VERSION ""

NS_ :

BS_:

BU_: WCM4 WCM3 WCM2 WCM VPM VLM VKM VICM VECM VDM VCU_RTOS_ETH VCU_ENTRY_ETH VCU_AGVM_ETH VCU UVM UPM TIM TEST_TOOL_1 TCP_ETH TCP TCM TCCM SRR_SRR_ETH SRR_SRR SRR_SLR_ETH SRR_SLR SRR_RR SRR_RF_ETH SRR_RF SRR_LR_CR SRR_LF_ETH SRR_LF SIB SDM SCL SBZA_R SBZA_L SBM SAM_RR SAM_RF SAM_LR SAM_LF SAM_BH SADS RadioLow_ETH RadioLow RSI_RTOS_ETH RSI RDCM PTM PLCM PFCM PDR_ETH PDR PCM PA ODS2 ODS NVM MTCM_R MTCM_L MSM_RR MSM_P MSM_LR MSM_D MSB2 MSB1 MRCM_R MRCM_L MFC LRR_RR_ETH LRR_LR_ETH LRR_CF_ETH LRR LRL_CF_ETH LIB_48V LIB1 IPC_INT IPC_GP IPC ICS_Info ICCM HVAC_FP_R HVAC_FP_F HUD_CAN HDLM FPI_RTOS_ETH FPI FOPM FCM_LC FCM EPSb EPS_1 EPSRAb EPSRAa EPS EOCM_HC_Superset EOCM_HCP2 EOCM ELM ECP_X1 ECP_S2 ECP_S ECP_MC ECP_H3 ECP_H2 ECP_H1 ECP_E ECM EBCM DMS DEFC DCM CSM_ETH CSM_AV CSM CGM_OTA_ETH CGM BSM_MH BSM_HEV BSM BCM ARS ARB APA AOS AMP ALC AHS AHL_AFL ADIMb ADIMa ACP2_MCU

BO_ 1940 PDU_4087: 8 CGM
 SG_ StCushFrtVertRRVirtCtlAval : 0|1@0+ (1,0) [0|1] "" VCU
 SG_ StBkSdBolsRRVirtCtlAval : 1|1@0+ (1,0) [0|1] "" VCU
 SG_ StBkLumbVertRRVirtCtlAval : 2|1@0+ (1,0) [0|1] "" VCU
 SG_ StBkLumbHrztlRRVirtCtlAval : 3|1@0+ (1,0) [0|1] "" VCU
 SG_ StBkHrztlRRVirtCtlAval : 4|1@0+ (1,0) [0|1] "" VCU
 SG_ StMasgIntstyRRVirtCtlMaxLvl : 7|3@0+ (1,0) [0|7] "" VCU
 SG_ StMasgTyp11RRVirtCtlAval : 8|1@0+ (1,0) [0|1] "" VCU
 SG_ StMasgTyp10RRVirtCtlAval : 9|1@0+ (1,0) [0|1] "" VCU
 SG_ StHdrstVertRRVirtCtlAval : 10|1@0+ (1,0) [0|1] "" VCU
 SG_ StHdrstHrztlRRVirtCtlAval : 11|1@0+ (1,0) [0|1] "" VCU
 SG_ StCushSdBolsRRVirtCtlAval : 12|1@0+ (1,0) [0|1] "" VCU
 SG_ StCushRrVertRRVirtCtlAval : 13|1@0+ (1,0) [0|1] "" VCU
 SG_ StCushLgthHrztlRRVirtCtlAval : 14|1@0+ (1,0) [0|1] "" VCU
 SG_ StCushHrztlRRVirtCtlAval : 15|1@0+ (1,0) [0|1] "" VCU
 SG_ StMasgTyp4RRVirtCtlAval : 16|1@0+ (1,0) [0|1] "" VCU
 SG_ StMasgTyp3RRVirtCtlAval : 17|1@0+ (1,0) [0|1] "" VCU
 SG_ StMasgTyp2RRVirtCtlAval : 18|1@0+ (1,0) [0|1] "" VCU
 SG_ StMasgTyp1RRVirtCtlAval : 19|1@0+ (1,0) [0|1] "" VCU
 SG_ StMasgTyp15RRVirtCtlAval : 20|1@0+ (1,0) [0|1] "" VCU
 SG_ StMasgTyp14RRVirtCtlAval : 21|1@0+ (1,0) [0|1] "" VCU
 SG_ StMasgTyp13RRVirtCtlAval : 22|1@0+ (1,0) [0|1] "" VCU
 SG_ StMasgTyp12RRVirtCtlAval : 23|1@0+ (1,0) [0|1] "" VCU
 SG_ StBkLumbHrztlRRVirtCtlAllwd : 24|1@0+ (1,0) [0|1] "" VCU
 SG_ StBkHrztlRRVirtCtlAllwd : 25|1@0+ (1,0) [0|1] "" VCU
 SG_ StUpprShldrHrztlRRVirtCtlAval : 26|1@0+ (1,0) [0|1] "" VCU
 SG_ StMasgTyp9RRVirtCtlAval : 27|1@0+ (1,0) [0|1] "" VCU
 SG_ StMasgTyp8RRVirtCtlAval : 28|1@0+ (1,0) [0|1] "" VCU
 SG_ StMasgTyp7RRVirtCtlAval : 29|1@0+ (1,0) [0|1] "" VCU
 SG_ StMasgTyp6RRVirtCtlAval : 30|1@0+ (1,0) [0|1] "" VCU
 SG_ StMasgTyp5RRVirtCtlAval : 31|1@0+ (1,0) [0|1] "" VCU
 SG_ StHdrstHrztlRRVirtCtlAllwd : 32|1@0+ (1,0) [0|1] "" VCU
 SG_ StCushSdBolsRRVirtCtlAllwd : 33|1@0+ (1,0) [0|1] "" VCU
 SG_ StCushRrVertRRVirtCtlAllwd : 34|1@0+ (1,0) [0|1] "" VCU
 SG_ StCushLgthHrztlRRVirtCtlAllwd : 35|1@0+ (1,0) [0|1] "" VCU
 SG_ StCushHrztlRRVirtCtlAllwd : 36|1@0+ (1,0) [0|1] "" VCU
 SG_ StCushFrtVertRRVirtCtlAllwd : 37|1@0+ (1,0) [0|1] "" VCU
 SG_ StBkSdBolsRRVirtCtlAllwd : 38|1@0+ (1,0) [0|1] "" VCU
 SG_ StBkLumbVertRRVirtCtlAllwd : 39|1@0+ (1,0) [0|1] "" VCU
 SG_ StMasgIntstyRRLstKnwnSet : 40|3@0+ (1,0) [0|7] "" VCU
 SG_ StMasgTypRRLstKnwnSet : 44|4@0+ (1,0) [0|15] "" VCU
 SG_ StUpprShldrHrztlRRVirtCtlAllwd : 45|1@0+ (1,0) [0|1] "" VCU
 SG_ StMasgRRVirtCtlAllwd : 46|1@0+ (1,0) [0|1] "" VCU
 SG_ StHdrstVertRRVirtCtlAllwd : 47|1@0+ (1,0) [0|1] "" VCU
 SG_ StMemRRVirtCtlNumofMemPstnsAval : 49|4@0+ (1,0) [0|8] "" VCU
 SG_ StMemRRVirtCtlNumofExtPstnsAval : 53|4@0+ (1,0) [0|8] "" VCU

BO_ 1964 PDU_4088: 8 CGM
 SG_ StCushFrtVertLRVirtCtlAval : 0|1@0+ (1,0) [0|1] "" VCU
 SG_ StBkSdBolsLRVirtCtlAval : 1|1@0+ (1,0) [0|1] "" VCU
 SG_ StBkLumbVertLRVirtCtlAval : 2|1@0+ (1,0) [0|1] "" VCU
 SG_ StBkLumbHrztlLRVirtCtlAval : 3|1@0+ (1,0) [0|1] "" VCU
 SG_ StBkHrztlLRVirtCtlAval : 4|1@0+ (1,0) [0|1] "" VCU
 SG_ StMasgIntstyLRVirtCtlMaxLvl : 7|3@0+ (1,0) [0|7] "" VCU
 SG_ StMasgTyp11LRVirtCtlAval : 8|1@0+ (1,0) [0|1] "" VCU
 SG_ StMasgTyp10LRVirtCtlAval : 9|1@0+ (1,0) [0|1] "" VCU
 SG_ StHdrstVertLRVirtCtlAval : 10|1@0+ (1,0) [0|1] "" VCU
 SG_ StHdrstHrztlLRVirtCtlAval : 11|1@0+ (1,0) [0|1] "" VCU
 SG_ StCushSdBolsLRVirtCtlAval : 12|1@0+ (1,0) [0|1] "" VCU
 SG_ StCushRrVertLRVirtCtlAval : 13|1@0+ (1,0) [0|1] "" VCU
 SG_ StCushLgthHrztlLRVirtCtlAval : 14|1@0+ (1,0) [0|1] "" VCU
 SG_ StCushHrztlLRVirtCtlAval : 15|1@0+ (1,0) [0|1] "" VCU
 SG_ StMasgTyp4LRVirtCtlAval : 16|1@0+ (1,0) [0|1] "" VCU
 SG_ StMasgTyp3LRVirtCtlAval : 17|1@0+ (1,0) [0|1] "" VCU
 SG_ StMasgTyp2LRVirtCtlAval : 18|1@0+ (1,0) [0|1] "" VCU
 SG_ StMasgTyp1LRVirtCtlAval : 19|1@0+ (1,0) [0|1] "" VCU
 SG_ StMasgTyp15LRVirtCtlAval : 20|1@0+ (1,0) [0|1] "" VCU
 SG_ StMasgTyp14LRVirtCtlAval : 21|1@0+ (1,0) [0|1] "" VCU
 SG_ StMasgTyp13LRVirtCtlAval : 22|1@0+ (1,0) [0|1] "" VCU
 SG_ StMasgTyp12LRVirtCtlAval : 23|1@0+ (1,0) [0|1] "" VCU
 SG_ StMemLRVirtCtlNumofExtPstnsAval : 25|4@0+ (1,0) [0|8] "" VCU
 SG_ StUpprShldrHrztlLRVirtCtlAval : 26|1@0+ (1,0) [0|1] "" VCU
 SG_ StMasgTyp9LRVirtCtlAval : 27|1@0+ (1,0) [0|1] "" VCU
 SG_ StMasgTyp8LRVirtCtlAval : 28|1@0+ (1,0) [0|1] "" VCU
 SG_ StMasgTyp7LRVirtCtlAval : 29|1@0+ (1,0) [0|1] "" VCU
 SG_ StMasgTyp6LRVirtCtlAval : 30|1@0+ (1,0) [0|1] "" VCU
 SG_ StMasgTyp5LRVirtCtlAval : 31|1@0+ (1,0) [0|1] "" VCU
 SG_ RrDrOpnCmfRclCstAvlFlg2 : 32|1@0+ (1,0) [0|1] "" VCU
 SG_ RrDrOpnCmfRclCstAvlFlg1 : 33|1@0+ (1,0) [0|1] "" VCU
 SG_ StMemLRVirtCtlNumofMemPstnsAval : 37|4@0+ (1,0) [0|8] "" VCU
 SG_ RrDrOpnCmfRclCstSetAval : 42|1@0+ (1,0) [0|1] "" VCU
 SG_ RrDrOpnCmfRclCstAvlFlg7 : 43|1@0+ (1,0) [0|1] "" VCU
 SG_ RrDrOpnCmfRclCstAvlFlg6 : 44|1@0+ (1,0) [0|1] "" VCU
 SG_ RrDrOpnCmfRclCstAvlFlg5 : 45|1@0+ (1,0) [0|1] "" VCU
 SG_ RrDrOpnCmfRclCstAvlFlg4 : 46|1@0+ (1,0) [0|1] "" VCU
 SG_ RrDrOpnCmfRclCstAvlFlg3 : 47|1@0+ (1,0) [0|1] "" VCU

BO_ 1295 PDU_4089: 8 CGM
 SG_ SCAOOAByVirtKeyRFCstCurrSetVal : 4|3@0+ (1,0) [0|2] "" VKM,VCU
 SG_ SCAOOAByKeyFobRFCstCurrSetVal : 7|3@0+ (1,0) [0|2] "" VCU

BO_ 1058 PDU_4091: 8 CGM
 SG_ PwrSdClsrRRBlckdIndOn : 0|1@0+ (1,0) [0|1] "" VCU
 SG_ PwrSdClsrRRServIndOn : 15|1@0+ (1,0) [0|1] "" VCU

BO_ 1406 PDU_5000: 8 AMP
 SG_ ASS_DSPMd6Prsnt : 0|1@0+ (1,0) [0|1] "" CSM,CSM_AV,VCU
 SG_ ASS_DSPMd5Prsnt : 1|1@0+ (1,0) [0|1] "" CSM,CSM_AV,VCU
 SG_ ASS_DSPMd4Prsnt : 2|1@0+ (1,0) [0|1] "" CSM,CSM_AV,VCU
 SG_ ASS_DSPMd3Prsnt : 3|1@0+ (1,0) [0|1] "" CSM,CSM_AV,VCU
 SG_ ASS_DSPMd2Prsnt : 4|1@0+ (1,0) [0|1] "" CSM,CSM_AV,VCU
 SG_ ASS_DSPMd1Prsnt : 5|1@0+ (1,0) [0|1] "" CSM,CSM_AV,VCU
 SG_ ASS_DSPMd0Prsnt : 6|1@0+ (1,0) [0|1] "" CSM,CSM_AV,VCU
 SG_ ASS_DSPAvail : 7|1@0+ (1,0) [0|1] "" CSM,CSM_AV,VCU
 SG_ CrtclChmPrdcrStat : 10|12@0+ (1,0) [0|4095] "msec" RadioLow,CSM,CSM_AV,IPC,IPC_INT,VCU
 SG_ ASS_VehNoisCmpnAvail : 11|1@0+ (1,0) [0|1] "" CSM,CSM_AV,VCU
 SG_ ASS_SurndAvail : 12|1@0+ (1,0) [0|1] "" CSM,CSM_AV,VCU
 SG_ ASS_PhLckdLpLckd : 13|1@0+ (1,0) [0|1] "" CSM,CSM_AV,VCU
 SG_ ASS_MtxSnkMutStat : 14|1@0+ (1,0) [0|1] "" CSM,CSM_AV,VCU
 SG_ ASS_DSPMd7Prsnt : 15|1@0+ (1,0) [0|1] "" CSM,CSM_AV,VCU
 SG_ FrtPsngrMtxSnkMutSts : 24|1@0+ (1,0) [0|1] "" CSM,CSM_AV,VCU
 SG_ CCSI_PV : 26|2@0+ (1,0) [0|3] "" IPC,IPC_INT,VCU
 SG_ CCSI_CrtclChmPrdcrSOH : 28|2@0+ (1,0) [0|2] "" IPC,IPC_INT,VCU
 SG_ CCSI_ARC : 30|2@0+ (1,0) [0|3] "" IPC,IPC_INT,VCU
 SG_ AmpSOHALAudblFbkSnkLvlCurrVal : 35|8@0+ (0.5,-127.5) [-127.5|0] "dB" VCU
 SG_ AmpCallAudPlybkSOH : 37|2@0+ (1,0) [0|2] "" VCU
 SG_ RRMtxSnkMutSts : 38|1@0+ (1,0) [0|1] "" CSM,CSM_AV,VCU
 SG_ LRMtxSnkMutSts : 39|1@0+ (1,0) [0|1] "" CSM,CSM_AV,VCU
 SG_ AmpSOHALMixPrmtSnkLvlCurrVal : 43|8@0+ (0.5,-127.5) [-127.5|0] "dB" VCU
 SG_ AmpSOHALMtxSnkLvlCurrVal : 51|8@0+ (0.5,-127.5) [-127.5|0] "dB" VCU
 SG_ AmpSOHALAutoLdnsCmpnAtv : 56|1@0+ (1,0) [0|1] "" VCU
 SG_ AmpSOHALMutCaus : 59|3@0+ (1,0) [0|3] "" VCU

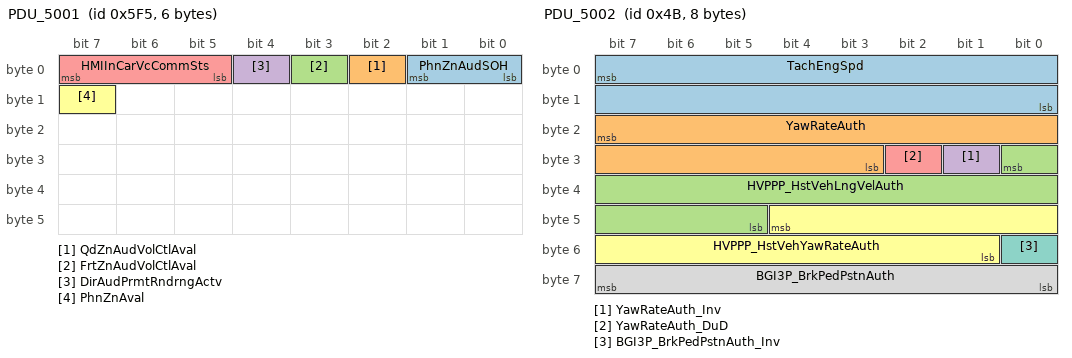
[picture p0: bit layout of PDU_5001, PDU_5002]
BO_ 1525 PDU_5001: 6 AMP
 SG_ PhnZnAudSOH : 1|2@0+ (1,0) [0|2] "" VCU
 SG_ QdZnAudVolCtlAval : 2|1@0+ (1,0) [0|1] "" VCU
 SG_ FrtZnAudVolCtlAval : 3|1@0+ (1,0) [0|1] "" VCU
 SG_ DirAudPrmtRndrngActv : 4|1@0+ (1,0) [0|1] "" CSM,CSM_AV,VCU
 SG_ HMIInCarVcCommSts : 7|3@0+ (1,0) [0|7] "" CSM,CSM_AV,VCU
 SG_ PhnZnAval : 15|1@0+ (1,0) [0|1] "" VCU

BO_ 75 PDU_5002: 8 CGM
 SG_ TachEngSpd : 7|16@0+ (0.25,0) [0|16383.8] "RPM" AMP,IPC,IPC_INT,VCU
 SG_ YawRateAuth : 23|13@0- (0.024,0) [-98.304|98.28] "Deg/Sec" PDR,TCP,CSM,CSM_AV,IPC,VCU
 SG_ HVPPP_HstVehLngVelAuth : 24|12@0+ (0.0625,-128) [-128|127.938] "m/s" CSM,CSM_AV,VCU
 SG_ YawRateAuth_Inv : 25|1@0+ (1,0) [0|1] "" PDR,TCP,CSM,CSM_AV,IPC,VCU
 SG_ YawRateAuth_DuD : 26|1@0+ (1,0) [0|1] "" TCP,CSM,CSM_AV,VCU
 SG_ HVPPP_HstVehYawRateAuth : 44|12@0+ (0.0625,-128) [-128|127.938] "deg/s" CSM,CSM_AV,VCU
 SG_ BGI3P_BrkPedPstnAuth_Inv : 48|1@0+ (1,0) [0|1] "" PDR,CSM,CSM_AV,VCU
 SG_ BGI3P_BrkPedPstnAuth : 63|8@0+ (0.392157,0) [0|100] "%" PDR,CSM,CSM_AV,VCU

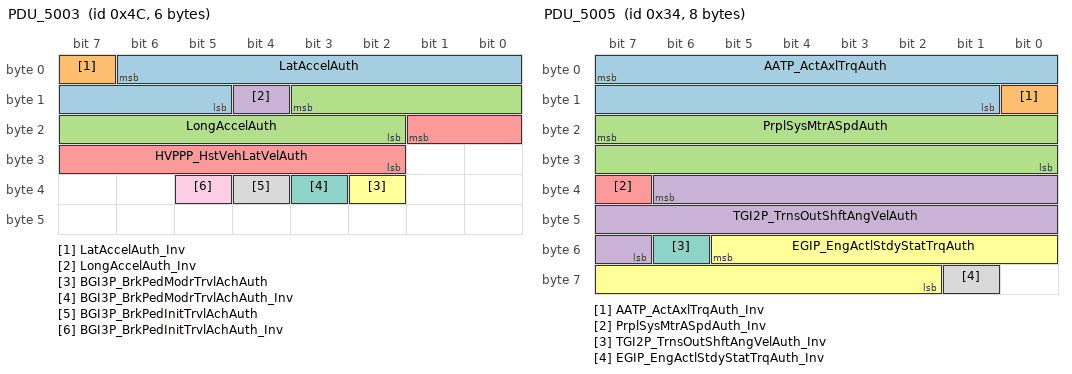
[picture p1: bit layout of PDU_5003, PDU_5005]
BO_ 76 PDU_5003: 6 CGM
 SG_ LatAccelAuth : 6|10@0- (0.0625,0) [-32|31.9375] "m/s^2" PDR,TCP,VKM,CSM,CSM_AV,IPC,VCU
 SG_ LatAccelAuth_Inv : 7|1@0+ (1,0) [0|1] "" PDR,TCP,VKM,CSM,CSM_AV,IPC,VCU
 SG_ LongAccelAuth : 11|10@0- (0.0625,0) [-32|31.9375] "m/s^2" AMP,PDR,TCP,CSM,CSM_AV,IPC,VCU
 SG_ LongAccelAuth_Inv : 12|1@0+ (1,0) [0|1] "" PDR,TCP,CSM,CSM_AV,IPC,VCU
 SG_ HVPPP_HstVehLatVelAuth : 17|8@0+ (0.05,-6.4) [-6.4|6.35] "m/s" CSM,CSM_AV,VCU
 SG_ BGI3P_BrkPedModrTrvlAchAuth : 34|1@0+ (1,0) [0|1] "" VKM,CSM,CSM_AV,VCU
 SG_ BGI3P_BrkPedModrTrvlAchAuth_Inv : 35|1@0+ (1,0) [0|1] "" VKM,CSM,CSM_AV,VCU
 SG_ BGI3P_BrkPedInitTrvlAchAuth : 36|1@0+ (1,0) [0|1] "" TCP,VKM,CSM,CSM_AV,VCU
 SG_ BGI3P_BrkPedInitTrvlAchAuth_Inv : 37|1@0+ (1,0) [0|1] "" VKM,CSM,CSM_AV,VCU

BO_ 41 PDU_5004: 8 CGM
 SG_ VCBA_FrtJnctnActv : 0|1@0+ (1,0) [0|1] "" CSM,CSM_AV,VCU
 SG_ VCBA_DynGdlnsActv : 1|1@0+ (1,0) [0|1] "" CSM,CSM_AV,VCU
 SG_ VCBA_CurbVwGdlnsActv : 2|1@0+ (1,0) [0|1] "" CSM,CSM_AV,VCU
 SG_ VCBA_CurbOvrhdActv : 3|1@0+ (1,0) [0|1] "" CSM,CSM_AV,VCU
 SG_ VCBA_CurbActv : 4|1@0+ (1,0) [0|1] "" CSM,CSM_AV,VCU
 SG_ VCBA_CrgBedActv : 5|1@0+ (1,0) [0|1] "" CSM,CSM_AV,VCU
 SG_ VCBA_BowlActv : 6|1@0+ (1,0) [0|1] "" CSM,CSM_AV,VCU
 SG_ VCBA_BedHtchActv : 7|1@0+ (1,0) [0|1] "" CSM,CSM_AV,VCU
 SG_ VCBA_RrOvrhdActv : 8|1@0+ (1,0) [0|1] "" CSM,CSM_AV,VCU
 SG_ VCBA_RrJnctnActv : 9|1@0+ (1,0) [0|1] "" CSM,CSM_AV,VCU
 SG_ VCBA_RrHtchActv : 10|1@0+ (1,0) [0|1] "" CSM,CSM_AV,VCU
 SG_ VCBA_LRTrlrTowMirActv : 11|1@0+ (1,0) [0|1] "" CSM,CSM_AV,VCU
 SG_ VCBA_JPActv : 12|1@0+ (1,0) [0|1] "" CSM,CSM_AV,VCU
 SG_ VCBA_InvsblTrlrActv : 13|1@0+ (1,0) [0|1] "" CSM,CSM_AV,VCU
 SG_ VCBA_FrtPrspctvActv : 14|1@0+ (1,0) [0|1] "" CSM,CSM_AV,VCU
 SG_ VCBA_FrtOvrhdActv : 15|1@0+ (1,0) [0|1] "" CSM,CSM_AV,VCU
 SG_ VCBA_TrlrTowMirActv : 16|1@0+ (1,0) [0|1] "" CSM,CSM_AV,VCU
 SG_ VCBA_TrlrGdlnsActv : 17|1@0+ (1,0) [0|1] "" CSM,CSM_AV,VCU
 SG_ VCBA_TrlrAux2Actv : 18|1@0+ (1,0) [0|1] "" CSM,CSM_AV,VCU
 SG_ VCBA_TrlrAux1CmbdActv : 19|1@0+ (1,0) [0|1] "" CSM,CSM_AV,VCU
 SG_ VCBA_TrlrAux1Actv : 20|1@0+ (1,0) [0|1] "" CSM,CSM_AV,VCU
 SG_ VCBA_SdRrwdActv : 21|1@0+ (1,0) [0|1] "" CSM,CSM_AV,VCU
 SG_ VCBA_SdFrwdActv : 22|1@0+ (1,0) [0|1] "" CSM,CSM_AV,VCU
 SG_ VCBA_RrPrspctvActv : 23|1@0+ (1,0) [0|1] "" CSM,CSM_AV,VCU
 SG_ VwgBowlVwAngSts : 29|9@0+ (1,0) [0|511] "degrees" CSM,CSM_AV,VCU
 SG_ VCBA_ZmdBowlActv : 30|1@0+ (1,0) [0|1] "" CSM,CSM_AV,VCU
 SG_ VCBA_TrnspHdActv : 31|1@0+ (1,0) [0|1] "" CSM,CSM_AV,VCU
 SG_ SrrndVsnRcrdrNumDispdFiles : 33|3@0+ (1,0) [0|7] "" CSM,CSM_AV,VCU
 SG_ SrrndVsnRcrdrDelFileReqSts : 36|3@0+ (1,0) [0|7] "" CSM,CSM_AV,VCU
 SG_ SrrndVsnRcrdrVwprtSts : 40|3@0+ (1,0) [0|7] "" CSM,CSM_AV,VCU
 SG_ SrrndVsnRcrdrVwprtReq : 43|3@0+ (1,0) [0|7] "" CSM,CSM_AV,VCU
 SG_ SrrndVsnRcrdrPlybkSts : 46|3@0+ (1,0) [0|5] "" CSM,CSM_AV,VCU
 SG_ SrrndVsnRcrdrRcrdSts : 48|2@0+ (1,0) [0|2] "" CSM,CSM_AV,VCU
 SG_ SrrndVsnRcrdrListPgSts : 50|2@0+ (1,0) [0|3] "" CSM,CSM_AV,VCU
 SG_ VGVS_TrlrActv : 51|1@0+ (1,0) [0|1] "" CSM,CSM_AV,VCU
 SG_ VGVS_DynActv : 52|1@0+ (1,0) [0|1] "" CSM,CSM_AV,VCU
 SG_ VGVS_CurbVwActv : 53|1@0+ (1,0) [0|1] "" CSM,CSM_AV,VCU
 SG_ SrrndVsnRcrdrRcrdgActv : 59|1@0+ (1,0) [0|1] "" CSM,CSM_AV,VCU
 SG_ ClsnEvntDatRcrdgTrgrd : 60|1@0+ (1,0) [0|1] "" TCP
 SG_ SVRCBA_PgUpActv : 61|1@0+ (1,0) [0|1] "" CSM,CSM_AV,VCU
 SG_ SVRCBA_PgDnActv : 62|1@0+ (1,0) [0|1] "" CSM,CSM_AV,VCU

BO_ 52 PDU_5005: 8 CGM
 SG_ AATP_ActAxlTrqAuth : 7|15@0+ (2,-22534) [-22534|43000] "Nm" AMP,CSM,CSM_AV,VCU
 SG_ AATP_ActAxlTrqAuth_Inv : 8|1@0+ (1,0) [0|1] "" AMP,CSM,CSM_AV,VCU
 SG_ PrplSysMtrASpdAuth : 23|16@0- (1,0) [-32768|32767] "RPM" AMP,VCU
 SG_ TGI2P_TrnsOutShftAngVelAuth : 38|16@0+ (0.25,0) [0|16383.8] "rpm" AMP,RadioLow,VCU
 SG_ PrplSysMtrASpdAuth_Inv : 39|1@0+ (1,0) [0|1] "" AMP,VCU
 SG_ EGIP_EngActlStdyStatTrqAuth : 53|12@0+ (0.5,-848) [-848|1199.5] "Nm" AMP,PDR,RadioLow,CSM,CSM_AV,IPC,IPC_INT,VCU
 SG_ TGI2P_TrnsOutShftAngVelAuth_Inv : 54|1@0+ (1,0) [0|1] "" AMP,VCU
 SG_ EGIP_EngActlStdyStatTrqAuth_Inv : 57|1@0+ (1,0) [0|1] "" AMP,PDR,CSM,CSM_AV,IPC,IPC_INT,VCU

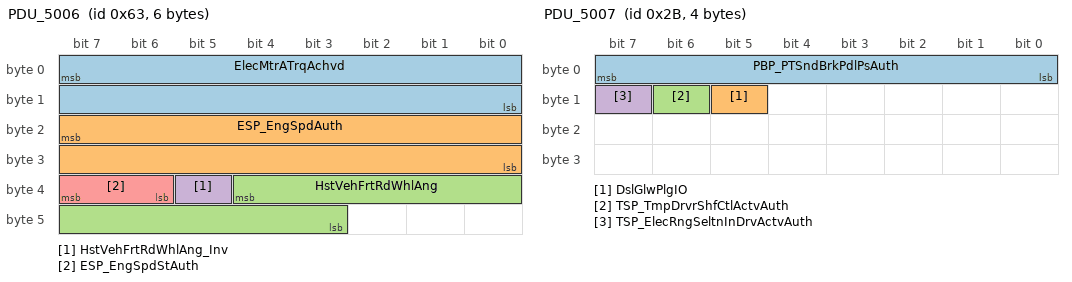
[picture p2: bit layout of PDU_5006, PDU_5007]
BO_ 99 PDU_5006: 6 CGM
 SG_ ElecMtrATrqAchvd : 7|16@0- (0.125,0) [-4096|4095.88] "Nm" AMP,VCU
 SG_ ESP_EngSpdAuth : 23|16@0+ (0.25,0) [0|16383.8] "rpm" AMP,PDR,RadioLow,TCP,CSM,CSM_AV,IPC,IPC_INT,VCU
 SG_ HstVehFrtRdWhlAng : 36|10@0- (0.004363,0) [-2.23386|2.22949] "Rad" RadioLow,CSM,VCU
 SG_ HstVehFrtRdWhlAng_Inv : 37|1@0+ (1,0) [0|1] "" RadioLow,CSM,VCU
 SG_ ESP_EngSpdStAuth : 39|2@0+ (1,0) [0|2] "" AMP,RadioLow,CSM,CSM_AV,IPC,IPC_INT,VCU

BO_ 43 PDU_5007: 4 CGM
 SG_ PBP_PTSndBrkPdlPsAuth : 7|8@0+ (0.392157,0) [0|100] "%" TCP
 SG_ DslGlwPlgIO : 13|1@0+ (1,0) [0|1] "" CSM,CSM_AV,IPC,IPC_INT,VCU
 SG_ TSP_TmpDrvrShfCtlActvAuth : 14|1@0+ (1,0) [0|1] "" IPC,IPC_INT,VCU
 SG_ TSP_ElecRngSeltnInDrvActvAuth : 15|1@0+ (1,0) [0|1] "" IPC,IPC_INT,VCU

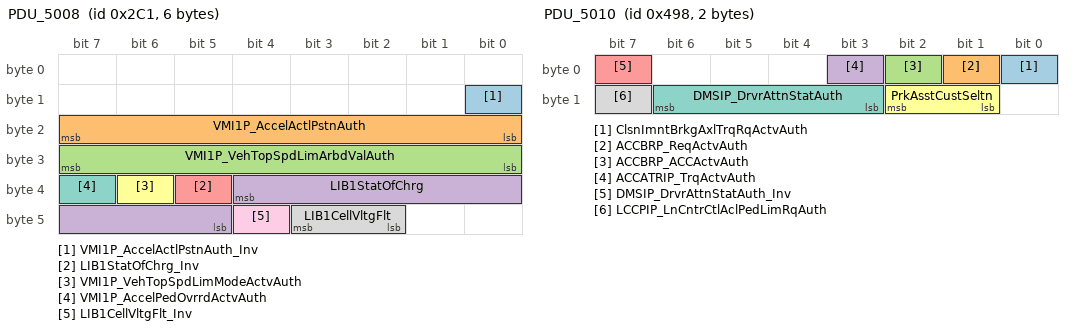
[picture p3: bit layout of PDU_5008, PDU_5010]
BO_ 705 PDU_5008: 6 CGM
 SG_ VMI1P_AccelActlPstnAuth_Inv : 8|1@0+ (1,0) [0|1] "" AMP,PDR,CSM,CSM_AV,VCU
 SG_ VMI1P_AccelActlPstnAuth : 23|8@0+ (0.392157,0) [0|100] "%" AMP,PDR,TCP,CSM,CSM_AV,VCU
 SG_ VMI1P_VehTopSpdLimArbdValAuth : 31|8@0+ (2,0) [0|510] "km / h" CSM,CSM_AV,IPC,IPC_INT,VCU
 SG_ LIB1StatOfChrg : 36|8@0+ (0.39,0) [0|99.45] "%" CSM,VCU
 SG_ LIB1StatOfChrg_Inv : 37|1@0+ (1,0) [0|1] "" CSM,VCU
 SG_ VMI1P_VehTopSpdLimModeActvAuth : 38|1@0+ (1,0) [0|1] "" CSM,CSM_AV,IPC,IPC_INT,VCU
 SG_ VMI1P_AccelPedOvrrdActvAuth : 39|1@0+ (1,0) [0|1] "" CSM,CSM_AV,IPC,IPC_INT,VCU
 SG_ LIB1CellVltgFlt : 43|2@0+ (1,0) [0|3] "" CSM,VCU
 SG_ LIB1CellVltgFlt_Inv : 44|1@0+ (1,0) [0|1] "" CSM,VCU

BO_ 204 PDU_5009: 4 CGM
 SG_ RdLdNomAxlTrq : 7|19@0+ (0.125,-22534) [-22534|43001.9] "Nm" CSM,CSM_AV,VCU

BO_ 1176 PDU_5010: 2 CGM
 SG_ ClsnImntBrkgAxlTrqRqActvAuth : 0|1@0+ (1,0) [0|1] "" TCP
 SG_ ACCBRP_ReqActvAuth : 1|1@0+ (1,0) [0|1] "" TCP
 SG_ ACCBRP_ACCActvAuth : 2|1@0+ (1,0) [0|1] "" IPC,IPC_INT,VCU
 SG_ ACCATRIP_TrqActvAuth : 3|1@0+ (1,0) [0|1] "" TCP
 SG_ DMSIP_DrvrAttnStatAuth_Inv : 7|1@0+ (1,0) [0|1] "" TCP
 SG_ PrkAsstCustSeltn : 10|2@0+ (1,0) [0|2] "" VCU
 SG_ DMSIP_DrvrAttnStatAuth : 14|4@0+ (1,0) [0|11] "" TCP
 SG_ LCCPIP_LnCntrCtlAclPedLimRqAuth : 15|1@0+ (1,0) [0|1] "" TCP

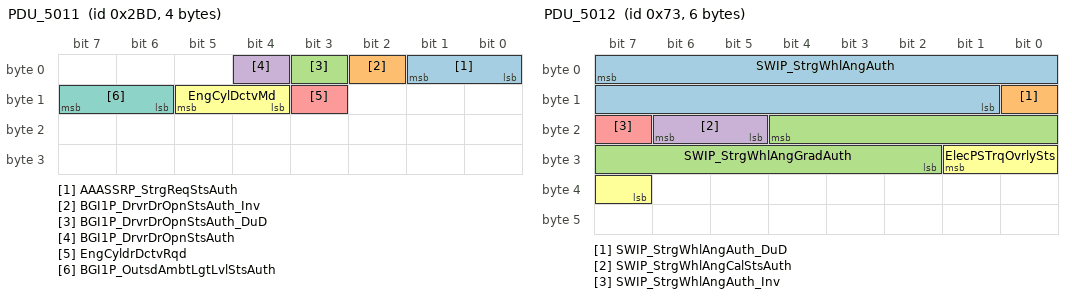
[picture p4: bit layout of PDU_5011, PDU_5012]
BO_ 701 PDU_5011: 4 CGM
 SG_ AAASSRP_StrgReqStsAuth : 1|2@0+ (1,0) [0|2] "" TCP
 SG_ BGI1P_DrvrDrOpnStsAuth_Inv : 2|1@0+ (1,0) [0|1] "" TCP,CSM,CSM_AV,VCU
 SG_ BGI1P_DrvrDrOpnStsAuth_DuD : 3|1@0+ (1,0) [0|1] "" CSM,CSM_AV,VCU
 SG_ BGI1P_DrvrDrOpnStsAuth : 4|1@0+ (1,0) [0|1] "" TCP,CSM,CSM_AV,VCU
 SG_ EngCyldrDctvRqd : 11|1@0+ (1,0) [0|1] "" RadioLow,VCU
 SG_ EngCylDctvMd : 13|2@0+ (1,0) [0|3] "" AMP,RadioLow,CSM,CSM_AV,IPC,IPC_INT,VCU
 SG_ BGI1P_OutsdAmbtLgtLvlStsAuth : 15|2@0+ (1,0) [0|2] "" CSM,CSM_AV,IPC,IPC_INT,VCU

BO_ 115 PDU_5012: 6 CGM
 SG_ SWIP_StrgWhlAngAuth : 7|15@0- (0.0625,0) [-1024|1023.94] "deg" PDR,RadioLow,TCP,VKM,CSM,CSM_AV,VCU
 SG_ SWIP_StrgWhlAngAuth_DuD : 8|1@0+ (1,0) [0|1] "" PDR,RadioLow,TCP,VKM,CSM,VCU
 SG_ SWIP_StrgWhlAngGradAuth : 20|11@0- (2,0) [-2048|2046] "deg/s" TCP,VKM,CSM,CSM_AV,VCU
 SG_ SWIP_StrgWhlAngCalStsAuth : 22|2@0+ (1,0) [0|2] "" RadioLow,TCP,VKM,CSM,CSM_AV,VCU
 SG_ SWIP_StrgWhlAngAuth_Inv : 23|1@0+ (1,0) [0|1] "" PDR,RadioLow,TCP,VKM,CSM,VCU
 SG_ ElecPSTrqOvrlySts : 25|3@0+ (1,0) [0|5] "" TCP

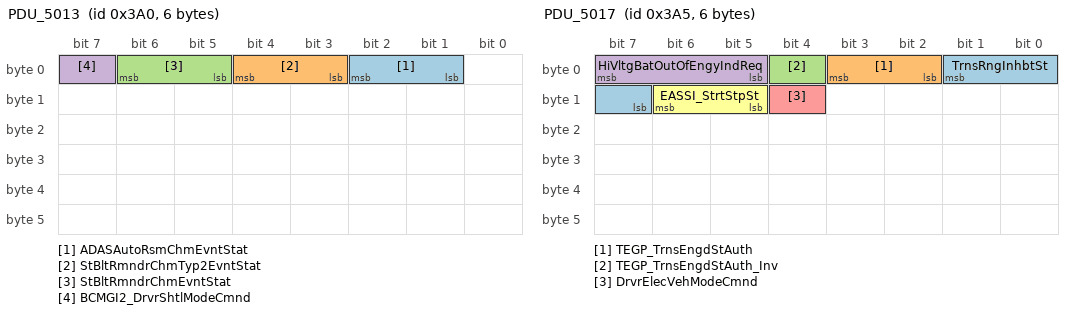
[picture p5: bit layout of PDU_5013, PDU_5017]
BO_ 928 PDU_5013: 6 CGM
 SG_ ADASAutoRsmChmEvntStat : 2|2@0+ (1,0) [0|2] "" IPC,IPC_INT,VCU
 SG_ StBltRmndrChmTyp2EvntStat : 4|2@0+ (1,0) [0|2] "" CSM,CSM_AV,IPC,IPC_INT,VCU
 SG_ StBltRmndrChmEvntStat : 6|2@0+ (1,0) [0|2] "" CSM,CSM_AV,IPC,IPC_INT,VCU
 SG_ BCMGI2_DrvrShtlModeCmnd : 7|1@0+ (1,0) [0|1] "" AMP,CSM,CSM_AV,IPC,IPC_INT,VCU

BO_ 703 PDU_5014: 8 CGM
 SG_ BVSCRP_CPSAxlTrqCmdReqStsAuth : 0|3@0+ (1,0) [0|6] "" CSM,CSM_AV,IPC,IPC_INT,VCU
 SG_ BVSCRP_CPSAxlTrqCmdLimStsAuth : 2|2@0+ (1,0) [0|3] "" CSM,CSM_AV,IPC,IPC_INT,VCU
 SG_ BVSCRP_ACCAxlTrqCmdReqStsAuth : 5|3@0+ (1,0) [0|4] "" TCP,CSM,CSM_AV,IPC,IPC_INT,VCU
 SG_ BVSCRP_ACCAxlTrqCmdLimStsAuth : 7|2@0+ (1,0) [0|3] "" CSM,CSM_AV,IPC,IPC_INT,VCU
 SG_ BVSCRP_CltchPdlActPosAuth : 13|8@0+ (0.392157,0) [0|100] "" AMP,PDR,TCP,CSM,CSM_AV,IPC,IPC_INT,VCU
 SG_ CruzCtlActvAuth : 16|1@0+ (1,0) [0|1] "" CSM,CSM_AV,IPC,IPC_INT,VCU
 SG_ CnvntlCruzCtlIndReqAuth : 19|3@0+ (1,0) [0|5] "" CSM,CSM_AV,IPC,IPC_INT,VCU
 SG_ BVSCRP_CruzCtlEnbldAuth : 20|1@0+ (1,0) [0|1] "" CSM,CSM_AV,IPC,IPC_INT,VCU
 SG_ BVSCRP_CltchPdlActPosAuth_Inv : 21|1@0+ (1,0) [0|1] "" AMP,PDR,TCP,CSM,CSM_AV,IPC,IPC_INT,VCU
 SG_ CruzSpdLmtrDrvrSeltdSpdAuth : 31|12@0+ (0.0625,0) [0|255.938] "km / h" CSM,CSM_AV,IPC,IPC_INT,VCU
 SG_ DrSeltdSpdLmtrSetSpdLimRchdAuth : 33|2@0+ (1,0) [0|3] "" TCP,CSM,CSM_AV,IPC,IPC_INT,VCU
 SG_ DrSeltdSpdLmtrAutoMdSpLmStsAuth : 35|2@0+ (1,0) [0|3] "" TCP,CSM,CSM_AV,IPC,IPC_INT,VCU
 SG_ SpdLmtrSpdLimSgnValAuth : 41|8@0+ (1,0) [0|255] "" CSM,CSM_AV,IPC,IPC_INT,VCU
 SG_ SpdLmtrSpdLimSgnUntAuth : 42|1@0+ (1,0) [0|1] "" CSM,CSM_AV,IPC,IPC_INT,VCU
 SG_ PABRP_VehTopSpdLimArbdStatAuth : 44|2@0+ (1,0) [0|2] "" CSM,CSM_AV,IPC,IPC_INT,VCU
 SG_ EGI2P_PwrtrnCrnkActvAuth : 45|1@0+ (1,0) [0|1] "" TCP,CSM,CSM_AV,IPC,IPC_INT,VCU
 SG_ DrSeltdSpdLmtrSetTypActvAuth : 47|2@0+ (1,0) [0|3] "" TCP,CSM,CSM_AV,IPC,IPC_INT,VCU
 SG_ BrkPdlDrvAppPrsDetcdAuth : 48|1@0+ (1,0) [0|1] "" TCP,CSM,CSM_AV,VCU
 SG_ BrkPdlDrvAppPrsDetcdAuth_Inv : 49|1@0+ (1,0) [0|1] "" TCP,CSM,CSM_AV,VCU
 SG_ Bat12VCfg : 58|3@0+ (1,0) [0|7] "" CSM,VCU
 SG_ ETRPP_ElcTransRngPriAuth : 61|3@0+ (1,0) [0|6] "" RadioLow,CSM,VCU
 SG_ BSIS2P_ABSFldAuth : 62|1@0+ (1,0) [0|1] "" TCP,CSM,CSM_AV,VCU
 SG_ BSIS2P_ABSAtvAuth : 63|1@0+ (1,0) [0|1] "" PDR,RadioLow,TCP,CSM,CSM_AV,VCU

BO_ 704 PDU_5015: 4 CGM
 SG_ BSIS2P_BrkPdlDrvApplPresAuth : 6|10@0+ (20,0) [0|20460] "kPa" PDR,TCP,CSM,CSM_AV,VCU
 SG_ BSIS2P_BrkPdlDrvApplPresAuth_Inv : 7|1@0+ (1,0) [0|1] "" PDR,TCP,CSM,CSM_AV,VCU

BO_ 932 PDU_5016: 8 CGM
 SG_ BVSCP_BdyCtlTopSpdLimReqValAuth : 7|8@0+ (1,0) [0|255] "kph" IPC,IPC_INT,VCU
 SG_ CTGI1P_CnvtTpSpLimRqValAuth : 10|8@0+ (2,0) [0|510] "kph" IPC,IPC_INT,VCU
 SG_ BdyCtlTopSpdLimSrcAuth : 13|3@0+ (1,0) [0|7] "" IPC,IPC_INT,VCU
 SG_ BdyCtlTopSpdLimIndOnAuth : 14|1@0+ (1,0) [0|1] "" IPC,IPC_INT,VCU
 SG_ BdyCtlAccelLimIndOnAuth : 15|1@0+ (1,0) [0|1] "" IPC,IPC_INT,VCU
 SG_ DeadFrntSwtchIllumLvl : 17|7@0+ (1,0) [0|127] "%" HVAC_FP_F,HVAC_FP_R,MFC,RadioLow,CSM,CSM_AV,VCU
 SG_ CnvtTopModSpdLimIndOnAuth : 18|1@0+ (1,0) [0|1] "" IPC,IPC_INT,VCU
 SG_ IntDimDspLvl : 26|7@0+ (1,0) [0|127] "%" HVAC_FP_F,HVAC_FP_R,MFC,RadioLow,CSM,CSM_AV,IPC,IPC_INT,VCU
 SG_ IntDimLvl : 35|7@0+ (1,0) [0|127] "%" HVAC_FP_F,HVAC_FP_R,MFC,RadioLow,CSM,CSM_AV,IPC,IPC_INT,VCU
 SG_ DrvShftCntrlTrgtGr : 43|4@0+ (1,0) [0|10] "" CSM,CSM_AV,IPC,IPC_INT,VCU
 SG_ DrvShftCntrlReqDndIO : 44|1@0+ (1,0) [0|1] "" CSM,CSM_AV,IPC,IPC_INT,VCU
 SG_ TEGP_TrnsShftLvrPstnAuth_Inv : 48|1@0+ (1,0) [0|1] "" RadioLow,TCP,VKM,CSM,CSM_AV,IPC,IPC_INT,VCU
 SG_ TEGP_TrnsEstGrAuth : 52|4@0+ (1,0) [0|15] "" AMP,ICS_Info,PDR,TCP,CSM,CSM_AV,IPC,IPC_INT,VCU
 SG_ TEGP_TrnsEstGrAuth_Inv : 53|1@0+ (1,0) [0|1] "" AMP,PDR,TCP,CSM,CSM_AV,IPC,IPC_INT,VCU
 SG_ TrnsTUTDMdSt : 55|2@0+ (1,0) [0|2] "" CSM,CSM_AV,IPC,IPC_INT,VCU
 SG_ TEGP_TransCmndGrAuth : 59|4@0+ (1,0) [0|15] "" AMP,TCP,CSM,CSM_AV,IPC,IPC_INT,VCU
 SG_ TEGP_TrnsShftLvrPstnAuth : 63|4@0+ (1,0) [0|14] "" RadioLow,TCP,VKM,CSM,CSM_AV,IPC,IPC_INT,VCU

BO_ 933 PDU_5017: 6 CGM
 SG_ TrnsRngInhbtSt : 1|3@0+ (1,0) [0|4] "" CSM,CSM_AV,VCU
 SG_ TEGP_TrnsEngdStAuth : 3|2@0+ (1,0) [0|3] "" AMP,TCP,CSM,CSM_AV,IPC,IPC_INT,VCU
 SG_ TEGP_TrnsEngdStAuth_Inv : 4|1@0+ (1,0) [0|1] "" AMP,TCP,CSM,CSM_AV,IPC,IPC_INT,VCU
 SG_ HiVltgBatOutOfEngyIndReq : 7|3@0+ (1,0) [0|4] "" FPI,RSI,CSM,CSM_AV,IPC,IPC_INT,VCU
 SG_ DrvrElecVehModeCmnd : 12|1@0+ (1,0) [0|1] "" AMP,PDR,CSM,CSM_AV,IPC,IPC_INT,VCU
 SG_ EASSI_StrtStpSt : 14|2@0+ (1,0) [0|3] "" AMP,PDR,RadioLow,IPC,IPC_INT,VCU

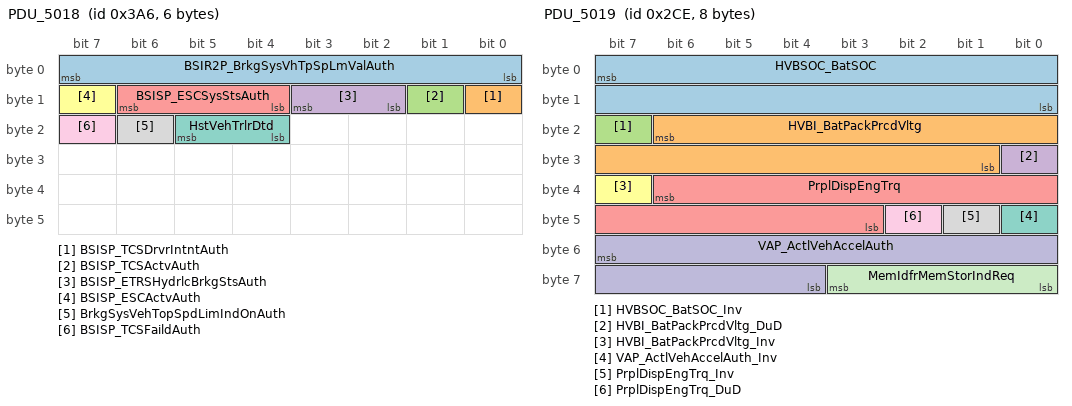
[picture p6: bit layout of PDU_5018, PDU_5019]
BO_ 934 PDU_5018: 6 CGM
 SG_ BSIR2P_BrkgSysVhTpSpLmValAuth : 7|8@0+ (2,0) [0|510] "kph" IPC,IPC_INT,VCU
 SG_ BSISP_TCSDrvrIntntAuth : 8|1@0+ (1,0) [0|1] "" TCP,CSM,CSM_AV,VCU
 SG_ BSISP_TCSActvAuth : 9|1@0+ (1,0) [0|1] "" PDR,RadioLow,TCP,CSM,CSM_AV,VCU
 SG_ BSISP_ETRSHydrlcBrkgStsAuth : 11|2@0+ (1,0) [0|2] "" CSM,CSM_AV,VCU
 SG_ BSISP_ESCSysStsAuth : 14|3@0+ (1,0) [0|4] "" CSM,CSM_AV,VCU
 SG_ BSISP_ESCActvAuth : 15|1@0+ (1,0) [0|1] "" PDR,RadioLow,TCP,CSM,CSM_AV,VCU
 SG_ HstVehTrlrDtd : 21|2@0+ (1,0) [0|3] "" TCP
 SG_ BrkgSysVehTopSpdLimIndOnAuth : 22|1@0+ (1,0) [0|1] "" IPC,IPC_INT,VCU
 SG_ BSISP_TCSFaildAuth : 23|1@0+ (1,0) [0|1] "" TCP,CSM,CSM_AV,VCU

BO_ 718 PDU_5019: 8 CGM
 SG_ HVBSOC_BatSOC : 7|16@0+ (0.0015259,0) [0|100] "%" VKM,CSM,CSM_AV,VCU
 SG_ HVBI_BatPackPrcdVltg : 22|14@0+ (0.0624,0) [0|1022.3] "V" CSM,CSM_AV,VCU
 SG_ HVBSOC_BatSOC_Inv : 23|1@0+ (1,0) [0|1] "" VKM,CSM,CSM_AV,VCU
 SG_ HVBI_BatPackPrcdVltg_DuD : 24|1@0+ (1,0) [0|1] "" CSM,CSM_AV,VCU
 SG_ PrplDispEngTrq : 38|12@0+ (0.5,-848) [-848|1199.5] "Nm" PDR,CSM,CSM_AV,VCU
 SG_ HVBI_BatPackPrcdVltg_Inv : 39|1@0+ (1,0) [0|1] "" CSM,CSM_AV,VCU
 SG_ VAP_ActlVehAccelAuth_Inv : 40|1@0+ (1,0) [0|1] "" TCP,IPC,IPC_INT,VCU
 SG_ PrplDispEngTrq_Inv : 41|1@0+ (1,0) [0|1] "" CSM,CSM_AV,VCU
 SG_ PrplDispEngTrq_DuD : 42|1@0+ (1,0) [0|1] "" CSM,CSM_AV,VCU
 SG_ VAP_ActlVehAccelAuth : 55|12@0- (0.01,0) [-20.48|20.47] "m/s^2" TCP,IPC,IPC_INT,VCU
 SG_ MemIdfrMemStorIndReq : 59|4@0+ (1,0) [0|8] "" IPC,IPC_INT,VCU

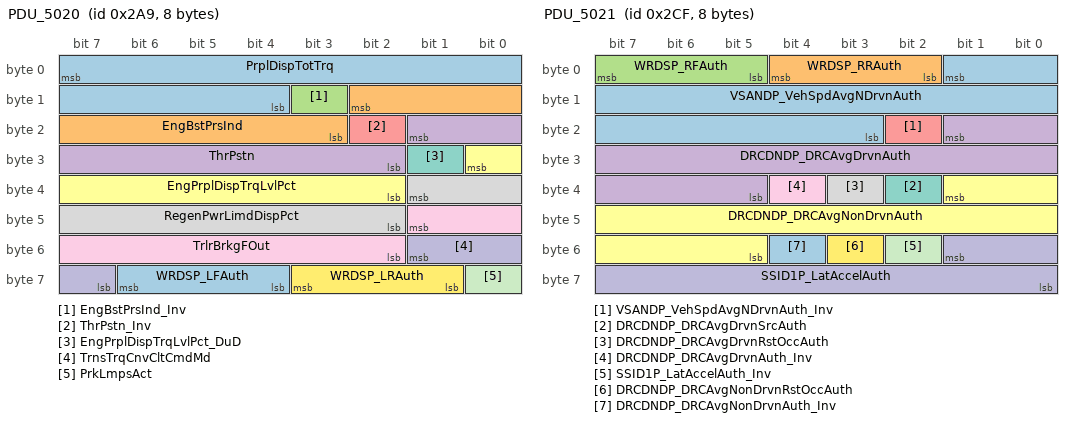
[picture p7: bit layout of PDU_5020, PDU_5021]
BO_ 681 PDU_5020: 8 CGM
 SG_ PrplDispTotTrq : 7|12@0+ (0.5,-848) [-848|1199.5] "Nm" PDR,CSM,CSM_AV,VCU
 SG_ EngBstPrsInd : 10|8@0+ (0.392157,0) [0|100] "%" PDR,CSM,CSM_AV,IPC,IPC_INT,VCU
 SG_ EngBstPrsInd_Inv : 11|1@0+ (1,0) [0|1] "" PDR,CSM,CSM_AV,IPC,IPC_INT,VCU
 SG_ ThrPstn : 17|8@0+ (0.392157,0) [0|100] "%" TCP,CSM,CSM_AV,VCU
 SG_ ThrPstn_Inv : 18|1@0+ (1,0) [0|1] "" CSM,CSM_AV,VCU
 SG_ EngPrplDispTrqLvlPct : 24|7@0+ (1,0) [0|127] "%" CSM,CSM_AV,VCU
 SG_ EngPrplDispTrqLvlPct_DuD : 25|1@0+ (1,0) [0|1] "" CSM,CSM_AV,VCU
 SG_ RegenPwrLimdDispPct : 33|8@0- (1,0) [-128|127] "%" PDR,IPC,IPC_INT,VCU
 SG_ TrlrBrkgFOut : 41|8@0+ (0.392157,0) [0|100] "%" CSM,CSM_AV,IPC,IPC_INT,VCU
 SG_ TrnsTrqCnvCltCmdMd : 49|3@0+ (1,0) [0|4] "" AMP
 SG_ PrkLmpsAct : 56|1@0+ (1,0) [0|1] "" TCP
 SG_ WRDSP_LRAuth : 59|3@0+ (1,0) [0|4] "" PDR,TCP,CSM,CSM_AV,VCU
 SG_ WRDSP_LFAuth : 62|3@0+ (1,0) [0|4] "" PDR,TCP,CSM,CSM_AV,VCU

BO_ 719 PDU_5021: 8 CGM
 SG_ VSANDP_VehSpdAvgNDrvnAuth : 1|15@0+ (0.015625,0) [0|511.984] "Km/h" AMP,FPI,PDR,RSI,RadioLow,TCP,CSM,CSM_AV,IPC,IPC_INT,VCU
 SG_ WRDSP_RRAuth : 4|3@0+ (1,0) [0|4] "" PDR,TCP,CSM,CSM_AV,VCU
 SG_ WRDSP_RFAuth : 7|3@0+ (1,0) [0|4] "" PDR,TCP,CSM,CSM_AV,VCU
 SG_ DRCDNDP_DRCAvgDrvnAuth : 17|13@0+ (0.125,0) [0|1023.88] "m" TCP,CSM,CSM_AV,IPC,IPC_INT,VCU
 SG_ VSANDP_VehSpdAvgNDrvnAuth_Inv : 18|1@0+ (1,0) [0|1] "" AMP,FPI,PDR,RSI,RadioLow,TCP,CSM,CSM_AV,IPC,IPC_INT,VCU
 SG_ DRCDNDP_DRCAvgNonDrvnAuth : 33|13@0+ (0.125,0) [0|1023.88] "m" TCP,CSM,CSM_AV,IPC,IPC_INT,VCU
 SG_ DRCDNDP_DRCAvgDrvnSrcAuth : 34|1@0+ (1,0) [0|1] "" TCP,CSM,CSM_AV,VCU
 SG_ DRCDNDP_DRCAvgDrvnRstOccAuth : 35|1@0+ (1,0) [0|1] "" TCP,CSM,CSM_AV,IPC,IPC_INT,VCU
 SG_ DRCDNDP_DRCAvgDrvnAuth_Inv : 36|1@0+ (1,0) [0|1] "" TCP,CSM,CSM_AV,IPC,IPC_INT,VCU
 SG_ SSID1P_LatAccelAuth : 49|10@0- (0.0625,0) [-32|31.9375] "m/s2" VKM
 SG_ SSID1P_LatAccelAuth_Inv : 50|1@0+ (1,0) [0|1] "" VKM
 SG_ DRCDNDP_DRCAvgNonDrvnRstOccAuth : 51|1@0+ (1,0) [0|1] "" TCP,CSM,CSM_AV,IPC,IPC_INT,VCU
 SG_ DRCDNDP_DRCAvgNonDrvnAuth_Inv : 52|1@0+ (1,0) [0|1] "" TCP,CSM,CSM_AV,IPC,IPC_INT,VCU

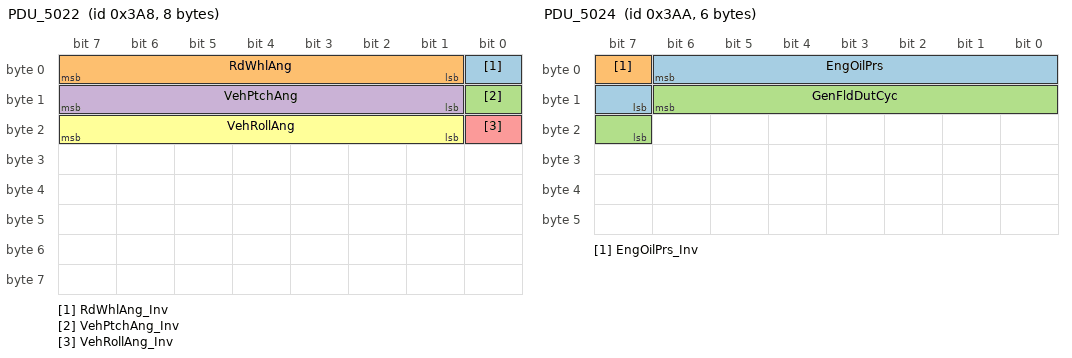
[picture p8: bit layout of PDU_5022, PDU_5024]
BO_ 936 PDU_5022: 8 CGM
 SG_ RdWhlAng_Inv : 0|1@0+ (1,0) [0|1] "" CSM,CSM_AV,IPC,IPC_INT,VCU
 SG_ RdWhlAng : 7|7@0- (0.703125,0) [-45|44.2969] "deg" CSM,CSM_AV,IPC,IPC_INT,VCU
 SG_ VehPtchAng_Inv : 8|1@0+ (1,0) [0|1] "" CSM,CSM_AV,IPC,IPC_INT,VCU
 SG_ VehPtchAng : 15|7@0- (0.703125,0) [-45|44.2969] "deg" CSM,CSM_AV,IPC,IPC_INT,VCU
 SG_ VehRollAng_Inv : 16|1@0+ (1,0) [0|1] "" CSM,CSM_AV,IPC,IPC_INT,VCU
 SG_ VehRollAng : 23|7@0- (0.703125,0) [-45|44.2969] "deg" CSM,CSM_AV,IPC,IPC_INT,VCU

BO_ 937 PDU_5023: 6 CGM
 SG_ AFLHiBmsOtgIndOn : 6|1@0+ (1,0) [0|1] "" TCP
 SG_ AFLCkLoBmsIndOn : 7|1@0+ (1,0) [0|1] "" TCP

BO_ 938 PDU_5024: 6 CGM
 SG_ EngOilPrs : 6|8@0+ (4,0) [0|1020] "kPa" PDR,TCP,CSM,CSM_AV,IPC,IPC_INT,VCU
 SG_ EngOilPrs_Inv : 7|1@0+ (1,0) [0|1] "" PDR,TCP,CSM,CSM_AV,IPC,IPC_INT,VCU
 SG_ GenFldDutCyc : 14|8@0+ (0.392157,0) [0|100] "%" CSM,CSM_AV,VCU

BO_ 1407 PDU_5025: 8 CGM
 SG_ APACR_SptFndChmEvntStat : 1|2@0+ (1,0) [0|2] "" CSM,CSM_AV,IPC,IPC_INT,VCU
 SG_ APACR_FaildChmEvntStat : 3|2@0+ (1,0) [0|2] "" CSM,CSM_AV,IPC,IPC_INT,VCU
 SG_ APACR_CncldChmEvntStat : 5|2@0+ (1,0) [0|2] "" CSM,CSM_AV,IPC,IPC_INT,VCU
 SG_ APACR_CmpltChmEvntStat : 7|2@0+ (1,0) [0|2] "" CSM,CSM_AV,IPC,IPC_INT,VCU
 SG_ TrnsOilRmnLf : 13|8@0+ (0.392157,0) [0|100] "%" TCP,VKM,CSM,CSM_AV,IPC,IPC_INT,VCU
 SG_ APACR_StopChmEvntStat : 15|2@0+ (1,0) [0|2] "" CSM,CSM_AV,IPC,IPC_INT,VCU
 SG_ FCAIAHSR_HptcStReqPuls : 21|6@0+ (1,0) [0|63] "pulses" TCP,CSM,CSM_AV,VCU
 SG_ ELWWIP_WprFrtFtrReqAuth : 26|4@0+ (1,0) [0|12] "" CSM,CSM_AV,VCU
 SG_ LnCntrWrnIndRqst : 31|5@0+ (1,0) [0|16] "" TCP,CSM,CSM_AV,VCU
 SG_ ELWWIP_BrkLmpLtCmdAuth : 34|3@0+ (1,0) [0|4] "" CSM,CSM_AV,VCU
 SG_ TrlrConnCntr : 38|4@0+ (1,0) [0|15] "Count" CSM,CSM_AV,VCU
 SG_ LKALnMrkgIndLt : 41|3@0+ (1,0) [0|4] "" CSM,CSM_AV,IPC,IPC_INT,VCU
 SG_ FrntPsSeatbeltStat : 43|2@0+ (1,0) [0|2] "" FPI,RSI,RadioLow,TCP,CSM,CSM_AV,VCU
 SG_ FrntPsSeatbeltStat_Inv : 44|1@0+ (1,0) [0|1] "" FPI,RSI,RadioLow,TCP,CSM,CSM_AV,VCU
 SG_ ELWWIP_BrkLmpRtCmdAuth : 47|3@0+ (1,0) [0|4] "" CSM,CSM_AV,VCU
 SG_ ORIP_DrvrStBltSts1Auth_Inv : 48|1@0+ (1,0) [0|1] "" RadioLow,TCP,CSM,CSM_AV,VCU
 SG_ LnDtWrnCntrlVsAlrtCmdGnc : 51|3@0+ (1,0) [0|4] "" RadioLow,CSM,CSM_AV,IPC,IPC_INT,VCU
 SG_ LKALnMrkgIndRt : 54|3@0+ (1,0) [0|4] "" CSM,CSM_AV,IPC,IPC_INT,VCU
 SG_ AdpLghtRspTypCstAvlFlg4 : 56|1@0+ (1,0) [0|1] "" RadioLow,CSM,CSM_AV,VCU
 SG_ MltpPsStBtRmndrChmEvntStat : 58|2@0+ (1,0) [0|2] "" IPC,IPC_INT,VCU
 SG_ RrPCMRspTypCstCrStVal : 61|3@0+ (1,0) [0|6] "" RadioLow,CSM,CSM_AV,VCU
 SG_ ORIP_DrvrStBltSts1Auth : 63|2@0+ (1,0) [0|2] "" RadioLow,TCP,CSM,CSM_AV,VCU

BO_ 1408 PDU_5026: 8 CGM
 SG_ ElecPrkBrkCtnChiEveStat : 1|2@0+ (1,0) [0|2] "" CSM,CSM_AV,IPC,IPC_INT,VCU
 SG_ ELWWIP_TrlrRvrsLmpsCmdAuth : 3|2@0+ (1,0) [0|2] "" CSM,CSM_AV,VCU
 SG_ ELWWIP_RvrsLmpCmdAuth : 5|2@0+ (1,0) [0|2] "" CSM,CSM_AV,VCU
 SG_ ELWWIP_CHMSLCmdAuth : 7|2@0+ (1,0) [0|3] "" CSM,CSM_AV,VCU
 SG_ LDWCtrlHndOff1ChmEvntStat : 9|2@0+ (1,0) [0|2] "" TCP,CSM,CSM_AV,IPC,IPC_INT,VCU
 SG_ FrwdCllsnAlrtImAlrtDrIntAlrtChmE : 11|2@0+ (1,0) [0|2] "" TCP,CSM,CSM_AV,IPC,IPC_INT,VCU
 SG_ FrntPCMChmEvntStat : 13|2@0+ (1,0) [0|2] "" CSM,CSM_AV,IPC,IPC_INT,VCU
 SG_ ElecPrkBrkFixDurChiEveStat : 15|2@0+ (1,0) [0|2] "" CSM,CSM_AV,IPC,IPC_INT,VCU
 SG_ LDWCtrlRtHndSdChmEvntStat : 17|2@0+ (1,0) [0|2] "" TCP,CSM,CSM_AV,IPC,IPC_INT,VCU
 SG_ LDWCtrlLtHndSdChmEvntStat : 19|2@0+ (1,0) [0|2] "" TCP,CSM,CSM_AV,IPC,IPC_INT,VCU
 SG_ LDWCtrlHndOff3ChmEvntStat : 21|2@0+ (1,0) [0|2] "" CSM,CSM_AV,IPC,IPC_INT,VCU
 SG_ LDWCtrlHndOff2ChmEvntStat : 23|2@0+ (1,0) [0|2] "" TCP,CSM,CSM_AV,IPC,IPC_INT,VCU
 SG_ MemStrDblBeepChmEvStRR : 25|2@0+ (1,0) [0|2] "" IPC,IPC_INT,VCU
 SG_ MemStrDblBeepChmEvStLR : 27|2@0+ (1,0) [0|2] "" IPC,IPC_INT,VCU
 SG_ MemStrDblBeepChmEvStDrv : 29|2@0+ (1,0) [0|2] "" IPC,IPC_INT,VCU
 SG_ MemStrDblBeepChmEvStCoDrv : 31|2@0+ (1,0) [0|2] "" IPC,IPC_INT,VCU
 SG_ MemStrSnglBeepChmEvStRR : 33|2@0+ (1,0) [0|2] "" IPC,IPC_INT,VCU
 SG_ MemStrSnglBeepChmEvStLR : 35|2@0+ (1,0) [0|2] "" IPC,IPC_INT,VCU
 SG_ MemStrSnglBeepChmEvStDrv : 37|2@0+ (1,0) [0|2] "" IPC,IPC_INT,VCU
 SG_ MemStrSnglBeepChmEvStCoDrv : 39|2@0+ (1,0) [0|2] "" IPC,IPC_INT,VCU
 SG_ MemStrTrplBeepChmEvStRR : 41|2@0+ (1,0) [0|2] "" IPC,IPC_INT,VCU
 SG_ MemStrTrplBeepChmEvStLR : 43|2@0+ (1,0) [0|2] "" IPC,IPC_INT,VCU
 SG_ MemStrTrplBeepChmEvStDrv : 45|2@0+ (1,0) [0|2] "" IPC,IPC_INT,VCU
 SG_ MemStrTrplBeepChmEvStCoDrv : 47|2@0+ (1,0) [0|2] "" IPC,IPC_INT,VCU
 SG_ PrkAsstFllFrZn2ChEvntSt : 49|2@0+ (1,0) [0|2] "" CSM,CSM_AV,IPC,IPC_INT,VCU
 SG_ PrkAsstFllFrZn1ChEvntSt : 51|2@0+ (1,0) [0|2] "" CSM,CSM_AV,IPC,IPC_INT,VCU
 SG_ PrkAsstFlChEvntSt : 53|2@0+ (1,0) [0|2] "" CSM,CSM_AV,IPC,IPC_INT,VCU
 SG_ PAMutSts : 55|2@0+ (1,0) [0|2] "" IPC,IPC_INT,VCU
 SG_ PrkAsstFllFrZn6ChEvntSt : 57|2@0+ (1,0) [0|2] "" CSM,CSM_AV,IPC,IPC_INT,VCU
 SG_ PrkAsstFllFrZn5ChEvntSt : 59|2@0+ (1,0) [0|2] "" CSM,CSM_AV,IPC,IPC_INT,VCU
 SG_ PrkAsstFllFrZn4ChEvntSt : 61|2@0+ (1,0) [0|2] "" CSM,CSM_AV,IPC,IPC_INT,VCU
 SG_ PrkAsstFllFrZn3ChEvntSt : 63|2@0+ (1,0) [0|2] "" CSM,CSM_AV,IPC,IPC_INT,VCU

BO_ 1409 PDU_5027: 8 CGM
 SG_ PrkAsstFllRrZn4ChEvntSt : 1|2@0+ (1,0) [0|2] "" CSM,CSM_AV,IPC,IPC_INT,VCU
 SG_ PrkAsstFllRrZn3ChEvntSt : 3|2@0+ (1,0) [0|2] "" CSM,CSM_AV,IPC,IPC_INT,VCU
 SG_ PrkAsstFllRrZn2ChEvntSt : 5|2@0+ (1,0) [0|2] "" CSM,CSM_AV,IPC,IPC_INT,VCU
 SG_ PrkAsstFllRrZn1ChEvntSt : 7|2@0+ (1,0) [0|2] "" CSM,CSM_AV,IPC,IPC_INT,VCU
 SG_ PrkAsstFrLftSdZn1ChEvntSt : 9|2@0+ (1,0) [0|2] "" CSM,CSM_AV,IPC,IPC_INT,VCU
 SG_ PrkAsstFrFrstRprtChEvntSt : 11|2@0+ (1,0) [0|2] "" CSM,CSM_AV,IPC,IPC_INT,VCU
 SG_ PrkAsstFllRrZn6ChEvntSt : 13|2@0+ (1,0) [0|2] "" CSM,CSM_AV,IPC,IPC_INT,VCU
 SG_ PrkAsstFllRrZn5ChEvntSt : 15|2@0+ (1,0) [0|2] "" CSM,CSM_AV,IPC,IPC_INT,VCU
 SG_ PrkAsstFrLftSdZn5ChEvntSt : 17|2@0+ (1,0) [0|2] "" CSM,CSM_AV,IPC,IPC_INT,VCU
 SG_ PrkAsstFrLftSdZn4ChEvntSt : 19|2@0+ (1,0) [0|2] "" CSM,CSM_AV,IPC,IPC_INT,VCU
 SG_ PrkAsstFrLftSdZn3ChEvntSt : 21|2@0+ (1,0) [0|2] "" CSM,CSM_AV,IPC,IPC_INT,VCU
 SG_ PrkAsstFrLftSdZn2ChEvntSt : 23|2@0+ (1,0) [0|2] "" CSM,CSM_AV,IPC,IPC_INT,VCU
 SG_ PrkAsstFrRghtSdZn3ChEvntSt : 25|2@0+ (1,0) [0|2] "" CSM,CSM_AV,IPC,IPC_INT,VCU
 SG_ PrkAsstFrRghtSdZn2ChEvntSt : 27|2@0+ (1,0) [0|2] "" CSM,CSM_AV,IPC,IPC_INT,VCU
 SG_ PrkAsstFrRghtSdZn1ChEvntSt : 29|2@0+ (1,0) [0|2] "" CSM,CSM_AV,IPC,IPC_INT,VCU
 SG_ PrkAsstFrLftSdZn6ChEvntSt : 31|2@0+ (1,0) [0|2] "" CSM,CSM_AV,IPC,IPC_INT,VCU
 SG_ PrkAsstFrRgrChEvntSt : 33|2@0+ (1,0) [0|2] "" IPC,IPC_INT,VCU
 SG_ PrkAsstFrRghtSdZn6ChEvntSt : 35|2@0+ (1,0) [0|2] "" IPC,IPC_INT,VCU
 SG_ PrkAsstFrRghtSdZn5ChEvntSt : 37|2@0+ (1,0) [0|2] "" CSM,CSM_AV,IPC,IPC_INT,VCU
 SG_ PrkAsstFrRghtSdZn4ChEvntSt : 39|2@0+ (1,0) [0|2] "" CSM,CSM_AV,IPC,IPC_INT,VCU
 SG_ PrkAsstRrLftSdZn3ChEvntSt : 41|2@0+ (1,0) [0|2] "" IPC,IPC_INT,VCU
 SG_ PrkAsstRrLftSdZn2ChEvntSt : 43|2@0+ (1,0) [0|2] "" IPC,IPC_INT,VCU
 SG_ PrkAsstRrLftSdZn1ChEvntSt : 45|2@0+ (1,0) [0|2] "" IPC,IPC_INT,VCU
 SG_ PrkAsstRrFrstRprtChEvntSt : 47|2@0+ (1,0) [0|2] "" IPC,IPC_INT,VCU
 SG_ PrkAsstRrRghtSdZn1ChEvntSt : 49|2@0+ (1,0) [0|2] "" IPC,IPC_INT,VCU
 SG_ PrkAsstRrLftSdZn6ChEvntSt : 51|2@0+ (1,0) [0|2] "" IPC,IPC_INT,VCU
 SG_ PrkAsstRrLftSdZn5ChEvntSt : 53|2@0+ (1,0) [0|2] "" IPC,IPC_INT,VCU
 SG_ PrkAsstRrLftSdZn4ChEvntSt : 55|2@0+ (1,0) [0|2] "" IPC,IPC_INT,VCU
 SG_ PrkAsstRrRghtSdZn5ChEvntSt : 57|2@0+ (1,0) [0|2] "" IPC,IPC_INT,VCU
 SG_ PrkAsstRrRghtSdZn4ChEvntSt : 59|2@0+ (1,0) [0|2] "" IPC,IPC_INT,VCU
 SG_ PrkAsstRrRghtSdZn3ChEvntSt : 61|2@0+ (1,0) [0|2] "" IPC,IPC_INT,VCU
 SG_ PrkAsstRrRghtSdZn2ChEvntSt : 63|2@0+ (1,0) [0|2] "" IPC,IPC_INT,VCU

BO_ 1410 PDU_5028: 8 CGM
 SG_ PwrSdClsrLRObstclChmEvntStat : 1|2@0+ (1,0) [0|2] "" IPC,IPC_INT,VCU
 SG_ PwrSdClsrLFObstclChmEvntStat : 3|2@0+ (1,0) [0|2] "" IPC,IPC_INT,VCU
 SG_ PrkAsstRrRgrChEvntSt : 5|2@0+ (1,0) [0|2] "" IPC,IPC_INT,VCU
 SG_ PrkAsstRrRghtSdZn6ChEvntSt : 7|2@0+ (1,0) [0|2] "" IPC,IPC_INT,VCU
 SG_ PwrSdSldClsrLFRmtActChmEvntStat : 9|2@0+ (1,0) [0|2] "" IPC,IPC_INT,VCU
 SG_ PwrSdSldClsrLFLclActChmEvntStat : 11|2@0+ (1,0) [0|2] "" IPC,IPC_INT,VCU
 SG_ PwrSdClsrRRObstclChmEvntStat : 13|2@0+ (1,0) [0|2] "" IPC,IPC_INT,VCU
 SG_ PwrSdClsrRFObstclChmEvntStat : 15|2@0+ (1,0) [0|2] "" IPC,IPC_INT,VCU
 SG_ PwrSdSldClsrRFRmtActChmEvntStat : 17|2@0+ (1,0) [0|2] "" IPC,IPC_INT,VCU
 SG_ PwrSdSldClsrRFLclActChmEvntStat : 19|2@0+ (1,0) [0|2] "" IPC,IPC_INT,VCU
 SG_ PwrSdSldClsrLRRmtActChmEvntStat : 21|2@0+ (1,0) [0|2] "" IPC,IPC_INT,VCU
 SG_ PwrSdSldClsrLRLclActChmEvntStat : 23|2@0+ (1,0) [0|2] "" IPC,IPC_INT,VCU
 SG_ PwrSdSwgClsrLFRmtActChmEvntStat : 25|2@0+ (1,0) [0|2] "" IPC,IPC_INT,VCU
 SG_ PwrSdSwgClsrLFLclActChmEvntStat : 27|2@0+ (1,0) [0|2] "" IPC,IPC_INT,VCU
 SG_ PwrSdSldClsrRRRmtActChmEvntStat : 29|2@0+ (1,0) [0|2] "" IPC,IPC_INT,VCU
 SG_ PwrSdSldClsrRRLclActChmEvntStat : 31|2@0+ (1,0) [0|2] "" IPC,IPC_INT,VCU
 SG_ PwrSdSwgClsrRFRmtActChmEvntStat : 33|2@0+ (1,0) [0|2] "" IPC,IPC_INT,VCU
 SG_ PwrSdSwgClsrRFLclActChmEvntStat : 35|2@0+ (1,0) [0|2] "" IPC,IPC_INT,VCU
 SG_ PwrSdSwgClsrLRRmtActChmEvntStat : 37|2@0+ (1,0) [0|2] "" IPC,IPC_INT,VCU
 SG_ PwrSdSwgClsrLRLclActChmEvntStat : 39|2@0+ (1,0) [0|2] "" IPC,IPC_INT,VCU
 SG_ RIMIntCllnChmEvStat : 41|2@0+ (1,0) [0|2] "" CSM,CSM_AV,IPC,IPC_INT,VCU
 SG_ RIMBrkPlsChEvStat : 43|2@0+ (1,0) [0|2] "" IPC,IPC_INT,VCU
 SG_ PwrSdSwgClsrRRRmtActChmEvntStat : 45|2@0+ (1,0) [0|2] "" IPC,IPC_INT,VCU
 SG_ PwrSdSwgClsrRRLclActChmEvntStat : 47|2@0+ (1,0) [0|2] "" IPC,IPC_INT,VCU
 SG_ WlkAwyLkInhbtChmEvSt : 49|2@0+ (1,0) [0|2] "" IPC,IPC_INT,VCU
 SG_ RrPCMChmEvntSt : 53|2@0+ (1,0) [0|2] "" CSM,CSM_AV,IPC,IPC_INT,VCU
 SG_ RlOvrDsblStsChgChmEvntStat : 55|2@0+ (1,0) [0|2] "" IPC,IPC_INT,VCU
 SG_ AutMemRclCstAvlFlg5 : 56|1@0+ (1,0) [0|1] "" RadioLow,CSM,CSM_AV,VCU
 SG_ AutMemRclCstAvlFlg4 : 57|1@0+ (1,0) [0|1] "" RadioLow,CSM,CSM_AV,VCU
 SG_ AutMemRclCstAvlFlg3 : 58|1@0+ (1,0) [0|1] "" RadioLow,CSM,CSM_AV,VCU
 SG_ AutMemRclCstAvlFlg2 : 59|1@0+ (1,0) [0|1] "" RadioLow,CSM,CSM_AV,VCU
 SG_ AutMemRclCstAvlFlg1 : 60|1@0+ (1,0) [0|1] "" RadioLow,CSM,CSM_AV,VCU
 SG_ AdpLghtRspTypCstAvlFlg7 : 61|1@0+ (1,0) [0|1] "" RadioLow,CSM,CSM_AV,VCU
 SG_ AdpLghtRspTypCstAvlFlg6 : 62|1@0+ (1,0) [0|1] "" RadioLow,CSM,CSM_AV,VCU
 SG_ AdpLghtRspTypCstAvlFlg5 : 63|1@0+ (1,0) [0|1] "" RadioLow,CSM,CSM_AV,VCU

BO_ 1411 PDU_5029: 6 CGM
 SG_ EsyExtCstAvlFlg5 : 0|1@0+ (1,0) [0|1] "" RadioLow,CSM,CSM_AV,VCU
 SG_ EsyExtCstAvlFlg4 : 1|1@0+ (1,0) [0|1] "" RadioLow,CSM,CSM_AV,VCU
 SG_ EsyExtCstAvlFlg3 : 2|1@0+ (1,0) [0|1] "" RadioLow,CSM,CSM_AV,VCU
 SG_ EsyExtCstAvlFlg2 : 3|1@0+ (1,0) [0|1] "" RadioLow,CSM,CSM_AV,VCU
 SG_ EsyExtCstAvlFlg1 : 4|1@0+ (1,0) [0|1] "" RadioLow,CSM,CSM_AV,VCU
 SG_ EngIdlAtv : 5|1@0+ (1,0) [0|1] "" CSM,CSM_AV,IPC,IPC_INT,VCU
 SG_ AutMemRclCstAvlFlg7 : 6|1@0+ (1,0) [0|1] "" RadioLow,CSM,CSM_AV,VCU
 SG_ AutMemRclCstAvlFlg6 : 7|1@0+ (1,0) [0|1] "" RadioLow,CSM,CSM_AV,VCU
 SG_ RrPCMRspTypCstAvlFlg2 : 8|1@0+ (1,0) [0|1] "" RadioLow,CSM,CSM_AV,VCU
 SG_ RrPCMRspTypCstAvlFlg1 : 9|1@0+ (1,0) [0|1] "" RadioLow,CSM,CSM_AV,VCU
 SG_ LowBmAct : 10|1@0+ (1,0) [0|1] "" TCP,VKM
 SG_ LDWCtrlAudAttnReqd : 11|1@0+ (1,0) [0|1] "" RadioLow,CSM,CSM_AV,VCU
 SG_ HighBmAct : 12|1@0+ (1,0) [0|1] "" TCP,VKM
 SG_ FlToPsSwAtv : 13|1@0+ (1,0) [0|1] "" CSM,CSM_AV,VCU
 SG_ EsyExtCstAvlFlg7 : 14|1@0+ (1,0) [0|1] "" RadioLow,CSM,CSM_AV,VCU
 SG_ EsyExtCstAvlFlg6 : 15|1@0+ (1,0) [0|1] "" RadioLow,CSM,CSM_AV,VCU
 SG_ TrlrConnStat : 16|1@0+ (1,0) [0|1] "" RadioLow,CSM,CSM_AV,VCU
 SG_ StrgLckd : 17|1@0+ (1,0) [0|1] "" ICS_Info
 SG_ RrPCMRspTypCstStAvl : 18|1@0+ (1,0) [0|1] "" RadioLow,CSM,CSM_AV,VCU
 SG_ RrPCMRspTypCstAvlFlg7 : 19|1@0+ (1,0) [0|1] "" RadioLow,CSM,CSM_AV,VCU
 SG_ RrPCMRspTypCstAvlFlg6 : 20|1@0+ (1,0) [0|1] "" RadioLow,CSM,CSM_AV,VCU
 SG_ RrPCMRspTypCstAvlFlg5 : 21|1@0+ (1,0) [0|1] "" RadioLow,CSM,CSM_AV,VCU
 SG_ RrPCMRspTypCstAvlFlg4 : 22|1@0+ (1,0) [0|1] "" RadioLow,CSM,CSM_AV,VCU
 SG_ RrPCMRspTypCstAvlFlg3 : 23|1@0+ (1,0) [0|1] "" RadioLow,CSM,CSM_AV,VCU
 SG_ IndBlwSetLvlFrtRt : 25|4@0+ (1,0) [0|15] "" VCU
 SG_ PwrRrClsrMtnSts : 29|4@0+ (1,0) [0|9] "" VKM,VCU
 SG_ TrnLmpRtIO : 30|1@0+ (1,0) [0|1] "" TCP,VKM,CSM,CSM_AV,IPC,IPC_INT,VCU
 SG_ TrnLmpLftIO : 31|1@0+ (1,0) [0|1] "" TCP,VKM,CSM,CSM_AV,IPC,IPC_INT,VCU
 SG_ IndHtdArmrstLvlFrtLt : 33|3@0+ (1,0) [0|4] "" VCU
 SG_ IndBlwSetLvlRrRt : 37|4@0+ (1,0) [0|15] "" VCU
 SG_ IndHtdArmrstLvlRrLt : 43|3@0+ (1,0) [0|4] "" VCU
 SG_ IndHtdArmrstLvlFrtRt : 46|3@0+ (1,0) [0|4] "" VCU

BO_ 1480 PDU_5030: 6 CGM
 SG_ SLVFSP_SpdLimVsnFsdSpdAuth : 7|8@0+ (1,0) [0|255] "" IPC,IPC_INT,VCU
 SG_ SLVFSP_SpdLimVsnFsdSpdUntAuth : 15|1@0+ (1,0) [0|1] "" IPC,IPC_INT,VCU

BO_ 1481 PDU_5031: 8 CGM
 SG_ LFSCDS_CshLgAdjFdRr : 0|2@0+ (1,0) [0|3] "" RadioLow,CSM,CSM_AV,VCU
 SG_ LFSCDS_CshBlstrInOut : 2|2@0+ (1,0) [0|3] "" RadioLow,CSM,CSM_AV,VCU
 SG_ LFSCDS_BkCshBlstInOt : 5|3@0+ (1,0) [0|5] "" RadioLow,CSM,CSM_AV,VCU
 SG_ LFSCDS_BkBlstrInOut : 7|2@0+ (1,0) [0|3] "" RadioLow,CSM,CSM_AV,VCU
 SG_ LFSCDS_HdrstTltFwdRr : 8|2@0+ (1,0) [0|3] "" RadioLow,CSM,CSM_AV,VCU
 SG_ LFSCDS_HdrstFwdRrwd : 10|2@0+ (1,0) [0|3] "" RadioLow,CSM,CSM_AV,VCU
 SG_ LFSCDS_HdrstFdRrUDn : 13|3@0+ (1,0) [0|5] "" RadioLow,CSM,CSM_AV,VCU
 SG_ LFSCDS_DispReq : 14|1@0+ (1,0) [0|1] "" RadioLow,CSM,CSM_AV,VCU
 SG_ LFSCDS_LmbrUDnFdRr : 16|3@0+ (1,0) [0|5] "" RadioLow,CSM,CSM_AV,VCU
 SG_ LFSCDS_LmbrFwdRr : 18|2@0+ (1,0) [0|3] "" RadioLow,CSM,CSM_AV,VCU
 SG_ LFSCDS_HdrstWngInOt : 20|2@0+ (1,0) [0|3] "" RadioLow,CSM,CSM_AV,VCU
 SG_ LFSCDS_HdrstUpDn : 22|2@0+ (1,0) [0|3] "" RadioLow,CSM,CSM_AV,VCU
 SG_ LFSCDS_MassgIntsty : 25|3@0+ (1,0) [0|7] "" RadioLow,CSM,CSM_AV,VCU
 SG_ LFSCDS_Massg : 27|2@0+ (1,0) [0|2] "" RadioLow,CSM,CSM_AV,VCU
 SG_ LFSCDS_LmbrUpDwn : 29|2@0+ (1,0) [0|3] "" RadioLow,CSM,CSM_AV,VCU
 SG_ APAWI_AutoStrgIconReq : 32|2@0+ (1,0) [0|2] "" RadioLow,CSM,CSM_AV,IPC,IPC_INT,VCU
 SG_ LFSCDS_UprShldrFdRr : 34|2@0+ (1,0) [0|3] "" RadioLow,CSM,CSM_AV,VCU
 SG_ LFSCDS_MassgTyp : 38|4@0+ (1,0) [0|15] "" RadioLow,CSM,CSM_AV,VCU
 SG_ APAWI_MnvrPrgs : 44|14@0+ (0.01,0) [0|163.83] "" RadioLow,VKM,CSM,CSM_AV,IPC,IPC_INT,VCU
 SG_ APAWI_FcsReq : 46|2@0+ (1,0) [0|2] "" RadioLow,CSM,CSM_AV,IPC,IPC_INT,VCU
 SG_ AdpLghtRspTypCstStAvl : 56|1@0+ (1,0) [0|1] "" RadioLow,CSM,CSM_AV,VCU
 SG_ APAWI_WrnIndReq : 62|6@0+ (1,0) [0|59] "" RadioLow,TCP,VKM,CSM,CSM_AV,IPC,IPC_INT,VCU

BO_ 1465 PDU_5032: 8 CGM
 SG_ LRSCDS_CshLgAdjFdRr : 0|2@0+ (1,0) [0|3] "" RadioLow,CSM,CSM_AV,VCU
 SG_ LRSCDS_CshBlstrInOut : 2|2@0+ (1,0) [0|3] "" RadioLow,CSM,CSM_AV,VCU
 SG_ LRSCDS_BkCshBlstInOt : 5|3@0+ (1,0) [0|5] "" RadioLow,CSM,CSM_AV,VCU
 SG_ LRSCDS_BkBlstrInOut : 7|2@0+ (1,0) [0|3] "" RadioLow,CSM,CSM_AV,VCU
 SG_ LRSCDS_HdrstTltFwdRr : 8|2@0+ (1,0) [0|3] "" RadioLow,CSM,CSM_AV,VCU
 SG_ LRSCDS_HdrstFwdRrwd : 10|2@0+ (1,0) [0|3] "" RadioLow,CSM,CSM_AV,VCU
 SG_ LRSCDS_HdrstFdRrUDn : 13|3@0+ (1,0) [0|5] "" RadioLow,CSM,CSM_AV,VCU
 SG_ LRSCDS_DispReq : 14|1@0+ (1,0) [0|1] "" RadioLow,CSM,CSM_AV,VCU
 SG_ LRSCDS_LmbrUDnFdRr : 16|3@0+ (1,0) [0|5] "" RadioLow,CSM,CSM_AV,VCU
 SG_ LRSCDS_LmbrFwdRr : 18|2@0+ (1,0) [0|3] "" RadioLow,CSM,CSM_AV,VCU
 SG_ LRSCDS_HdrstWngInOt : 20|2@0+ (1,0) [0|3] "" RadioLow,CSM,CSM_AV,VCU
 SG_ LRSCDS_HdrstUpDn : 22|2@0+ (1,0) [0|3] "" RadioLow,CSM,CSM_AV,VCU
 SG_ LRSCDS_MassgIntsty : 25|3@0+ (1,0) [0|7] "" RadioLow,CSM,CSM_AV,VCU
 SG_ LRSCDS_Massg : 27|2@0+ (1,0) [0|2] "" RadioLow,CSM,CSM_AV,VCU
 SG_ LRSCDS_LmbrUpDwn : 29|2@0+ (1,0) [0|3] "" RadioLow,CSM,CSM_AV,VCU
 SG_ SDGPARS_CntrLtSd : 32|4@0+ (1,0) [0|14] "" IPC,IPC_INT,VCU
 SG_ LRSCDS_UprShldrFdRr : 34|2@0+ (1,0) [0|3] "" RadioLow,CSM,CSM_AV,VCU
 SG_ LRSCDS_MassgTyp : 38|4@0+ (1,0) [0|15] "" RadioLow,CSM,CSM_AV,VCU
 SG_ SDGPARS_FrtLtSd : 40|4@0+ (1,0) [0|14] "" IPC,IPC_INT,VCU
 SG_ SDGPARS_CntrRtSd : 44|4@0+ (1,0) [0|14] "" IPC,IPC_INT,VCU
 SG_ SDGPARS_RrLtSd : 48|4@0+ (1,0) [0|14] "" IPC,IPC_INT,VCU
 SG_ SDGPARS_FrtRtSd : 52|4@0+ (1,0) [0|14] "" IPC,IPC_INT,VCU
 SG_ AirbgStIndOn : 56|1@0+ (1,0) [0|1] "" TCP,IPC,IPC_INT,VCU
 SG_ SDGPARS_RrRtSd : 60|4@0+ (1,0) [0|14] "" IPC,IPC_INT,VCU

BO_ 1483 PDU_5033: 8 CGM
 SG_ RFSCDS_CshLgAdjFdRr : 0|2@0+ (1,0) [0|3] "" RadioLow,CSM,CSM_AV,VCU
 SG_ RFSCDS_CshBlstrInOut : 2|2@0+ (1,0) [0|3] "" RadioLow,CSM,CSM_AV,VCU
 SG_ RFSCDS_BkCshBlstInOt : 5|3@0+ (1,0) [0|5] "" RadioLow,CSM,CSM_AV,VCU
 SG_ RFSCDS_BkBlstrInOut : 7|2@0+ (1,0) [0|3] "" RadioLow,CSM,CSM_AV,VCU
 SG_ RFSCDS_HdrstTltFwdRr : 8|2@0+ (1,0) [0|3] "" RadioLow,CSM,CSM_AV,VCU
 SG_ RFSCDS_HdrstFwdRrwd : 10|2@0+ (1,0) [0|3] "" RadioLow,CSM,CSM_AV,VCU
 SG_ RFSCDS_HdrstFdRrUDn : 13|3@0+ (1,0) [0|5] "" RadioLow,CSM,CSM_AV,VCU
 SG_ RFSCDS_DispReq : 14|1@0+ (1,0) [0|1] "" RadioLow,CSM,CSM_AV,VCU
 SG_ RFSCDS_LmbrUDnFdRr : 16|3@0+ (1,0) [0|5] "" RadioLow,CSM,CSM_AV,VCU
 SG_ RFSCDS_LmbrFwdRr : 18|2@0+ (1,0) [0|3] "" RadioLow,CSM,CSM_AV,VCU
 SG_ RFSCDS_HdrstWngInOt : 20|2@0+ (1,0) [0|3] "" RadioLow,CSM,CSM_AV,VCU
 SG_ RFSCDS_HdrstUpDn : 22|2@0+ (1,0) [0|3] "" RadioLow,CSM,CSM_AV,VCU
 SG_ RFSCDS_MassgIntsty : 25|3@0+ (1,0) [0|7] "" RadioLow,CSM,CSM_AV,VCU
 SG_ RFSCDS_Massg : 27|2@0+ (1,0) [0|2] "" RadioLow,CSM,CSM_AV,VCU
 SG_ RFSCDS_LmbrUpDwn : 29|2@0+ (1,0) [0|3] "" RadioLow,CSM,CSM_AV,VCU
 SG_ RideHghtSeltn1Pndg : 32|1@0+ (1,0) [0|1] "" IPC,IPC_INT,VCU
 SG_ RFSCDS_UprShldrFdRr : 34|2@0+ (1,0) [0|3] "" RadioLow,CSM,CSM_AV,VCU
 SG_ RFSCDS_MassgTyp : 38|4@0+ (1,0) [0|15] "" RadioLow,CSM,CSM_AV,VCU
 SG_ RideHghtSeltn5Pndg : 40|1@0+ (1,0) [0|1] "" IPC,IPC_INT,VCU
 SG_ RideHghtSeltn4Unv : 41|1@0+ (1,0) [0|1] "" IPC,IPC_INT,VCU
 SG_ RideHghtSeltn4Pndg : 42|1@0+ (1,0) [0|1] "" IPC,IPC_INT,VCU
 SG_ RideHghtSeltn3Unv : 43|1@0+ (1,0) [0|1] "" IPC,IPC_INT,VCU
 SG_ RideHghtSeltn3Pndg : 44|1@0+ (1,0) [0|1] "" IPC,IPC_INT,VCU
 SG_ RideHghtSeltn2Unv : 45|1@0+ (1,0) [0|1] "" IPC,IPC_INT,VCU
 SG_ RideHghtSeltn2Pndg : 46|1@0+ (1,0) [0|1] "" IPC,IPC_INT,VCU
 SG_ RideHghtSeltn1Unv : 47|1@0+ (1,0) [0|1] "" IPC,IPC_INT,VCU
 SG_ OATP_OtsAirTmpCrValAuth_Inv : 48|1@0+ (1,0) [0|1] "" PDR,RadioLow,CSM,CSM_AV,IPC,IPC_INT,VCU
 SG_ RideHghtSeltn8Unv : 49|1@0+ (1,0) [0|1] "" IPC,IPC_INT,VCU
 SG_ RideHghtSeltn8Pndg : 50|1@0+ (1,0) [0|1] "" IPC,IPC_INT,VCU
 SG_ RideHghtSeltn7Unv : 51|1@0+ (1,0) [0|1] "" IPC,IPC_INT,VCU
 SG_ RideHghtSeltn7Pndg : 52|1@0+ (1,0) [0|1] "" IPC,IPC_INT,VCU
 SG_ RideHghtSeltn6Unv : 53|1@0+ (1,0) [0|1] "" IPC,IPC_INT,VCU
 SG_ RideHghtSeltn6Pndg : 54|1@0+ (1,0) [0|1] "" IPC,IPC_INT,VCU
 SG_ RideHghtSeltn5Unv : 55|1@0+ (1,0) [0|1] "" IPC,IPC_INT,VCU
 SG_ OATP_OtsAirTmpCrValAuth : 63|8@0+ (0.5,-40) [-40|87.5] "Deg C" PDR,RadioLow,TCP,CSM,CSM_AV,IPC,IPC_INT,VCU

BO_ 1484 PDU_5034: 8 CGM
 SG_ RRSCDS_CshLgAdjFdRr : 0|2@0+ (1,0) [0|3] "" RadioLow,CSM,CSM_AV,VCU
 SG_ RRSCDS_CshBlstrInOut : 2|2@0+ (1,0) [0|3] "" RadioLow,CSM,CSM_AV,VCU
 SG_ RRSCDS_BkCshBlstInOt : 5|3@0+ (1,0) [0|5] "" RadioLow,CSM,CSM_AV,VCU
 SG_ RRSCDS_BkBlstrInOut : 7|2@0+ (1,0) [0|3] "" RadioLow,CSM,CSM_AV,VCU
 SG_ RRSCDS_HdrstTltFwdRr : 8|2@0+ (1,0) [0|3] "" RadioLow,CSM,CSM_AV,VCU
 SG_ RRSCDS_HdrstFwdRrwd : 10|2@0+ (1,0) [0|3] "" RadioLow,CSM,CSM_AV,VCU
 SG_ RRSCDS_HdrstFdRrUDn : 13|3@0+ (1,0) [0|5] "" RadioLow,CSM,CSM_AV,VCU
 SG_ RRSCDS_DispReq : 14|1@0+ (1,0) [0|1] "" RadioLow,CSM,CSM_AV,VCU
 SG_ RRSCDS_LmbrUDnFdRr : 16|3@0+ (1,0) [0|5] "" RadioLow,CSM,CSM_AV,VCU
 SG_ RRSCDS_LmbrFwdRr : 18|2@0+ (1,0) [0|3] "" RadioLow,CSM,CSM_AV,VCU
 SG_ RRSCDS_HdrstWngInOt : 20|2@0+ (1,0) [0|3] "" RadioLow,CSM,CSM_AV,VCU
 SG_ RRSCDS_HdrstUpDn : 22|2@0+ (1,0) [0|3] "" RadioLow,CSM,CSM_AV,VCU
 SG_ RRSCDS_MassgIntsty : 25|3@0+ (1,0) [0|7] "" RadioLow,CSM,CSM_AV,VCU
 SG_ RRSCDS_Massg : 27|2@0+ (1,0) [0|2] "" RadioLow,CSM,CSM_AV,VCU
 SG_ RRSCDS_LmbrUpDwn : 29|2@0+ (1,0) [0|3] "" RadioLow,CSM,CSM_AV,VCU
 SG_ RPARS_Lt : 32|4@0+ (1,0) [0|14] "" RadioLow,CSM,CSM_AV,IPC,IPC_INT,VCU
 SG_ RRSCDS_UprShldrFdRr : 34|2@0+ (1,0) [0|3] "" RadioLow,CSM,CSM_AV,VCU
 SG_ RRSCDS_MassgTyp : 38|4@0+ (1,0) [0|15] "" RadioLow,CSM,CSM_AV,VCU
 SG_ RPARS_Rt : 40|4@0+ (1,0) [0|14] "" RadioLow,CSM,CSM_AV,IPC,IPC_INT,VCU
 SG_ RPARS_LtCntr : 44|4@0+ (1,0) [0|14] "" RadioLow,CSM,CSM_AV,IPC,IPC_INT,VCU
 SG_ eLSDActrTrqPctg_Inv : 48|1@0+ (1,0) [0|1] "" PDR,IPC,IPC_INT,VCU
 SG_ RPARS_RtCntr : 52|4@0+ (1,0) [0|14] "" RadioLow,CSM,CSM_AV,IPC,IPC_INT,VCU
 SG_ eLSDActrTrqPctg : 63|8@0+ (0.4,0) [0|102] "%" PDR,IPC,IPC_INT,VCU

BA_DEF_ SG_  "SignalType" STRING ;
BA_DEF_ SG_  "SignalLongName" STRING ;
BA_DEF_ BO_  "GenMsgCycleTime" INT 0 10000;
BA_DEF_ BO_  "GenMsgSendType" ENUM "cyclicX","spontanX","cyclicIfActiveX","spontanWithDelay","cyclicAndSpontanX","cyclicAndSpontanWithDelay","spontanWithRepetition","cyclicIfActiveAndSpontanWD";
BA_DEF_DEF_  "SignalType" "";
BA_DEF_DEF_  "SignalLongName" "";
BA_DEF_DEF_  "GenMsgCycleTime" 0;
BA_DEF_DEF_  "GenMsgSendType" "cyclicX";
BA_ "GenMsgCycleTime" BO_ 1940 1000;
BA_ "GenMsgCycleTime" BO_ 1964 1000;
BA_ "GenMsgCycleTime" BO_ 1295 1000;
BA_ "GenMsgCycleTime" BO_ 1058 1000;
BA_ "GenMsgCycleTime" BO_ 1406 1000;
BA_ "GenMsgCycleTime" BO_ 1525 1000;
BA_ "GenMsgCycleTime" BO_ 75 10;
BA_ "GenMsgCycleTime" BO_ 76 10;
BA_ "GenMsgCycleTime" BO_ 52 10;
BA_ "GenMsgCycleTime" BO_ 99 10;
BA_ "GenMsgCycleTime" BO_ 43 10;
BA_ "GenMsgCycleTime" BO_ 705 100;
BA_ "GenMsgCycleTime" BO_ 204 30;
BA_ "GenMsgCycleTime" BO_ 1176 1000;
BA_ "GenMsgCycleTime" BO_ 701 100;
BA_ "GenMsgCycleTime" BO_ 115 10;
BA_ "GenMsgCycleTime" BO_ 928 250;
BA_ "GenMsgCycleTime" BO_ 703 100;
BA_ "GenMsgCycleTime" BO_ 704 100;
BA_ "GenMsgCycleTime" BO_ 932 250;
BA_ "GenMsgCycleTime" BO_ 933 250;
BA_ "GenMsgCycleTime" BO_ 934 250;
BA_ "GenMsgCycleTime" BO_ 718 100;
BA_ "GenMsgCycleTime" BO_ 681 100;
BA_ "GenMsgCycleTime" BO_ 719 100;
BA_ "GenMsgCycleTime" BO_ 936 250;
BA_ "GenMsgCycleTime" BO_ 937 500;
BA_ "GenMsgCycleTime" BO_ 938 500;
BA_ "GenMsgCycleTime" BO_ 1407 1000;
BA_ "GenMsgCycleTime" BO_ 1408 1000;
BA_ "GenMsgCycleTime" BO_ 1409 1000;
BA_ "GenMsgCycleTime" BO_ 1410 1000;
BA_ "GenMsgCycleTime" BO_ 1411 1000;
BA_ "GenMsgCycleTime" BO_ 1480 1000;
BA_ "GenMsgCycleTime" BO_ 1481 1000;
BA_ "GenMsgCycleTime" BO_ 1465 1000;
BA_ "GenMsgCycleTime" BO_ 1483 1000;
BA_ "GenMsgCycleTime" BO_ 1484 1000;
BA_ "SignalType" SG_ 1940 StCushFrtVertRRVirtCtlAval "ENM";
BA_ "SignalLongName" SG_ 1940 StCushFrtVertRRVirtCtlAval "Seat Right Rear Virtual Control Available Information : Seat Cushion Front Vertical Right Rear Virtual Control Available";
BA_ "SignalType" SG_ 1940 StBkSdBolsRRVirtCtlAval "ENM";
BA_ "SignalLongName" SG_ 1940 StBkSdBolsRRVirtCtlAval "Seat Right Rear Virtual Control Available Information : Seat Back Side Bolster Right Rear Virtual Control Available";
BA_ "SignalType" SG_ 1940 StBkLumbVertRRVirtCtlAval "ENM";
BA_ "SignalLongName" SG_ 1940 StBkLumbVertRRVirtCtlAval "Seat Right Rear Virtual Control Available Information : Seat Back Lumbar Vertical Right Rear Virtual Control Available";
BA_ "SignalType" SG_ 1940 StBkLumbHrztlRRVirtCtlAval "ENM";
BA_ "SignalLongName" SG_ 1940 StBkLumbHrztlRRVirtCtlAval "Seat Right Rear Virtual Control Available Information : Seat Back Lumbar Horizontal Right Rear Virtual Control Available";
BA_ "SignalType" SG_ 1940 StBkHrztlRRVirtCtlAval "ENM";
BA_ "SignalLongName" SG_ 1940 StBkHrztlRRVirtCtlAval "Seat Right Rear Virtual Control Available Information : Seat Back Horizontal Right Rear Virtual Control Available";
BA_ "SignalLongName" SG_ 1940 StMasgIntstyRRVirtCtlMaxLvl "Seat Right Rear Virtual Control Available Information : Seat Massage Intensity Right Rear Virtual Control Maximum Level";
BA_ "SignalType" SG_ 1940 StMasgTyp11RRVirtCtlAval "ENM";
BA_ "SignalLongName" SG_ 1940 StMasgTyp11RRVirtCtlAval "Seat Right Rear Virtual Control Available Information : Seat Massage Type 11 Right Rear Virtual Control Available";
BA_ "SignalType" SG_ 1940 StMasgTyp10RRVirtCtlAval "ENM";
BA_ "SignalLongName" SG_ 1940 StMasgTyp10RRVirtCtlAval "Seat Right Rear Virtual Control Available Information : Seat Massage Type 10 Right Rear Virtual Control Available";
BA_ "SignalType" SG_ 1940 StHdrstVertRRVirtCtlAval "ENM";
BA_ "SignalLongName" SG_ 1940 StHdrstVertRRVirtCtlAval "Seat Right Rear Virtual Control Available Information : Seat Headrest Vertical Right Rear Virtual Control Available";
BA_ "SignalType" SG_ 1940 StHdrstHrztlRRVirtCtlAval "ENM";
BA_ "SignalLongName" SG_ 1940 StHdrstHrztlRRVirtCtlAval "Seat Right Rear Virtual Control Available Information : Seat Headrest Horizontal Right Rear Virtual Control Available";
BA_ "SignalType" SG_ 1940 StCushSdBolsRRVirtCtlAval "ENM";
BA_ "SignalLongName" SG_ 1940 StCushSdBolsRRVirtCtlAval "Seat Right Rear Virtual Control Available Information : Seat Cushion Side Bolster Right Rear Virtual Control Available";
BA_ "SignalType" SG_ 1940 StCushRrVertRRVirtCtlAval "ENM";
BA_ "SignalLongName" SG_ 1940 StCushRrVertRRVirtCtlAval "Seat Right Rear Virtual Control Available Information : Seat Cushion Rear Vertical Right Rear Virtual Control Available";
BA_ "SignalType" SG_ 1940 StCushLgthHrztlRRVirtCtlAval "ENM";
BA_ "SignalLongName" SG_ 1940 StCushLgthHrztlRRVirtCtlAval "Seat Right Rear Virtual Control Available Information : Seat Cushion Length Horizontal Right Rear Virtual Control Available";
BA_ "SignalType" SG_ 1940 StCushHrztlRRVirtCtlAval "ENM";
BA_ "SignalLongName" SG_ 1940 StCushHrztlRRVirtCtlAval "Seat Right Rear Virtual Control Available Information : Seat Cushion Horizontal Right Rear Virtual Control Available";
BA_ "SignalType" SG_ 1940 StMasgTyp4RRVirtCtlAval "ENM";
BA_ "SignalLongName" SG_ 1940 StMasgTyp4RRVirtCtlAval "Seat Right Rear Virtual Control Available Information : Seat Massage Type 4 Right Rear Virtual Control Available";
BA_ "SignalType" SG_ 1940 StMasgTyp3RRVirtCtlAval "ENM";
BA_ "SignalLongName" SG_ 1940 StMasgTyp3RRVirtCtlAval "Seat Right Rear Virtual Control Available Information : Seat Massage Type 3 Right Rear Virtual Control Available";
BA_ "SignalType" SG_ 1940 StMasgTyp2RRVirtCtlAval "ENM";
BA_ "SignalLongName" SG_ 1940 StMasgTyp2RRVirtCtlAval "Seat Right Rear Virtual Control Available Information : Seat Massage Type 2 Right Rear Virtual Control Available";
BA_ "SignalType" SG_ 1940 StMasgTyp1RRVirtCtlAval "ENM";
BA_ "SignalLongName" SG_ 1940 StMasgTyp1RRVirtCtlAval "Seat Right Rear Virtual Control Available Information : Seat Massage Type 1 Right Rear Virtual Control Available";
BA_ "SignalType" SG_ 1940 StMasgTyp15RRVirtCtlAval "ENM";
BA_ "SignalLongName" SG_ 1940 StMasgTyp15RRVirtCtlAval "Seat Right Rear Virtual Control Available Information : Seat Massage Type 15 Right Rear Virtual Control Available";
BA_ "SignalType" SG_ 1940 StMasgTyp14RRVirtCtlAval "ENM";
BA_ "SignalLongName" SG_ 1940 StMasgTyp14RRVirtCtlAval "Seat Right Rear Virtual Control Available Information : Seat Massage Type 14 Right Rear Virtual Control Available";
BA_ "SignalType" SG_ 1940 StMasgTyp13RRVirtCtlAval "ENM";
BA_ "SignalLongName" SG_ 1940 StMasgTyp13RRVirtCtlAval "Seat Right Rear Virtual Control Available Information : Seat Massage Type 13 Right Rear Virtual Control Available";
BA_ "SignalType" SG_ 1940 StMasgTyp12RRVirtCtlAval "ENM";
BA_ "SignalLongName" SG_ 1940 StMasgTyp12RRVirtCtlAval "Seat Right Rear Virtual Control Available Information : Seat Massage Type 12 Right Rear Virtual Control Available";
BA_ "SignalType" SG_ 1940 StBkLumbHrztlRRVirtCtlAllwd "ENM";
BA_ "SignalLongName" SG_ 1940 StBkLumbHrztlRRVirtCtlAllwd "Seat Right Rear Virtual Control Allowed Information : Seat Back Lumbar Horizontal Right Rear Virtual Control Allowed";
BA_ "SignalType" SG_ 1940 StBkHrztlRRVirtCtlAllwd "ENM";
BA_ "SignalLongName" SG_ 1940 StBkHrztlRRVirtCtlAllwd "Seat Right Rear Virtual Control Allowed Information : Seat Back Horizontal Right Rear Virtual Control Allowed";
BA_ "SignalType" SG_ 1940 StUpprShldrHrztlRRVirtCtlAval "ENM";
BA_ "SignalLongName" SG_ 1940 StUpprShldrHrztlRRVirtCtlAval "Seat Right Rear Virtual Control Available Information : Seat Upper Shoulder Horizontal Right Rear Virtual Control Available";
BA_ "SignalType" SG_ 1940 StMasgTyp9RRVirtCtlAval "ENM";
BA_ "SignalLongName" SG_ 1940 StMasgTyp9RRVirtCtlAval "Seat Right Rear Virtual Control Available Information : Seat Massage Type 9 Right Rear Virtual Control Available";
BA_ "SignalType" SG_ 1940 StMasgTyp8RRVirtCtlAval "ENM";
BA_ "SignalLongName" SG_ 1940 StMasgTyp8RRVirtCtlAval "Seat Right Rear Virtual Control Available Information : Seat Massage Type 8 Right Rear Virtual Control Available";
BA_ "SignalType" SG_ 1940 StMasgTyp7RRVirtCtlAval "ENM";
BA_ "SignalLongName" SG_ 1940 StMasgTyp7RRVirtCtlAval "Seat Right Rear Virtual Control Available Information : Seat Massage Type 7 Right Rear Virtual Control Available";
BA_ "SignalType" SG_ 1940 StMasgTyp6RRVirtCtlAval "ENM";
BA_ "SignalLongName" SG_ 1940 StMasgTyp6RRVirtCtlAval "Seat Right Rear Virtual Control Available Information : Seat Massage Type 6 Right Rear Virtual Control Available";
BA_ "SignalType" SG_ 1940 StMasgTyp5RRVirtCtlAval "ENM";
BA_ "SignalLongName" SG_ 1940 StMasgTyp5RRVirtCtlAval "Seat Right Rear Virtual Control Available Information : Seat Massage Type 5 Right Rear Virtual Control Available";
BA_ "SignalType" SG_ 1940 StHdrstHrztlRRVirtCtlAllwd "ENM";
BA_ "SignalLongName" SG_ 1940 StHdrstHrztlRRVirtCtlAllwd "Seat Right Rear Virtual Control Allowed Information : Seat Headrest Horizontal Right Rear Virtual Control Allowed";
BA_ "SignalType" SG_ 1940 StCushSdBolsRRVirtCtlAllwd "ENM";
BA_ "SignalLongName" SG_ 1940 StCushSdBolsRRVirtCtlAllwd "Seat Right Rear Virtual Control Allowed Information : Seat Cushion Side Bolster Right Rear Virtual Control Allowed";
BA_ "SignalType" SG_ 1940 StCushRrVertRRVirtCtlAllwd "ENM";
BA_ "SignalLongName" SG_ 1940 StCushRrVertRRVirtCtlAllwd "Seat Right Rear Virtual Control Allowed Information : Seat Cushion Rear Vertical Right Rear Virtual Control Allowed";
BA_ "SignalType" SG_ 1940 StCushLgthHrztlRRVirtCtlAllwd "ENM";
BA_ "SignalLongName" SG_ 1940 StCushLgthHrztlRRVirtCtlAllwd "Seat Right Rear Virtual Control Allowed Information : Seat Cushion Length Horizontal Right Rear Virtual Control Allowed";
BA_ "SignalType" SG_ 1940 StCushHrztlRRVirtCtlAllwd "ENM";
BA_ "SignalLongName" SG_ 1940 StCushHrztlRRVirtCtlAllwd "Seat Right Rear Virtual Control Allowed Information : Seat Cushion Horizontal Right Rear Virtual Control Allowed";
BA_ "SignalType" SG_ 1940 StCushFrtVertRRVirtCtlAllwd "ENM";
BA_ "SignalLongName" SG_ 1940 StCushFrtVertRRVirtCtlAllwd "Seat Right Rear Virtual Control Allowed Information : Seat Cushion Front Vertical Right Rear Virtual Control Allowed";
BA_ "SignalType" SG_ 1940 StBkSdBolsRRVirtCtlAllwd "ENM";
BA_ "SignalLongName" SG_ 1940 StBkSdBolsRRVirtCtlAllwd "Seat Right Rear Virtual Control Allowed Information : Seat Back Side Bolster Right Rear Virtual Control Allowed";
BA_ "SignalType" SG_ 1940 StBkLumbVertRRVirtCtlAllwd "ENM";
BA_ "SignalLongName" SG_ 1940 StBkLumbVertRRVirtCtlAllwd "Seat Right Rear Virtual Control Allowed Information : Seat Back Lumbar Vertical Right Rear Virtual Control Allowed";
BA_ "SignalType" SG_ 1940 StMasgIntstyRRLstKnwnSet "ENM";
BA_ "SignalLongName" SG_ 1940 StMasgIntstyRRLstKnwnSet "Seat Right Rear Massage Setting Information : Seat Massage Intensity Right Rear Last Known Setting";
BA_ "SignalType" SG_ 1940 StMasgTypRRLstKnwnSet "ENM";
BA_ "SignalLongName" SG_ 1940 StMasgTypRRLstKnwnSet "Seat Right Rear Massage Setting Information : Seat Massage Type Right Rear Last Known Setting";
BA_ "SignalType" SG_ 1940 StUpprShldrHrztlRRVirtCtlAllwd "ENM";
BA_ "SignalLongName" SG_ 1940 StUpprShldrHrztlRRVirtCtlAllwd "Seat Right Rear Virtual Control Allowed Information : Seat Upper Shoulder Horizontal Right Rear Virtual Control Allowed";
BA_ "SignalType" SG_ 1940 StMasgRRVirtCtlAllwd "ENM";
BA_ "SignalLongName" SG_ 1940 StMasgRRVirtCtlAllwd "Seat Right Rear Virtual Control Allowed Information : Seat Massage Right Rear Virtual Control Allowed";
BA_ "SignalType" SG_ 1940 StHdrstVertRRVirtCtlAllwd "ENM";
BA_ "SignalLongName" SG_ 1940 StHdrstVertRRVirtCtlAllwd "Seat Right Rear Virtual Control Allowed Information : Seat Headrest Vertical Right Rear Virtual Control Allowed";
BA_ "SignalType" SG_ 1940 StMemRRVirtCtlNumofMemPstnsAval "ENM";
BA_ "SignalLongName" SG_ 1940 StMemRRVirtCtlNumofMemPstnsAval "Seat Memory Right Rear Virtual Control Number of Memory Positions Available";
BA_ "SignalType" SG_ 1940 StMemRRVirtCtlNumofExtPstnsAval "ENM";
BA_ "SignalLongName" SG_ 1940 StMemRRVirtCtlNumofExtPstnsAval "Seat Memory Right Rear Virtual Control Number of Exit Positions Available";
BA_ "SignalType" SG_ 1964 StCushFrtVertLRVirtCtlAval "ENM";
BA_ "SignalLongName" SG_ 1964 StCushFrtVertLRVirtCtlAval "Seat Left Rear Virtual Control Available Information : Seat Cushion Front Vertical Left Rear Virtual Control Available";
BA_ "SignalType" SG_ 1964 StBkSdBolsLRVirtCtlAval "ENM";
BA_ "SignalLongName" SG_ 1964 StBkSdBolsLRVirtCtlAval "Seat Left Rear Virtual Control Available Information : Seat Back Side Bolster Left Rear Virtual Control Available";
BA_ "SignalType" SG_ 1964 StBkLumbVertLRVirtCtlAval "ENM";
BA_ "SignalLongName" SG_ 1964 StBkLumbVertLRVirtCtlAval "Seat Left Rear Virtual Control Available Information : Seat Back Lumbar Vertical Left Rear Virtual Control Available";
BA_ "SignalType" SG_ 1964 StBkLumbHrztlLRVirtCtlAval "ENM";
BA_ "SignalLongName" SG_ 1964 StBkLumbHrztlLRVirtCtlAval "Seat Left Rear Virtual Control Available Information : Seat Back Lumbar Horizontal Left Rear Virtual Control Available";
BA_ "SignalType" SG_ 1964 StBkHrztlLRVirtCtlAval "ENM";
BA_ "SignalLongName" SG_ 1964 StBkHrztlLRVirtCtlAval "Seat Left Rear Virtual Control Available Information : Seat Back Horizontal Left Rear Virtual Control Available";
BA_ "SignalLongName" SG_ 1964 StMasgIntstyLRVirtCtlMaxLvl "Seat Left Rear Virtual Control Available Information : Seat Massage Intensity Left Rear Virtual Control Maximum Level";
BA_ "SignalType" SG_ 1964 StMasgTyp11LRVirtCtlAval "ENM";
BA_ "SignalLongName" SG_ 1964 StMasgTyp11LRVirtCtlAval "Seat Left Rear Virtual Control Available Information : Seat Massage Type 11 Left Rear Virtual Control Available";
BA_ "SignalType" SG_ 1964 StMasgTyp10LRVirtCtlAval "ENM";
BA_ "SignalLongName" SG_ 1964 StMasgTyp10LRVirtCtlAval "Seat Left Rear Virtual Control Available Information : Seat Massage Type 10 Left Rear Virtual Control Available";
BA_ "SignalType" SG_ 1964 StHdrstVertLRVirtCtlAval "ENM";
BA_ "SignalLongName" SG_ 1964 StHdrstVertLRVirtCtlAval "Seat Left Rear Virtual Control Available Information : Seat Headrest Vertical Left Rear Virtual Control Available";
BA_ "SignalType" SG_ 1964 StHdrstHrztlLRVirtCtlAval "ENM";
BA_ "SignalLongName" SG_ 1964 StHdrstHrztlLRVirtCtlAval "Seat Left Rear Virtual Control Available Information : Seat Headrest Horizontal Left Rear Virtual Control Available";
BA_ "SignalType" SG_ 1964 StCushSdBolsLRVirtCtlAval "ENM";
BA_ "SignalLongName" SG_ 1964 StCushSdBolsLRVirtCtlAval "Seat Left Rear Virtual Control Available Information : Seat Cushion Side Bolster Left Rear Virtual Control Available";
BA_ "SignalType" SG_ 1964 StCushRrVertLRVirtCtlAval "ENM";
BA_ "SignalLongName" SG_ 1964 StCushRrVertLRVirtCtlAval "Seat Left Rear Virtual Control Available Information : Seat Cushion Rear Vertical Left Rear Virtual Control Available";
BA_ "SignalType" SG_ 1964 StCushLgthHrztlLRVirtCtlAval "ENM";
BA_ "SignalLongName" SG_ 1964 StCushLgthHrztlLRVirtCtlAval "Seat Left Rear Virtual Control Available Information : Seat Cushion Length Horizontal Left Rear Virtual Control Available";
BA_ "SignalType" SG_ 1964 StCushHrztlLRVirtCtlAval "ENM";
BA_ "SignalLongName" SG_ 1964 StCushHrztlLRVirtCtlAval "Seat Left Rear Virtual Control Available Information : Seat Cushion Horizontal Left Rear Virtual Control Available";
BA_ "SignalType" SG_ 1964 StMasgTyp4LRVirtCtlAval "ENM";
BA_ "SignalLongName" SG_ 1964 StMasgTyp4LRVirtCtlAval "Seat Left Rear Virtual Control Available Information : Seat Massage Type 4 Left Rear Virtual Control Available";
BA_ "SignalType" SG_ 1964 StMasgTyp3LRVirtCtlAval "ENM";
BA_ "SignalLongName" SG_ 1964 StMasgTyp3LRVirtCtlAval "Seat Left Rear Virtual Control Available Information : Seat Massage Type 3 Left Rear Virtual Control Available";
BA_ "SignalType" SG_ 1964 StMasgTyp2LRVirtCtlAval "ENM";
BA_ "SignalLongName" SG_ 1964 StMasgTyp2LRVirtCtlAval "Seat Left Rear Virtual Control Available Information : Seat Massage Type 2 Left Rear Virtual Control Available";
BA_ "SignalType" SG_ 1964 StMasgTyp1LRVirtCtlAval "ENM";
BA_ "SignalLongName" SG_ 1964 StMasgTyp1LRVirtCtlAval "Seat Left Rear Virtual Control Available Information : Seat Massage Type 1 Left Rear Virtual Control Available";
BA_ "SignalType" SG_ 1964 StMasgTyp15LRVirtCtlAval "ENM";
BA_ "SignalLongName" SG_ 1964 StMasgTyp15LRVirtCtlAval "Seat Left Rear Virtual Control Available Information : Seat Massage Type 15 Left Rear Virtual Control Available";
BA_ "SignalType" SG_ 1964 StMasgTyp14LRVirtCtlAval "ENM";
BA_ "SignalLongName" SG_ 1964 StMasgTyp14LRVirtCtlAval "Seat Left Rear Virtual Control Available Information : Seat Massage Type 14 Left Rear Virtual Control Available";
BA_ "SignalType" SG_ 1964 StMasgTyp13LRVirtCtlAval "ENM";
BA_ "SignalLongName" SG_ 1964 StMasgTyp13LRVirtCtlAval "Seat Left Rear Virtual Control Available Information : Seat Massage Type 13 Left Rear Virtual Control Available";
BA_ "SignalType" SG_ 1964 StMasgTyp12LRVirtCtlAval "ENM";
BA_ "SignalLongName" SG_ 1964 StMasgTyp12LRVirtCtlAval "Seat Left Rear Virtual Control Available Information : Seat Massage Type 12 Left Rear Virtual Control Available";
BA_ "SignalType" SG_ 1964 StMemLRVirtCtlNumofExtPstnsAval "ENM";
BA_ "SignalLongName" SG_ 1964 StMemLRVirtCtlNumofExtPstnsAval "Seat Memory Left Rear Virtual Control Number of Exit Positions Available";
BA_ "SignalType" SG_ 1964 StUpprShldrHrztlLRVirtCtlAval "ENM";
BA_ "SignalLongName" SG_ 1964 StUpprShldrHrztlLRVirtCtlAval "Seat Left Rear Virtual Control Available Information : Seat Upper Shoulder Horizontal Left Rear Virtual Control Available";
BA_ "SignalType" SG_ 1964 StMasgTyp9LRVirtCtlAval "ENM";
BA_ "SignalLongName" SG_ 1964 StMasgTyp9LRVirtCtlAval "Seat Left Rear Virtual Control Available Information : Seat Massage Type 9 Left Rear Virtual Control Available";
BA_ "SignalType" SG_ 1964 StMasgTyp8LRVirtCtlAval "ENM";
BA_ "SignalLongName" SG_ 1964 StMasgTyp8LRVirtCtlAval "Seat Left Rear Virtual Control Available Information : Seat Massage Type 8 Left Rear Virtual Control Available";
BA_ "SignalType" SG_ 1964 StMasgTyp7LRVirtCtlAval "ENM";
BA_ "SignalLongName" SG_ 1964 StMasgTyp7LRVirtCtlAval "Seat Left Rear Virtual Control Available Information : Seat Massage Type 7 Left Rear Virtual Control Available";
BA_ "SignalType" SG_ 1964 StMasgTyp6LRVirtCtlAval "ENM";
BA_ "SignalLongName" SG_ 1964 StMasgTyp6LRVirtCtlAval "Seat Left Rear Virtual Control Available Information : Seat Massage Type 6 Left Rear Virtual Control Available";
BA_ "SignalType" SG_ 1964 StMasgTyp5LRVirtCtlAval "ENM";
BA_ "SignalLongName" SG_ 1964 StMasgTyp5LRVirtCtlAval "Seat Left Rear Virtual Control Available Information : Seat Massage Type 5 Left Rear Virtual Control Available";
BA_ "SignalType" SG_ 1964 RrDrOpnCmfRclCstAvlFlg2 "ENM";
BA_ "SignalLongName" SG_ 1964 RrDrOpnCmfRclCstAvlFlg2 "Rear Door Open Comfort Recall Customization Availability Flag 2";
BA_ "SignalType" SG_ 1964 RrDrOpnCmfRclCstAvlFlg1 "ENM";
BA_ "SignalLongName" SG_ 1964 RrDrOpnCmfRclCstAvlFlg1 "Rear Door Open Comfort Recall Customization Availability Flag 1";
BA_ "SignalType" SG_ 1964 StMemLRVirtCtlNumofMemPstnsAval "ENM";
BA_ "SignalLongName" SG_ 1964 StMemLRVirtCtlNumofMemPstnsAval "Seat Memory Left Rear Virtual Control Number of Memory Positions Available";
BA_ "SignalType" SG_ 1964 RrDrOpnCmfRclCstSetAval "ENM";
BA_ "SignalLongName" SG_ 1964 RrDrOpnCmfRclCstSetAval "Rear Door Open Comfort Recall Customization Setting Available";
BA_ "SignalType" SG_ 1964 RrDrOpnCmfRclCstAvlFlg7 "ENM";
BA_ "SignalLongName" SG_ 1964 RrDrOpnCmfRclCstAvlFlg7 "Rear Door Open Comfort Recall Customization Availability Flag 7";
BA_ "SignalType" SG_ 1964 RrDrOpnCmfRclCstAvlFlg6 "ENM";
BA_ "SignalLongName" SG_ 1964 RrDrOpnCmfRclCstAvlFlg6 "Rear Door Open Comfort Recall Customization Availability Flag 6";
BA_ "SignalType" SG_ 1964 RrDrOpnCmfRclCstAvlFlg5 "ENM";
BA_ "SignalLongName" SG_ 1964 RrDrOpnCmfRclCstAvlFlg5 "Rear Door Open Comfort Recall Customization Availability Flag 5";
BA_ "SignalType" SG_ 1964 RrDrOpnCmfRclCstAvlFlg4 "ENM";
BA_ "SignalLongName" SG_ 1964 RrDrOpnCmfRclCstAvlFlg4 "Rear Door Open Comfort Recall Customization Availability Flag 4";
BA_ "SignalType" SG_ 1964 RrDrOpnCmfRclCstAvlFlg3 "ENM";
BA_ "SignalLongName" SG_ 1964 RrDrOpnCmfRclCstAvlFlg3 "Rear Door Open Comfort Recall Customization Availability Flag 3";
BA_ "SignalType" SG_ 1295 SCAOOAByVirtKeyRFCstCurrSetVal "ENM";
BA_ "SignalLongName" SG_ 1295 SCAOOAByVirtKeyRFCstCurrSetVal "Side Closure Access Open On Approach By Virtual Key Right Front Customization Current Setting Value";
BA_ "SignalType" SG_ 1295 SCAOOAByKeyFobRFCstCurrSetVal "ENM";
BA_ "SignalLongName" SG_ 1295 SCAOOAByKeyFobRFCstCurrSetVal "Side Closure Access Open On Approach By Key Fob Right Front Customization Current Setting Value";
BA_ "SignalType" SG_ 1058 PwrSdClsrRRBlckdIndOn "ENM";
BA_ "SignalLongName" SG_ 1058 PwrSdClsrRRBlckdIndOn "Power Side Closure Right Rear Blocked Indication On";
BA_ "SignalType" SG_ 1058 PwrSdClsrRRServIndOn "ENM";
BA_ "SignalLongName" SG_ 1058 PwrSdClsrRRServIndOn "Power Side Closure Right Rear Service Indication On";
BA_ "SignalType" SG_ 1406 ASS_DSPMd6Prsnt "ENM";
BA_ "SignalLongName" SG_ 1406 ASS_DSPMd6Prsnt "Amplifier Sink State : DSP Mode 6 Present";
BA_ "SignalType" SG_ 1406 ASS_DSPMd5Prsnt "ENM";
BA_ "SignalLongName" SG_ 1406 ASS_DSPMd5Prsnt "Amplifier Sink State : DSP Mode 5 Present";
BA_ "SignalType" SG_ 1406 ASS_DSPMd4Prsnt "ENM";
BA_ "SignalLongName" SG_ 1406 ASS_DSPMd4Prsnt "Amplifier Sink State : DSP Mode 4 Present";
BA_ "SignalType" SG_ 1406 ASS_DSPMd3Prsnt "ENM";
BA_ "SignalLongName" SG_ 1406 ASS_DSPMd3Prsnt "Amplifier Sink State : DSP Mode 3 Present";
BA_ "SignalType" SG_ 1406 ASS_DSPMd2Prsnt "ENM";
BA_ "SignalLongName" SG_ 1406 ASS_DSPMd2Prsnt "Amplifier Sink State : DSP Mode 2 Present";
BA_ "SignalType" SG_ 1406 ASS_DSPMd1Prsnt "ENM";
BA_ "SignalLongName" SG_ 1406 ASS_DSPMd1Prsnt "Amplifier Sink State : DSP Mode 1 Present";
BA_ "SignalType" SG_ 1406 ASS_DSPMd0Prsnt "ENM";
BA_ "SignalLongName" SG_ 1406 ASS_DSPMd0Prsnt "Amplifier Sink State : DSP Mode 0 Present";
BA_ "SignalType" SG_ 1406 ASS_DSPAvail "ENM";
BA_ "SignalLongName" SG_ 1406 ASS_DSPAvail "Amplifier Sink State : DSP Available";
BA_ "SignalLongName" SG_ 1406 CrtclChmPrdcrStat "Critical Chime Producer Status";
BA_ "SignalType" SG_ 1406 ASS_VehNoisCmpnAvail "ENM";
BA_ "SignalLongName" SG_ 1406 ASS_VehNoisCmpnAvail "Amplifier Sink State : Vehicle Noise Compensation Available";
BA_ "SignalType" SG_ 1406 ASS_SurndAvail "ENM";
BA_ "SignalLongName" SG_ 1406 ASS_SurndAvail "Amplifier Sink State : Suround Available";
BA_ "SignalType" SG_ 1406 ASS_PhLckdLpLckd "ENM";
BA_ "SignalLongName" SG_ 1406 ASS_PhLckdLpLckd "Amplifier Sink State : Phase Locked Loop Locked";
BA_ "SignalType" SG_ 1406 ASS_MtxSnkMutStat "ENM";
BA_ "SignalLongName" SG_ 1406 ASS_MtxSnkMutStat "Amplifier Sink State : Mutex Sink Mute State";
BA_ "SignalType" SG_ 1406 ASS_DSPMd7Prsnt "ENM";
BA_ "SignalLongName" SG_ 1406 ASS_DSPMd7Prsnt "Amplifier Sink State : DSP Mode 7 Present";
BA_ "SignalType" SG_ 1406 FrtPsngrMtxSnkMutSts "ENM";
BA_ "SignalLongName" SG_ 1406 FrtPsngrMtxSnkMutSts "Front Passenger Mutex Sink Mute Status";
BA_ "SignalLongName" SG_ 1406 CCSI_PV "Critical Chime Status Information : Protection Value";
BA_ "SignalType" SG_ 1406 CCSI_CrtclChmPrdcrSOH "ENM";
BA_ "SignalLongName" SG_ 1406 CCSI_CrtclChmPrdcrSOH "Critical Chime Status Information : Critical Chime Producer State of Health";
BA_ "SignalLongName" SG_ 1406 CCSI_ARC "Critical Chime Status Information : Alive Rolling Count";
BA_ "SignalLongName" SG_ 1406 AmpSOHALAudblFbkSnkLvlCurrVal "Amplifier State Of Health Audio Leveling Information : Amplifier State Of Health Audio Leveling Audible Feedback Sink Level Current Value";
BA_ "SignalType" SG_ 1406 AmpCallAudPlybkSOH "ENM";
BA_ "SignalLongName" SG_ 1406 AmpCallAudPlybkSOH "Amplifier Call Audio Playback State of Health";
BA_ "SignalType" SG_ 1406 RRMtxSnkMutSts "ENM";
BA_ "SignalLongName" SG_ 1406 RRMtxSnkMutSts "Right Rear Mutex Sink Mute Status";
BA_ "SignalType" SG_ 1406 LRMtxSnkMutSts "ENM";
BA_ "SignalLongName" SG_ 1406 LRMtxSnkMutSts "Left Rear Mutex Sink Mute Status";
BA_ "SignalLongName" SG_ 1406 AmpSOHALMixPrmtSnkLvlCurrVal "Amplifier State Of Health Audio Leveling Information : Amplifier State Of Health Audio Leveling Mix Prompt Sink Level Current Value";
BA_ "SignalLongName" SG_ 1406 AmpSOHALMtxSnkLvlCurrVal "Amplifier State Of Health Audio Leveling Information : Amplifier State Of Health Audio Leveling Mutex Sink Level Current Value";
BA_ "SignalType" SG_ 1406 AmpSOHALAutoLdnsCmpnAtv "ENM";
BA_ "SignalLongName" SG_ 1406 AmpSOHALAutoLdnsCmpnAtv "Amplifier State Of Health Audio Leveling Information : Amplifier State Of Health Audio Leveling Automatic Loudness Compensation Active";
BA_ "SignalType" SG_ 1406 AmpSOHALMutCaus "ENM";
BA_ "SignalLongName" SG_ 1406 AmpSOHALMutCaus "Amplifier State Of Health Audio Leveling Information : Amplifier State Of Health Audio Leveling Mute Cause";
BA_ "SignalType" SG_ 1525 PhnZnAudSOH "ENM";
BA_ "SignalLongName" SG_ 1525 PhnZnAudSOH "Phone Zone Audio State Of Health";
BA_ "SignalType" SG_ 1525 QdZnAudVolCtlAval "ENM";
BA_ "SignalLongName" SG_ 1525 QdZnAudVolCtlAval "Quad Zone Audio Volume Control Available";
BA_ "SignalType" SG_ 1525 FrtZnAudVolCtlAval "ENM";
BA_ "SignalLongName" SG_ 1525 FrtZnAudVolCtlAval "Front Zone Audio Volume Control Available";
BA_ "SignalType" SG_ 1525 DirAudPrmtRndrngActv "ENM";
BA_ "SignalLongName" SG_ 1525 DirAudPrmtRndrngActv "Directional Audio Prompt Rendering Active";
BA_ "SignalType" SG_ 1525 HMIInCarVcCommSts "ENM";
BA_ "SignalLongName" SG_ 1525 HMIInCarVcCommSts "HMI In Car Voice Communication Status";
BA_ "SignalType" SG_ 1525 PhnZnAval "ENM";
BA_ "SignalLongName" SG_ 1525 PhnZnAval "Phone Zone Available";
BA_ "SignalLongName" SG_ 75 TachEngSpd "Tachometer Engine Speed";
BA_ "SignalLongName" SG_ 75 YawRateAuth "Serial Data 46 Protected : Yaw Rate Authenticated";
BA_ "SignalLongName" SG_ 75 HVPPP_HstVehLngVelAuth "Host Vehicle Path Parameters Protected : Host Vehicle Longitudinal Velocity Authenticated";
BA_ "SignalType" SG_ 75 YawRateAuth_Inv "ENM";
BA_ "SignalLongName" SG_ 75 YawRateAuth_Inv "Serial Data 46 Protected : Yaw Rate Authenticated Invalid";
BA_ "SignalType" SG_ 75 YawRateAuth_DuD "ENM";
BA_ "SignalLongName" SG_ 75 YawRateAuth_DuD "Serial Data 46 Protected : Yaw Rate Authenticated Don't Use Data";
BA_ "SignalLongName" SG_ 75 HVPPP_HstVehYawRateAuth "Host Vehicle Path Parameters Protected : Host Vehicle Yaw Rate Authenticated";
BA_ "SignalType" SG_ 75 BGI3P_BrkPedPstnAuth_Inv "ENM";
BA_ "SignalLongName" SG_ 75 BGI3P_BrkPedPstnAuth_Inv "Body General Information 3 Protected : Brake Pedal Position Authenticated Invalid";
BA_ "SignalLongName" SG_ 75 BGI3P_BrkPedPstnAuth "Body General Information 3 Protected : Brake Pedal Position Authenticated";
BA_ "SignalLongName" SG_ 76 LatAccelAuth "Serial Data 46 Protected : Lateral Acceleration Authenticated";
BA_ "SignalType" SG_ 76 LatAccelAuth_Inv "ENM";
BA_ "SignalLongName" SG_ 76 LatAccelAuth_Inv "Serial Data 46 Protected : Lateral Acceleration Authenticated Invalid";
BA_ "SignalLongName" SG_ 76 LongAccelAuth "Serial Data 46 Protected : Longitudinal Acceleration Authenticated";
BA_ "SignalType" SG_ 76 LongAccelAuth_Inv "ENM";
BA_ "SignalLongName" SG_ 76 LongAccelAuth_Inv "Serial Data 46 Protected : Longitudinal Acceleration Authenticated Invalid";
BA_ "SignalLongName" SG_ 76 HVPPP_HstVehLatVelAuth "Host Vehicle Path Parameters Protected : Host Vehicle Lateral Velocity Authenticated";
BA_ "SignalType" SG_ 76 BGI3P_BrkPedModrTrvlAchAuth "ENM";
BA_ "SignalLongName" SG_ 76 BGI3P_BrkPedModrTrvlAchAuth "Body General Information 3 Protected : Brake Pedal Moderate Travel Achieved Authenticated";
BA_ "SignalType" SG_ 76 BGI3P_BrkPedModrTrvlAchAuth_Inv "ENM";
BA_ "SignalLongName" SG_ 76 BGI3P_BrkPedModrTrvlAchAuth_Inv "Body General Information 3 Protected : Brake Pedal Moderate Travel Achieved Authenticated Invalid";
BA_ "SignalType" SG_ 76 BGI3P_BrkPedInitTrvlAchAuth "ENM";
BA_ "SignalLongName" SG_ 76 BGI3P_BrkPedInitTrvlAchAuth "Body General Information 3 Protected : Brake Pedal Initial Travel Achieved Authenticated";
BA_ "SignalType" SG_ 76 BGI3P_BrkPedInitTrvlAchAuth_Inv "ENM";
BA_ "SignalLongName" SG_ 76 BGI3P_BrkPedInitTrvlAchAuth_Inv "Body General Information 3 Protected : Brake Pedal Initial Travel Achieved Authenticated Invalid";
BA_ "SignalType" SG_ 41 VCBA_FrtJnctnActv "ENM";
BA_ "SignalLongName" SG_ 41 VCBA_FrtJnctnActv "Viewing Control Button Availability : Front Junction Active";
BA_ "SignalType" SG_ 41 VCBA_DynGdlnsActv "ENM";
BA_ "SignalLongName" SG_ 41 VCBA_DynGdlnsActv "Viewing Control Button Availability : Dynamic Guidelines Active";
BA_ "SignalType" SG_ 41 VCBA_CurbVwGdlnsActv "ENM";
BA_ "SignalLongName" SG_ 41 VCBA_CurbVwGdlnsActv "Viewing Control Button Availability : Curb View Guidelines Active";
BA_ "SignalType" SG_ 41 VCBA_CurbOvrhdActv "ENM";
BA_ "SignalLongName" SG_ 41 VCBA_CurbOvrhdActv "Viewing Control Button Availability : Curb Overhead Active";
BA_ "SignalType" SG_ 41 VCBA_CurbActv "ENM";
BA_ "SignalLongName" SG_ 41 VCBA_CurbActv "Viewing Control Button Availability : Curb Active";
BA_ "SignalType" SG_ 41 VCBA_CrgBedActv "ENM";
BA_ "SignalLongName" SG_ 41 VCBA_CrgBedActv "Viewing Control Button Availability : Cargo Bed Active";
BA_ "SignalType" SG_ 41 VCBA_BowlActv "ENM";
BA_ "SignalLongName" SG_ 41 VCBA_BowlActv "Viewing Control Button Availability : Bowl Active";
BA_ "SignalType" SG_ 41 VCBA_BedHtchActv "ENM";
BA_ "SignalLongName" SG_ 41 VCBA_BedHtchActv "Viewing Control Button Availability : Bed Hitch Active";
BA_ "SignalType" SG_ 41 VCBA_RrOvrhdActv "ENM";
BA_ "SignalLongName" SG_ 41 VCBA_RrOvrhdActv "Viewing Control Button Availability : Rear Overhead Active";
BA_ "SignalType" SG_ 41 VCBA_RrJnctnActv "ENM";
BA_ "SignalLongName" SG_ 41 VCBA_RrJnctnActv "Viewing Control Button Availability : Rear Junction Active";
BA_ "SignalType" SG_ 41 VCBA_RrHtchActv "ENM";
BA_ "SignalLongName" SG_ 41 VCBA_RrHtchActv "Viewing Control Button Availability : Rear Hitch Active";
BA_ "SignalType" SG_ 41 VCBA_LRTrlrTowMirActv "ENM";
BA_ "SignalLongName" SG_ 41 VCBA_LRTrlrTowMirActv "Viewing Control Button Availability : L R Trailer Towing Mirror Active";
BA_ "SignalType" SG_ 41 VCBA_JPActv "ENM";
BA_ "SignalLongName" SG_ 41 VCBA_JPActv "Viewing Control Button Availability : Japan Active";
BA_ "SignalType" SG_ 41 VCBA_InvsblTrlrActv "ENM";
BA_ "SignalLongName" SG_ 41 VCBA_InvsblTrlrActv "Viewing Control Button Availability : Invisible Trailer Active";
BA_ "SignalType" SG_ 41 VCBA_FrtPrspctvActv "ENM";
BA_ "SignalLongName" SG_ 41 VCBA_FrtPrspctvActv "Viewing Control Button Availability : Front Perspective Active";
BA_ "SignalType" SG_ 41 VCBA_FrtOvrhdActv "ENM";
BA_ "SignalLongName" SG_ 41 VCBA_FrtOvrhdActv "Viewing Control Button Availability : Front Overhead Active";
BA_ "SignalType" SG_ 41 VCBA_TrlrTowMirActv "ENM";
BA_ "SignalLongName" SG_ 41 VCBA_TrlrTowMirActv "Viewing Control Button Availability : Trailer Towing Mirror Active";
BA_ "SignalType" SG_ 41 VCBA_TrlrGdlnsActv "ENM";
BA_ "SignalLongName" SG_ 41 VCBA_TrlrGdlnsActv "Viewing Control Button Availability : Trailer Guidelines Active";
BA_ "SignalType" SG_ 41 VCBA_TrlrAux2Actv "ENM";
BA_ "SignalLongName" SG_ 41 VCBA_TrlrAux2Actv "Viewing Control Button Availability : Trailer Aux2 Active";
BA_ "SignalType" SG_ 41 VCBA_TrlrAux1CmbdActv "ENM";
BA_ "SignalLongName" SG_ 41 VCBA_TrlrAux1CmbdActv "Viewing Control Button Availability : Trailer Aux1 Combined Active";
BA_ "SignalType" SG_ 41 VCBA_TrlrAux1Actv "ENM";
BA_ "SignalLongName" SG_ 41 VCBA_TrlrAux1Actv "Viewing Control Button Availability : Trailer Aux1 Active";
BA_ "SignalType" SG_ 41 VCBA_SdRrwdActv "ENM";
BA_ "SignalLongName" SG_ 41 VCBA_SdRrwdActv "Viewing Control Button Availability : Side Rearward Active";
BA_ "SignalType" SG_ 41 VCBA_SdFrwdActv "ENM";
BA_ "SignalLongName" SG_ 41 VCBA_SdFrwdActv "Viewing Control Button Availability : Side Forward Active";
BA_ "SignalType" SG_ 41 VCBA_RrPrspctvActv "ENM";
BA_ "SignalLongName" SG_ 41 VCBA_RrPrspctvActv "Viewing Control Button Availability : Rear Perspective Active";
BA_ "SignalLongName" SG_ 41 VwgBowlVwAngSts "Viewing Bowl View Angle Status";
BA_ "SignalType" SG_ 41 VCBA_ZmdBowlActv "ENM";
BA_ "SignalLongName" SG_ 41 VCBA_ZmdBowlActv "Viewing Control Button Availability : Zoomed Bowl Active";
BA_ "SignalType" SG_ 41 VCBA_TrnspHdActv "ENM";
BA_ "SignalLongName" SG_ 41 VCBA_TrnspHdActv "Viewing Control Button Availability : Transparent Hood Active";
BA_ "SignalLongName" SG_ 41 SrrndVsnRcrdrNumDispdFiles "Surround Vision Recorder Number of Displayed Files";
BA_ "SignalType" SG_ 41 SrrndVsnRcrdrDelFileReqSts "ENM";
BA_ "SignalLongName" SG_ 41 SrrndVsnRcrdrDelFileReqSts "Surround Vision Recorder Delete File Request Status";
BA_ "SignalType" SG_ 41 SrrndVsnRcrdrVwprtSts "ENM";
BA_ "SignalLongName" SG_ 41 SrrndVsnRcrdrVwprtSts "Surround Vision Recorder Viewport Status";
BA_ "SignalType" SG_ 41 SrrndVsnRcrdrVwprtReq "ENM";
BA_ "SignalLongName" SG_ 41 SrrndVsnRcrdrVwprtReq "Surround Vision Recorder Viewport Request";
BA_ "SignalType" SG_ 41 SrrndVsnRcrdrPlybkSts "ENM";
BA_ "SignalLongName" SG_ 41 SrrndVsnRcrdrPlybkSts "Surround Vision Recorder Playback Status";
BA_ "SignalType" SG_ 41 SrrndVsnRcrdrRcrdSts "ENM";
BA_ "SignalLongName" SG_ 41 SrrndVsnRcrdrRcrdSts "Surround Vision Recorder Record Status";
BA_ "SignalType" SG_ 41 SrrndVsnRcrdrListPgSts "ENM";
BA_ "SignalLongName" SG_ 41 SrrndVsnRcrdrListPgSts "Surround Vision Recorder List Page Status";
BA_ "SignalType" SG_ 41 VGVS_TrlrActv "ENM";
BA_ "SignalLongName" SG_ 41 VGVS_TrlrActv "Viewing Guideline View Status : Trailer Active";
BA_ "SignalType" SG_ 41 VGVS_DynActv "ENM";
BA_ "SignalLongName" SG_ 41 VGVS_DynActv "Viewing Guideline View Status : Dynamic Active";
BA_ "SignalType" SG_ 41 VGVS_CurbVwActv "ENM";
BA_ "SignalLongName" SG_ 41 VGVS_CurbVwActv "Viewing Guideline View Status : Curb View Active";
BA_ "SignalType" SG_ 41 SrrndVsnRcrdrRcrdgActv "ENM";
BA_ "SignalLongName" SG_ 41 SrrndVsnRcrdrRcrdgActv "Surround Vision Recorder Recording Active";
BA_ "SignalType" SG_ 41 ClsnEvntDatRcrdgTrgrd "ENM";
BA_ "SignalLongName" SG_ 41 ClsnEvntDatRcrdgTrgrd "Collision Event Data Recording Triggered";
BA_ "SignalType" SG_ 41 SVRCBA_PgUpActv "ENM";
BA_ "SignalLongName" SG_ 41 SVRCBA_PgUpActv "Surround Vision Recorder Control Button Availability : Page Up Active";
BA_ "SignalType" SG_ 41 SVRCBA_PgDnActv "ENM";
BA_ "SignalLongName" SG_ 41 SVRCBA_PgDnActv "Surround Vision Recorder Control Button Availability : Page Down Active";
BA_ "SignalLongName" SG_ 52 AATP_ActAxlTrqAuth "Serial Data 19 Protected : Actual Axle Torque Authenticated";
BA_ "SignalType" SG_ 52 AATP_ActAxlTrqAuth_Inv "ENM";
BA_ "SignalLongName" SG_ 52 AATP_ActAxlTrqAuth_Inv "Serial Data 19 Protected : Actual Axle Torque Authenticated Invalid";
BA_ "SignalLongName" SG_ 52 PrplSysMtrASpdAuth "Serial Data 57 Protected : Propulsion System Motor A Speed Authenticated";
BA_ "SignalLongName" SG_ 52 TGI2P_TrnsOutShftAngVelAuth "Transmission General Information 2 Protected : Transmission Output Shaft Angular Velocity Authenticated";
BA_ "SignalType" SG_ 52 PrplSysMtrASpdAuth_Inv "ENM";
BA_ "SignalLongName" SG_ 52 PrplSysMtrASpdAuth_Inv "Serial Data 57 Protected : Propulsion System Motor A Speed Authenticated Invalid";
BA_ "SignalLongName" SG_ 52 EGIP_EngActlStdyStatTrqAuth "Serial Data 18 Protected : Engine Actual Steady State Torque Authenticated";
BA_ "SignalType" SG_ 52 TGI2P_TrnsOutShftAngVelAuth_Inv "ENM";
BA_ "SignalLongName" SG_ 52 TGI2P_TrnsOutShftAngVelAuth_Inv "Transmission General Information 2 Protected : Transmission Output Shaft Angular Velocity Authenticated Invalid";
BA_ "SignalType" SG_ 52 EGIP_EngActlStdyStatTrqAuth_Inv "ENM";
BA_ "SignalLongName" SG_ 52 EGIP_EngActlStdyStatTrqAuth_Inv "Serial Data 18 Protected : Engine Actual Steady State Torque Authenticated Invalid";
BA_ "SignalLongName" SG_ 99 ElecMtrATrqAchvd "Propulsion System Motor A Torque Achieved";
BA_ "SignalLongName" SG_ 99 ESP_EngSpdAuth "Serial Data 18 Protected : Engine Speed Authenticated";
BA_ "SignalLongName" SG_ 99 HstVehFrtRdWhlAng "Host Vehicle Path Parameters Protected : Host Vehicle Front Road Wheel Angle";
BA_ "SignalType" SG_ 99 HstVehFrtRdWhlAng_Inv "ENM";
BA_ "SignalLongName" SG_ 99 HstVehFrtRdWhlAng_Inv "Host Vehicle Path Parameters Protected : Host Vehicle Front Road Wheel Angle Invalid";
BA_ "SignalType" SG_ 99 ESP_EngSpdStAuth "ENM";
BA_ "SignalLongName" SG_ 99 ESP_EngSpdStAuth "Serial Data 18 Protected : Engine Speed State Authenticated";
BA_ "SignalLongName" SG_ 43 PBP_PTSndBrkPdlPsAuth "Serial Data 19 Protected : Powertrain Sensed Brake Pedal Position Authenticated";
BA_ "SignalType" SG_ 43 DslGlwPlgIO "ENM";
BA_ "SignalLongName" SG_ 43 DslGlwPlgIO "Diesel Glow Plug Indication On";
BA_ "SignalType" SG_ 43 TSP_TmpDrvrShfCtlActvAuth "ENM";
BA_ "SignalLongName" SG_ 43 TSP_TmpDrvrShfCtlActvAuth "Serial Data 30 Protected : Temporary Driver Shift Control Active Authenticated";
BA_ "SignalType" SG_ 43 TSP_ElecRngSeltnInDrvActvAuth "ENM";
BA_ "SignalLongName" SG_ 43 TSP_ElecRngSeltnInDrvActvAuth "Serial Data 30 Protected : Electronic Range Selection in Drive Active Authenticated";
BA_ "SignalType" SG_ 705 VMI1P_AccelActlPstnAuth_Inv "ENM";
BA_ "SignalLongName" SG_ 705 VMI1P_AccelActlPstnAuth_Inv "Serial Data 20 Protected : Accelerator Actual Position Authenticated Invalid";
BA_ "SignalLongName" SG_ 705 VMI1P_AccelActlPstnAuth "Serial Data 20 Protected : Accelerator Actual Position Authenticated";
BA_ "SignalLongName" SG_ 705 VMI1P_VehTopSpdLimArbdValAuth "Serial Data 20 Protected : Vehicle Top Speed Limit Arbitrated Value Authenticated";
BA_ "SignalLongName" SG_ 705 LIB1StatOfChrg "Lithium Ion Battery 1 State Of Charge";
BA_ "SignalType" SG_ 705 LIB1StatOfChrg_Inv "ENM";
BA_ "SignalLongName" SG_ 705 LIB1StatOfChrg_Inv "Lithium Ion Battery 1 State Of Charge Invalid";
BA_ "SignalType" SG_ 705 VMI1P_VehTopSpdLimModeActvAuth "ENM";
BA_ "SignalLongName" SG_ 705 VMI1P_VehTopSpdLimModeActvAuth "Serial Data 20 Protected : Vehicle Top Speed Limit Mode Active Authenticated";
BA_ "SignalType" SG_ 705 VMI1P_AccelPedOvrrdActvAuth "ENM";
BA_ "SignalLongName" SG_ 705 VMI1P_AccelPedOvrrdActvAuth "Serial Data 20 Protected : Accelerator Pedal Override Active Authenticated";
BA_ "SignalType" SG_ 705 LIB1CellVltgFlt "ENM";
BA_ "SignalLongName" SG_ 705 LIB1CellVltgFlt "Lithium Ion Battery 1 Cell Voltage Fault";
BA_ "SignalType" SG_ 705 LIB1CellVltgFlt_Inv "ENM";
BA_ "SignalLongName" SG_ 705 LIB1CellVltgFlt_Inv "Lithium Ion Battery 1 Cell Voltage Fault Invalid";
BA_ "SignalLongName" SG_ 204 RdLdNomAxlTrq "Road Load Nominal Axle Torque";
BA_ "SignalType" SG_ 1176 ClsnImntBrkgAxlTrqRqActvAuth "ENM";
BA_ "SignalLongName" SG_ 1176 ClsnImntBrkgAxlTrqRqActvAuth "Serial Data 35 Protected : Collision Imminent Braking Axle Torque Request Active Authenticated";
BA_ "SignalType" SG_ 1176 ACCBRP_ReqActvAuth "ENM";
BA_ "SignalLongName" SG_ 1176 ACCBRP_ReqActvAuth "Serial Data 35 Protected : Adaptive Cruise Control Braking Request Active Authenticated";
BA_ "SignalType" SG_ 1176 ACCBRP_ACCActvAuth "ENM";
BA_ "SignalLongName" SG_ 1176 ACCBRP_ACCActvAuth "Serial Data 35 Protected : Adaptive Cruise Control Active Authenticated";
BA_ "SignalType" SG_ 1176 ACCATRIP_TrqActvAuth "ENM";
BA_ "SignalLongName" SG_ 1176 ACCATRIP_TrqActvAuth "Serial Data 35 Protected : Torque Active Authenticated";
BA_ "SignalType" SG_ 1176 DMSIP_DrvrAttnStatAuth_Inv "ENM";
BA_ "SignalLongName" SG_ 1176 DMSIP_DrvrAttnStatAuth_Inv "Driver Monitoring System Information Protected : Driver Attention State Authenticated Invalid";
BA_ "SignalType" SG_ 1176 PrkAsstCustSeltn "ENM";
BA_ "SignalLongName" SG_ 1176 PrkAsstCustSeltn "Park Assist Customer Selection";
BA_ "SignalType" SG_ 1176 DMSIP_DrvrAttnStatAuth "ENM";
BA_ "SignalLongName" SG_ 1176 DMSIP_DrvrAttnStatAuth "Driver Monitoring System Information Protected : Driver Attention State Authenticated";
BA_ "SignalType" SG_ 1176 LCCPIP_LnCntrCtlAclPedLimRqAuth "ENM";
BA_ "SignalLongName" SG_ 1176 LCCPIP_LnCntrCtlAclPedLimRqAuth "Serial Data 35 Protected : Lane Centering Control Accel Pedal Limiting Requested Authenticated";
BA_ "SignalType" SG_ 701 AAASSRP_StrgReqStsAuth "ENM";
BA_ "SignalLongName" SG_ 701 AAASSRP_StrgReqStsAuth "Arbitrated ASIL Active Safety Steering Request Protected : Steering Request Status Authenticated";
BA_ "SignalType" SG_ 701 BGI1P_DrvrDrOpnStsAuth_Inv "ENM";
BA_ "SignalLongName" SG_ 701 BGI1P_DrvrDrOpnStsAuth_Inv "Serial Data 2 Protected : Driver Door Open Status Authenticated Invalid";
BA_ "SignalType" SG_ 701 BGI1P_DrvrDrOpnStsAuth_DuD "ENM";
BA_ "SignalLongName" SG_ 701 BGI1P_DrvrDrOpnStsAuth_DuD "Serial Data 2 Protected : Driver Door Open Status Authenticated Don't Use Data";
BA_ "SignalType" SG_ 701 BGI1P_DrvrDrOpnStsAuth "ENM";
BA_ "SignalLongName" SG_ 701 BGI1P_DrvrDrOpnStsAuth "Serial Data 2 Protected : Driver Door Open Status Authenticated";
BA_ "SignalType" SG_ 701 EngCyldrDctvRqd "ENM";
BA_ "SignalLongName" SG_ 701 EngCyldrDctvRqd "Engine Cylinder Deactivation Requested";
BA_ "SignalType" SG_ 701 EngCylDctvMd "ENM";
BA_ "SignalLongName" SG_ 701 EngCylDctvMd "Engine Cylinder Deactivation Mode";
BA_ "SignalType" SG_ 701 BGI1P_OutsdAmbtLgtLvlStsAuth "ENM";
BA_ "SignalLongName" SG_ 701 BGI1P_OutsdAmbtLgtLvlStsAuth "Serial Data 2 Protected : Outside Ambient Light Level Status Authenticated";
BA_ "SignalLongName" SG_ 115 SWIP_StrgWhlAngAuth "Steering Wheel Information Protected : Steering Wheel Angle Authenticated";
BA_ "SignalType" SG_ 115 SWIP_StrgWhlAngAuth_DuD "ENM";
BA_ "SignalLongName" SG_ 115 SWIP_StrgWhlAngAuth_DuD "Steering Wheel Information Protected : Steering Wheel Angle Authenticated Don't Use Data";
BA_ "SignalLongName" SG_ 115 SWIP_StrgWhlAngGradAuth "Steering Wheel Information Protected : Steering Wheel Angle Gradient Authenticated";
BA_ "SignalType" SG_ 115 SWIP_StrgWhlAngCalStsAuth "ENM";
BA_ "SignalLongName" SG_ 115 SWIP_StrgWhlAngCalStsAuth "Steering Wheel Information Protected : Steering Wheel Angle Calibration Status Authenticated";
BA_ "SignalType" SG_ 115 SWIP_StrgWhlAngAuth_Inv "ENM";
BA_ "SignalLongName" SG_ 115 SWIP_StrgWhlAngAuth_Inv "Steering Wheel Information Protected : Steering Wheel Angle Authenticated Invalid";
BA_ "SignalType" SG_ 115 ElecPSTrqOvrlySts "ENM";
BA_ "SignalLongName" SG_ 115 ElecPSTrqOvrlySts "Electronic Power Steering Torque Overlay Status";
BA_ "SignalType" SG_ 928 ADASAutoRsmChmEvntStat "ENM";
BA_ "SignalLongName" SG_ 928 ADASAutoRsmChmEvntStat "Advanced Driver Assist Systems Auto Resume Chime Event State";
BA_ "SignalType" SG_ 928 StBltRmndrChmTyp2EvntStat "ENM";
BA_ "SignalLongName" SG_ 928 StBltRmndrChmTyp2EvntStat "Seat Belt Reminder Chime Type 2 Event State";
BA_ "SignalType" SG_ 928 StBltRmndrChmEvntStat "ENM";
BA_ "SignalLongName" SG_ 928 StBltRmndrChmEvntStat "Seat Belt Reminder Chime Event State";
BA_ "SignalType" SG_ 928 BCMGI2_DrvrShtlModeCmnd "ENM";
BA_ "SignalLongName" SG_ 928 BCMGI2_DrvrShtlModeCmnd "Serial Data 9 : Driver Shuttle Mode Commanded";
BA_ "SignalType" SG_ 703 BVSCRP_CPSAxlTrqCmdReqStsAuth "ENM";
BA_ "SignalLongName" SG_ 703 BVSCRP_CPSAxlTrqCmdReqStsAuth "Serial Data 21 Protected : Collision Preparation System Axle Torque Command Request Status Authenticated";
BA_ "SignalType" SG_ 703 BVSCRP_CPSAxlTrqCmdLimStsAuth "ENM";
BA_ "SignalLongName" SG_ 703 BVSCRP_CPSAxlTrqCmdLimStsAuth "Serial Data 21 Protected : Collision Preparation System Axle Torque Command Limiting Status Authenticated";
BA_ "SignalType" SG_ 703 BVSCRP_ACCAxlTrqCmdReqStsAuth "ENM";
BA_ "SignalLongName" SG_ 703 BVSCRP_ACCAxlTrqCmdReqStsAuth "Serial Data 21 Protected : Adaptive Cruise Control Axle Torque Command Request Status Authenticated";
BA_ "SignalType" SG_ 703 BVSCRP_ACCAxlTrqCmdLimStsAuth "ENM";
BA_ "SignalLongName" SG_ 703 BVSCRP_ACCAxlTrqCmdLimStsAuth "Serial Data 21 Protected : Adaptive Cruise Control Axle Torque Command Limiting Status Authenticated";
BA_ "SignalLongName" SG_ 703 BVSCRP_CltchPdlActPosAuth "Serial Data 21 Protected : Clutch Pedal Actual Position Authenticated";
BA_ "SignalType" SG_ 703 CruzCtlActvAuth "ENM";
BA_ "SignalLongName" SG_ 703 CruzCtlActvAuth "Serial Data 21 Protected : Cruise Control Active Authenticated";
BA_ "SignalType" SG_ 703 CnvntlCruzCtlIndReqAuth "ENM";
BA_ "SignalLongName" SG_ 703 CnvntlCruzCtlIndReqAuth "Serial Data 21 Protected : Conventional Cruise Control Indication Request Authenticated";
BA_ "SignalType" SG_ 703 BVSCRP_CruzCtlEnbldAuth "ENM";
BA_ "SignalLongName" SG_ 703 BVSCRP_CruzCtlEnbldAuth "Serial Data 21 Protected : Cruise Control Enabled Authenticated";
BA_ "SignalType" SG_ 703 BVSCRP_CltchPdlActPosAuth_Inv "ENM";
BA_ "SignalLongName" SG_ 703 BVSCRP_CltchPdlActPosAuth_Inv "Serial Data 21 Protected : Clutch Pedal Actual Position Authenticated Invalid";
BA_ "SignalLongName" SG_ 703 CruzSpdLmtrDrvrSeltdSpdAuth "Serial Data 21 Protected : Cruise and Speed Limiter Driver Selected Speed Authenticated";
BA_ "SignalType" SG_ 703 DrSeltdSpdLmtrSetSpdLimRchdAuth "ENM";
BA_ "SignalLongName" SG_ 703 DrSeltdSpdLmtrSetSpdLimRchdAuth "Serial Data 21 Protected : Driver Selected Speed Limiter Set Speed Limit Reached Authenticated";
BA_ "SignalType" SG_ 703 DrSeltdSpdLmtrAutoMdSpLmStsAuth "ENM";
BA_ "SignalLongName" SG_ 703 DrSeltdSpdLmtrAutoMdSpLmStsAuth "Serial Data 21 Protected : Driver Selected Speed Limiter Auto Mode Speed Limit Status Authenticated";
BA_ "SignalLongName" SG_ 703 SpdLmtrSpdLimSgnValAuth "Serial Data 21 Protected : Speed Limiter Speed Limit Sign Value Authenticated";
BA_ "SignalType" SG_ 703 SpdLmtrSpdLimSgnUntAuth "ENM";
BA_ "SignalLongName" SG_ 703 SpdLmtrSpdLimSgnUntAuth "Serial Data 21 Protected : Speed Limiter Speed Limit Sign Unit Authenticated";
BA_ "SignalType" SG_ 703 PABRP_VehTopSpdLimArbdStatAuth "ENM";
BA_ "SignalLongName" SG_ 703 PABRP_VehTopSpdLimArbdStatAuth "Serial Data 21 Protected : Vehicle Top Speed Limit Arbitrated State Authenticated";
BA_ "SignalType" SG_ 703 EGI2P_PwrtrnCrnkActvAuth "ENM";
BA_ "SignalLongName" SG_ 703 EGI2P_PwrtrnCrnkActvAuth "Serial Data 21 Protected : Powertrain Crank Active Authenticated";
BA_ "SignalType" SG_ 703 DrSeltdSpdLmtrSetTypActvAuth "ENM";
BA_ "SignalLongName" SG_ 703 DrSeltdSpdLmtrSetTypActvAuth "Serial Data 21 Protected : Driver Selected Speed Limiter Setting Type Active Authenticated";
BA_ "SignalType" SG_ 703 BrkPdlDrvAppPrsDetcdAuth "ENM";
BA_ "SignalLongName" SG_ 703 BrkPdlDrvAppPrsDetcdAuth "Brake System Information Status 2 Protected : Brake Pedal Driver Applied Pressure Detected Authenticated";
BA_ "SignalType" SG_ 703 BrkPdlDrvAppPrsDetcdAuth_Inv "ENM";
BA_ "SignalLongName" SG_ 703 BrkPdlDrvAppPrsDetcdAuth_Inv "Brake System Information Status 2 Protected : Brake Pedal Driver Applied Pressure Detected Authenticated Invalid";
BA_ "SignalType" SG_ 703 Bat12VCfg "ENM";
BA_ "SignalLongName" SG_ 703 Bat12VCfg "IBS 12V Battery Voltage Information : Battery 12V Configuration";
BA_ "SignalType" SG_ 703 ETRPP_ElcTransRngPriAuth "ENM";
BA_ "SignalLongName" SG_ 703 ETRPP_ElcTransRngPriAuth "Serial Data 26 Protected : Electronic Transmission Range Primary Authenticated";
BA_ "SignalType" SG_ 703 BSIS2P_ABSFldAuth "ENM";
BA_ "SignalLongName" SG_ 703 BSIS2P_ABSFldAuth "Brake System Information Status 2 Protected : Antilock Brake System Failed Authenticated";
BA_ "SignalType" SG_ 703 BSIS2P_ABSAtvAuth "ENM";
BA_ "SignalLongName" SG_ 703 BSIS2P_ABSAtvAuth "Brake System Information Status 2 Protected : Antilock Brake System Active Authenticated";
BA_ "SignalLongName" SG_ 704 BSIS2P_BrkPdlDrvApplPresAuth "Brake System Information Status 2 Protected : Brake Pedal Driver Applied Pressure Authenticated";
BA_ "SignalType" SG_ 704 BSIS2P_BrkPdlDrvApplPresAuth_Inv "ENM";
BA_ "SignalLongName" SG_ 704 BSIS2P_BrkPdlDrvApplPresAuth_Inv "Brake System Information Status 2 Protected : Brake Pedal Driver Applied Pressure Authenticated Invalid";
BA_ "SignalLongName" SG_ 932 BVSCP_BdyCtlTopSpdLimReqValAuth "Serial Data 3 Protected : Body Control Top Speed Limit Request Value Authenticated";
BA_ "SignalLongName" SG_ 932 CTGI1P_CnvtTpSpLimRqValAuth "Serial Data 43 Protected : Convertible Top Speed Limit Request Value Authenticated";
BA_ "SignalType" SG_ 932 BdyCtlTopSpdLimSrcAuth "ENM";
BA_ "SignalLongName" SG_ 932 BdyCtlTopSpdLimSrcAuth "Serial Data 3 Protected : Body Control Top Speed Limit Source Authenticated";
BA_ "SignalType" SG_ 932 BdyCtlTopSpdLimIndOnAuth "ENM";
BA_ "SignalLongName" SG_ 932 BdyCtlTopSpdLimIndOnAuth "Serial Data 3 Protected : Body Control Top Speed Limit Indication On Authenticated";
BA_ "SignalType" SG_ 932 BdyCtlAccelLimIndOnAuth "ENM";
BA_ "SignalLongName" SG_ 932 BdyCtlAccelLimIndOnAuth "Serial Data 3 Protected : Body Control Acceleration Limit Indication On Authenticated";
BA_ "SignalLongName" SG_ 932 DeadFrntSwtchIllumLvl "Dead Front Switch Illumination Level";
BA_ "SignalType" SG_ 932 CnvtTopModSpdLimIndOnAuth "ENM";
BA_ "SignalLongName" SG_ 932 CnvtTopModSpdLimIndOnAuth "Serial Data 43 Protected : Convertible Top Module Speed Limit Indication On Authenticated";
BA_ "SignalLongName" SG_ 932 IntDimDspLvl "Interior Dimming Display Level";
BA_ "SignalLongName" SG_ 932 IntDimLvl "Interior Dimming Backlighting Level";
BA_ "SignalType" SG_ 932 DrvShftCntrlTrgtGr "ENM";
BA_ "SignalLongName" SG_ 932 DrvShftCntrlTrgtGr "Transmission Information 1 : Driver Shift Control Target Gear";
BA_ "SignalType" SG_ 932 DrvShftCntrlReqDndIO "ENM";
BA_ "SignalLongName" SG_ 932 DrvShftCntrlReqDndIO "Transmission Information 1 : Driver Shift Control Request Denied Indication On";
BA_ "SignalType" SG_ 932 TEGP_TrnsShftLvrPstnAuth_Inv "ENM";
BA_ "SignalLongName" SG_ 932 TEGP_TrnsShftLvrPstnAuth_Inv "Transmission Estimated Gear Protected : Transmission Shift Lever Position Authenticated Invalid";
BA_ "SignalType" SG_ 932 TEGP_TrnsEstGrAuth "ENM";
BA_ "SignalLongName" SG_ 932 TEGP_TrnsEstGrAuth "Transmission Estimated Gear Protected : Transmission Estimated Gear Authenticated";
BA_ "SignalType" SG_ 932 TEGP_TrnsEstGrAuth_Inv "ENM";
BA_ "SignalLongName" SG_ 932 TEGP_TrnsEstGrAuth_Inv "Transmission Estimated Gear Protected : Transmission Estimated Gear Authenticated Invalid";
BA_ "SignalType" SG_ 932 TrnsTUTDMdSt "ENM";
BA_ "SignalLongName" SG_ 932 TrnsTUTDMdSt "Transmission Information 1 : Transmission Tap Up/Tap Down Mode State";
BA_ "SignalType" SG_ 932 TEGP_TransCmndGrAuth "ENM";
BA_ "SignalLongName" SG_ 932 TEGP_TransCmndGrAuth "Transmission Estimated Gear Protected : Transmission Commanded Gear Authenticated";
BA_ "SignalType" SG_ 932 TEGP_TrnsShftLvrPstnAuth "ENM";
BA_ "SignalLongName" SG_ 932 TEGP_TrnsShftLvrPstnAuth "Transmission Estimated Gear Protected : Transmission Shift Lever Position Authenticated";
BA_ "SignalType" SG_ 933 TrnsRngInhbtSt "ENM";
BA_ "SignalLongName" SG_ 933 TrnsRngInhbtSt "Transmission Range Inhibit State";
BA_ "SignalType" SG_ 933 TEGP_TrnsEngdStAuth "ENM";
BA_ "SignalLongName" SG_ 933 TEGP_TrnsEngdStAuth "Transmission Estimated Gear Protected : Transmission Engaged State Authenticated";
BA_ "SignalType" SG_ 933 TEGP_TrnsEngdStAuth_Inv "ENM";
BA_ "SignalLongName" SG_ 933 TEGP_TrnsEngdStAuth_Inv "Transmission Estimated Gear Protected : Transmission Engaged State Authenticated Invalid";
BA_ "SignalType" SG_ 933 HiVltgBatOutOfEngyIndReq "ENM";
BA_ "SignalLongName" SG_ 933 HiVltgBatOutOfEngyIndReq "High Voltage Battery Out Of Energy Indication Request";
BA_ "SignalType" SG_ 933 DrvrElecVehModeCmnd "ENM";
BA_ "SignalLongName" SG_ 933 DrvrElecVehModeCmnd "Driver Electric Vehicle Mode Commanded";
BA_ "SignalType" SG_ 933 EASSI_StrtStpSt "ENM";
BA_ "SignalLongName" SG_ 933 EASSI_StrtStpSt "Engine Auto Start Stop Information : Start Stop State";
BA_ "SignalLongName" SG_ 934 BSIR2P_BrkgSysVhTpSpLmValAuth "Serial Data 14 Protected : Braking System Vehicle Top Speed Limit Value Authenticated";
BA_ "SignalType" SG_ 934 BSISP_TCSDrvrIntntAuth "ENM";
BA_ "SignalLongName" SG_ 934 BSISP_TCSDrvrIntntAuth "Serial Data 14 Protected : Traction Control System Driver Intent Authenticated";
BA_ "SignalType" SG_ 934 BSISP_TCSActvAuth "ENM";
BA_ "SignalLongName" SG_ 934 BSISP_TCSActvAuth "Serial Data 14 Protected : Traction Control System Active Authenticated";
BA_ "SignalType" SG_ 934 BSISP_ETRSHydrlcBrkgStsAuth "ENM";
BA_ "SignalLongName" SG_ 934 BSISP_ETRSHydrlcBrkgStsAuth "Serial Data 14 Protected : ETRS Hydraulic Braking Status Authenticated";
BA_ "SignalType" SG_ 934 BSISP_ESCSysStsAuth "ENM";
BA_ "SignalLongName" SG_ 934 BSISP_ESCSysStsAuth "Serial Data 14 Protected : Electronic Stability Control System Status Authenticated";
BA_ "SignalType" SG_ 934 BSISP_ESCActvAuth "ENM";
BA_ "SignalLongName" SG_ 934 BSISP_ESCActvAuth "Serial Data 14 Protected : Electronic Stability Control Active Authenticated";
BA_ "SignalType" SG_ 934 HstVehTrlrDtd "ENM";
BA_ "SignalLongName" SG_ 934 HstVehTrlrDtd "Host Vehicle Trailer Detected";
BA_ "SignalType" SG_ 934 BrkgSysVehTopSpdLimIndOnAuth "ENM";
BA_ "SignalLongName" SG_ 934 BrkgSysVehTopSpdLimIndOnAuth "Serial Data 14 Protected : Braking System Vehicle Top Speed Limit Indication On Authenticated";
BA_ "SignalType" SG_ 934 BSISP_TCSFaildAuth "ENM";
BA_ "SignalLongName" SG_ 934 BSISP_TCSFaildAuth "Serial Data 14 Protected : Traction Control System Failed Authenticated";
BA_ "SignalLongName" SG_ 718 HVBSOC_BatSOC "High Voltage Battery State of Charge : Battery State of Charge";
BA_ "SignalLongName" SG_ 718 HVBI_BatPackPrcdVltg "High Voltage Battery Information : Battery Pack Processed Voltage";
BA_ "SignalType" SG_ 718 HVBSOC_BatSOC_Inv "ENM";
BA_ "SignalLongName" SG_ 718 HVBSOC_BatSOC_Inv "High Voltage Battery State of Charge : Battery State of Charge Invalid";
BA_ "SignalType" SG_ 718 HVBI_BatPackPrcdVltg_DuD "ENM";
BA_ "SignalLongName" SG_ 718 HVBI_BatPackPrcdVltg_DuD "High Voltage Battery Information : Battery Pack Processed Voltage Don't Use Data";
BA_ "SignalLongName" SG_ 718 PrplDispEngTrq "Propulsion Display Engine Torque";
BA_ "SignalType" SG_ 718 HVBI_BatPackPrcdVltg_Inv "ENM";
BA_ "SignalLongName" SG_ 718 HVBI_BatPackPrcdVltg_Inv "High Voltage Battery Information : Battery Pack Processed Voltage Invalid";
BA_ "SignalType" SG_ 718 VAP_ActlVehAccelAuth_Inv "ENM";
BA_ "SignalLongName" SG_ 718 VAP_ActlVehAccelAuth_Inv "EBCM General Information 2 Protected : Actual Vehicle Acceleration Authenticated Invalid";
BA_ "SignalType" SG_ 718 PrplDispEngTrq_Inv "ENM";
BA_ "SignalLongName" SG_ 718 PrplDispEngTrq_Inv "Propulsion Display Engine Torque Invalid";
BA_ "SignalType" SG_ 718 PrplDispEngTrq_DuD "ENM";
BA_ "SignalLongName" SG_ 718 PrplDispEngTrq_DuD "Propulsion Display Engine Torque Don't Use Data";
BA_ "SignalLongName" SG_ 718 VAP_ActlVehAccelAuth "EBCM General Information 2 Protected : Actual Vehicle Acceleration Authenticated";
BA_ "SignalType" SG_ 718 MemIdfrMemStorIndReq "ENM";
BA_ "SignalLongName" SG_ 718 MemIdfrMemStorIndReq "Memory Identifier Memory Store Indication Request";
BA_ "SignalLongName" SG_ 681 PrplDispTotTrq "Propulsion Display Total Torque";
BA_ "SignalLongName" SG_ 681 EngBstPrsInd "Engine Boost Pressure Indication";
BA_ "SignalType" SG_ 681 EngBstPrsInd_Inv "ENM";
BA_ "SignalLongName" SG_ 681 EngBstPrsInd_Inv "Engine Boost Pressure Indication Invalid";
BA_ "SignalLongName" SG_ 681 ThrPstn "Throttle Position";
BA_ "SignalType" SG_ 681 ThrPstn_Inv "ENM";
BA_ "SignalLongName" SG_ 681 ThrPstn_Inv "Throttle Position Invalid";
BA_ "SignalLongName" SG_ 681 EngPrplDispTrqLvlPct "Engine Propulsion Display Torque Level Percent";
BA_ "SignalType" SG_ 681 EngPrplDispTrqLvlPct_DuD "ENM";
BA_ "SignalLongName" SG_ 681 EngPrplDispTrqLvlPct_DuD "Engine Propulsion Display Torque Level Percent Don't Use Data";
BA_ "SignalLongName" SG_ 681 RegenPwrLimdDispPct "Regenerative Power Limited Display Percent";
BA_ "SignalLongName" SG_ 681 TrlrBrkgFOut "Trailer Braking Force Output";
BA_ "SignalType" SG_ 681 TrnsTrqCnvCltCmdMd "ENM";
BA_ "SignalLongName" SG_ 681 TrnsTrqCnvCltCmdMd "Transmission Torque Converter Clutch Commanded Mode";
BA_ "SignalType" SG_ 681 PrkLmpsAct "ENM";
BA_ "SignalLongName" SG_ 681 PrkLmpsAct "Park Lamps Active";
BA_ "SignalType" SG_ 681 WRDSP_LRAuth "ENM";
BA_ "SignalLongName" SG_ 681 WRDSP_LRAuth "EBCM General Information 2 Protected : Wheel Rotational Directional Status Left Rear Authenticated";
BA_ "SignalType" SG_ 681 WRDSP_LFAuth "ENM";
BA_ "SignalLongName" SG_ 681 WRDSP_LFAuth "EBCM General Information 2 Protected : Wheel Rotational Directional Status Left Front Authenticated";
BA_ "SignalLongName" SG_ 719 VSANDP_VehSpdAvgNDrvnAuth "Vehicle Speed Average Non Driven Protected : Vehicle Speed Average NonDriven Authenticated";
BA_ "SignalType" SG_ 719 WRDSP_RRAuth "ENM";
BA_ "SignalLongName" SG_ 719 WRDSP_RRAuth "EBCM General Information 2 Protected : Wheel Rotational Directional Status Right Rear Authenticated";
BA_ "SignalType" SG_ 719 WRDSP_RFAuth "ENM";
BA_ "SignalLongName" SG_ 719 WRDSP_RFAuth "EBCM General Information 2 Protected : Wheel Rotational Directional Status Right Front Authenticated";
BA_ "SignalLongName" SG_ 719 DRCDNDP_DRCAvgDrvnAuth "Serial Data 19 Protected : Distance Rolling Count Average Driven Authenticated";
BA_ "SignalType" SG_ 719 VSANDP_VehSpdAvgNDrvnAuth_Inv "ENM";
BA_ "SignalLongName" SG_ 719 VSANDP_VehSpdAvgNDrvnAuth_Inv "Vehicle Speed Average Non Driven Protected : Vehicle Speed Average Non Driven Authenticated Invalid";
BA_ "SignalLongName" SG_ 719 DRCDNDP_DRCAvgNonDrvnAuth "Serial Data 19 Protected : Distance Rolling Count Average Non Driven Authenticated";
BA_ "SignalType" SG_ 719 DRCDNDP_DRCAvgDrvnSrcAuth "ENM";
BA_ "SignalLongName" SG_ 719 DRCDNDP_DRCAvgDrvnSrcAuth "Serial Data 19 Protected : Distance Rolling Count Average Driven Source Authenticated";
BA_ "SignalType" SG_ 719 DRCDNDP_DRCAvgDrvnRstOccAuth "ENM";
BA_ "SignalLongName" SG_ 719 DRCDNDP_DRCAvgDrvnRstOccAuth "Serial Data 19 Protected : Distance Rolling Count Average Driven Reset Occurred Authenticated";
BA_ "SignalType" SG_ 719 DRCDNDP_DRCAvgDrvnAuth_Inv "ENM";
BA_ "SignalLongName" SG_ 719 DRCDNDP_DRCAvgDrvnAuth_Inv "Serial Data 19 Protected : Distance Rolling Count Average Driven Authenticated Invalid";
BA_ "SignalLongName" SG_ 719 SSID1P_LatAccelAuth "Serial Data 44 Protected : Lateral Acceleration Authenticated";
BA_ "SignalType" SG_ 719 SSID1P_LatAccelAuth_Inv "ENM";
BA_ "SignalLongName" SG_ 719 SSID1P_LatAccelAuth_Inv "Serial Data 44 Protected : Lateral Acceleration Authenticated Invalid";
BA_ "SignalType" SG_ 719 DRCDNDP_DRCAvgNonDrvnRstOccAuth "ENM";
BA_ "SignalLongName" SG_ 719 DRCDNDP_DRCAvgNonDrvnRstOccAuth "Serial Data 19 Protected : Distance Rolling Count Average Non Driven Reset Occurred Authenticated";
BA_ "SignalType" SG_ 719 DRCDNDP_DRCAvgNonDrvnAuth_Inv "ENM";
BA_ "SignalLongName" SG_ 719 DRCDNDP_DRCAvgNonDrvnAuth_Inv "Serial Data 19 Protected : Distance Rolling Count Average Non Driven Authenticated Invalid";
BA_ "SignalType" SG_ 936 RdWhlAng_Inv "ENM";
BA_ "SignalLongName" SG_ 936 RdWhlAng_Inv "Off Road Display Information : Road Wheel Angle Invalid";
BA_ "SignalLongName" SG_ 936 RdWhlAng "Off Road Display Information : Road Wheel Angle";
BA_ "SignalType" SG_ 936 VehPtchAng_Inv "ENM";
BA_ "SignalLongName" SG_ 936 VehPtchAng_Inv "Off Road Display Information : Vehicle Pitch Angle Invalid";
BA_ "SignalLongName" SG_ 936 VehPtchAng "Off Road Display Information : Vehicle Pitch Angle";
BA_ "SignalType" SG_ 936 VehRollAng_Inv "ENM";
BA_ "SignalLongName" SG_ 936 VehRollAng_Inv "Off Road Display Information : Vehicle Roll Angle Invalid";
BA_ "SignalLongName" SG_ 936 VehRollAng "Off Road Display Information : Vehicle Roll Angle";
BA_ "SignalType" SG_ 937 AFLHiBmsOtgIndOn "ENM";
BA_ "SignalLongName" SG_ 937 AFLHiBmsOtgIndOn "Adaptive Forward Lighting High Beams Outage Indication On";
BA_ "SignalType" SG_ 937 AFLCkLoBmsIndOn "ENM";
BA_ "SignalLongName" SG_ 937 AFLCkLoBmsIndOn "Adaptive Forward Lighting Check Low Beams Indication On";
BA_ "SignalLongName" SG_ 938 EngOilPrs "Engine Oil Pressure";
BA_ "SignalType" SG_ 938 EngOilPrs_Inv "ENM";
BA_ "SignalLongName" SG_ 938 EngOilPrs_Inv "Engine Oil Pressure Invalid";
BA_ "SignalLongName" SG_ 938 GenFldDutCyc "Generator Field Duty Cycle";
BA_ "SignalType" SG_ 1407 APACR_SptFndChmEvntStat "ENM";
BA_ "SignalLongName" SG_ 1407 APACR_SptFndChmEvntStat "Advanced Park Assist Chime Requests : Advanced Park Assist Spot Found Chime Event State";
BA_ "SignalType" SG_ 1407 APACR_FaildChmEvntStat "ENM";
BA_ "SignalLongName" SG_ 1407 APACR_FaildChmEvntStat "Advanced Park Assist Chime Requests : Advanced Park Assist Failed Chime Event State";
BA_ "SignalType" SG_ 1407 APACR_CncldChmEvntStat "ENM";
BA_ "SignalLongName" SG_ 1407 APACR_CncldChmEvntStat "Advanced Park Assist Chime Requests : Advanced Park Assist Canceled Chime Event State";
BA_ "SignalType" SG_ 1407 APACR_CmpltChmEvntStat "ENM";
BA_ "SignalLongName" SG_ 1407 APACR_CmpltChmEvntStat "Advanced Park Assist Chime Requests : Advanced Park Assist Complete Chime Event State";
BA_ "SignalLongName" SG_ 1407 TrnsOilRmnLf "Transmission Oil Remaining Life";
BA_ "SignalType" SG_ 1407 APACR_StopChmEvntStat "ENM";
BA_ "SignalLongName" SG_ 1407 APACR_StopChmEvntStat "Advanced Park Assist Chime Requests : Advanced Park Assist Stop Chime Event State";
BA_ "SignalLongName" SG_ 1407 FCAIAHSR_HptcStReqPuls "Forward Collision Alert Imminent Haptic Seat Request : Haptic Seat Request Pulses";
BA_ "SignalType" SG_ 1407 ELWWIP_WprFrtFtrReqAuth "ENM";
BA_ "SignalLongName" SG_ 1407 ELWWIP_WprFrtFtrReqAuth "Exterior Lighting and Wash Wiper Information Protected : Wiper Front Feature Request Authenticated";
BA_ "SignalType" SG_ 1407 LnCntrWrnIndRqst "ENM";
BA_ "SignalLongName" SG_ 1407 LnCntrWrnIndRqst "Lane Centering Warning Indication Request";
BA_ "SignalType" SG_ 1407 ELWWIP_BrkLmpLtCmdAuth "ENM";
BA_ "SignalLongName" SG_ 1407 ELWWIP_BrkLmpLtCmdAuth "Exterior Lighting and Wash Wiper Information Protected : Brake Lamp Left Command Authenticated";
BA_ "SignalLongName" SG_ 1407 TrlrConnCntr "Trailer Connection Counter";
BA_ "SignalType" SG_ 1407 LKALnMrkgIndLt "ENM";
BA_ "SignalLongName" SG_ 1407 LKALnMrkgIndLt "Lane Keep Assist Lane Marking Indication Left";
BA_ "SignalType" SG_ 1407 FrntPsSeatbeltStat "ENM";
BA_ "SignalLongName" SG_ 1407 FrntPsSeatbeltStat "Front Passenger Seat belt Status";
BA_ "SignalType" SG_ 1407 FrntPsSeatbeltStat_Inv "ENM";
BA_ "SignalLongName" SG_ 1407 FrntPsSeatbeltStat_Inv "Front Passenger Seat Belt Status Invalid";
BA_ "SignalType" SG_ 1407 ELWWIP_BrkLmpRtCmdAuth "ENM";
BA_ "SignalLongName" SG_ 1407 ELWWIP_BrkLmpRtCmdAuth "Exterior Lighting and Wash Wiper Information Protected : Brake Lamp Right Command Authenticated";
BA_ "SignalType" SG_ 1407 ORIP_DrvrStBltSts1Auth_Inv "ENM";
BA_ "SignalLongName" SG_ 1407 ORIP_DrvrStBltSts1Auth_Inv "Occupant Restraint Information Protected : Driver Seat Belt Status Authenticated Invalid";
BA_ "SignalType" SG_ 1407 LnDtWrnCntrlVsAlrtCmdGnc "ENM";
BA_ "SignalLongName" SG_ 1407 LnDtWrnCntrlVsAlrtCmdGnc "Lane Detection Warning and Control Visual Alert Command Generic";
BA_ "SignalType" SG_ 1407 LKALnMrkgIndRt "ENM";
BA_ "SignalLongName" SG_ 1407 LKALnMrkgIndRt "Lane Keep Assist Lane Marking Indication Right";
BA_ "SignalType" SG_ 1407 AdpLghtRspTypCstAvlFlg4 "ENM";
BA_ "SignalLongName" SG_ 1407 AdpLghtRspTypCstAvlFlg4 "Adaptive Lighting Response Type Customization Availability Flag4";
BA_ "SignalType" SG_ 1407 MltpPsStBtRmndrChmEvntStat "ENM";
BA_ "SignalLongName" SG_ 1407 MltpPsStBtRmndrChmEvntStat "Multiple Passenger Seat Belt Reminder Chime Event State";
BA_ "SignalType" SG_ 1407 RrPCMRspTypCstCrStVal "ENM";
BA_ "SignalLongName" SG_ 1407 RrPCMRspTypCstCrStVal "Rear Pedestrian Collision Mitigation Response Type Customization Current Setting Value";
BA_ "SignalType" SG_ 1407 ORIP_DrvrStBltSts1Auth "ENM";
BA_ "SignalLongName" SG_ 1407 ORIP_DrvrStBltSts1Auth "Occupant Restraint Information Protected : Driver Seat Belt Status Authenticated";
BA_ "SignalType" SG_ 1408 ElecPrkBrkCtnChiEveStat "ENM";
BA_ "SignalLongName" SG_ 1408 ElecPrkBrkCtnChiEveStat "Electric Park Brake Continuous Chime Event State";
BA_ "SignalType" SG_ 1408 ELWWIP_TrlrRvrsLmpsCmdAuth "ENM";
BA_ "SignalLongName" SG_ 1408 ELWWIP_TrlrRvrsLmpsCmdAuth "Exterior Lighting and Wash Wiper Information Protected : Trailer Reverse Lamps Command Authenticated";
BA_ "SignalType" SG_ 1408 ELWWIP_RvrsLmpCmdAuth "ENM";
BA_ "SignalLongName" SG_ 1408 ELWWIP_RvrsLmpCmdAuth "Exterior Lighting and Wash Wiper Information Protected : Reverse Lamp Command Authenticated";
BA_ "SignalType" SG_ 1408 ELWWIP_CHMSLCmdAuth "ENM";
BA_ "SignalLongName" SG_ 1408 ELWWIP_CHMSLCmdAuth "Exterior Lighting and Wash Wiper Information Protected : CHMSL Command Authenticated";
BA_ "SignalType" SG_ 1408 LDWCtrlHndOff1ChmEvntStat "ENM";
BA_ "SignalLongName" SG_ 1408 LDWCtrlHndOff1ChmEvntStat "Lane Detection Warning and Control Hands Off 1 Chime Event State";
BA_ "SignalType" SG_ 1408 FrwdCllsnAlrtImAlrtDrIntAlrtChmE "ENM";
BA_ "SignalLongName" SG_ 1408 FrwdCllsnAlrtImAlrtDrIntAlrtChmE "Forward Collision Alert Imminent Alert Driver Intervention Alert Chime Event State";
BA_ "SignalType" SG_ 1408 FrntPCMChmEvntStat "ENM";
BA_ "SignalLongName" SG_ 1408 FrntPCMChmEvntStat "Front Pedestrian Collision Mitigation Chime Event State";
BA_ "SignalType" SG_ 1408 ElecPrkBrkFixDurChiEveStat "ENM";
BA_ "SignalLongName" SG_ 1408 ElecPrkBrkFixDurChiEveStat "Electric Park Brake Fixed Duration Chime Event State";
BA_ "SignalType" SG_ 1408 LDWCtrlRtHndSdChmEvntStat "ENM";
BA_ "SignalLongName" SG_ 1408 LDWCtrlRtHndSdChmEvntStat "Lane Detection Warning and Control Right Hand Side Chime Event State";
BA_ "SignalType" SG_ 1408 LDWCtrlLtHndSdChmEvntStat "ENM";
BA_ "SignalLongName" SG_ 1408 LDWCtrlLtHndSdChmEvntStat "Lane Detection Warning and Control Left Hand Side Chime Event State";
BA_ "SignalType" SG_ 1408 LDWCtrlHndOff3ChmEvntStat "ENM";
BA_ "SignalLongName" SG_ 1408 LDWCtrlHndOff3ChmEvntStat "Lane Detection Warning and Control Hands Off 3 Chime Event State";
BA_ "SignalType" SG_ 1408 LDWCtrlHndOff2ChmEvntStat "ENM";
BA_ "SignalLongName" SG_ 1408 LDWCtrlHndOff2ChmEvntStat "Lane Detection Warning and Control Hands Off 2 Chime Event State";
BA_ "SignalType" SG_ 1408 MemStrDblBeepChmEvStRR "ENM";
BA_ "SignalLongName" SG_ 1408 MemStrDblBeepChmEvStRR "Memory Store Double Beep Chime Event State Right Rear";
BA_ "SignalType" SG_ 1408 MemStrDblBeepChmEvStLR "ENM";
BA_ "SignalLongName" SG_ 1408 MemStrDblBeepChmEvStLR "Memory Store Double Beep Chime Event State Left Rear";
BA_ "SignalType" SG_ 1408 MemStrDblBeepChmEvStDrv "ENM";
BA_ "SignalLongName" SG_ 1408 MemStrDblBeepChmEvStDrv "Memory Store Double Beep Chime Event State Driver";
BA_ "SignalType" SG_ 1408 MemStrDblBeepChmEvStCoDrv "ENM";
BA_ "SignalLongName" SG_ 1408 MemStrDblBeepChmEvStCoDrv "Memory Store Double Beep Chime Event State Co-Driver";
BA_ "SignalType" SG_ 1408 MemStrSnglBeepChmEvStRR "ENM";
BA_ "SignalLongName" SG_ 1408 MemStrSnglBeepChmEvStRR "Memory Store Single Beep Chime Event State Right Rear";
BA_ "SignalType" SG_ 1408 MemStrSnglBeepChmEvStLR "ENM";
BA_ "SignalLongName" SG_ 1408 MemStrSnglBeepChmEvStLR "Memory Store Single Beep Chime Event State Left Rear";
BA_ "SignalType" SG_ 1408 MemStrSnglBeepChmEvStDrv "ENM";
BA_ "SignalLongName" SG_ 1408 MemStrSnglBeepChmEvStDrv "Memory Store Single Beep Chime Event State Driver";
BA_ "SignalType" SG_ 1408 MemStrSnglBeepChmEvStCoDrv "ENM";
BA_ "SignalLongName" SG_ 1408 MemStrSnglBeepChmEvStCoDrv "Memory Store Single Beep Chime Event State Co-Driver";
BA_ "SignalType" SG_ 1408 MemStrTrplBeepChmEvStRR "ENM";
BA_ "SignalLongName" SG_ 1408 MemStrTrplBeepChmEvStRR "Memory Store Triple Beep Chime Event State Right Rear";
BA_ "SignalType" SG_ 1408 MemStrTrplBeepChmEvStLR "ENM";
BA_ "SignalLongName" SG_ 1408 MemStrTrplBeepChmEvStLR "Memory Store Triple Beep Chime Event State Left Rear";
BA_ "SignalType" SG_ 1408 MemStrTrplBeepChmEvStDrv "ENM";
BA_ "SignalLongName" SG_ 1408 MemStrTrplBeepChmEvStDrv "Memory Store Triple Beep Chime Event State Driver";
BA_ "SignalType" SG_ 1408 MemStrTrplBeepChmEvStCoDrv "ENM";
BA_ "SignalLongName" SG_ 1408 MemStrTrplBeepChmEvStCoDrv "Memory Store Triple Beep Chime Event State Co-Driver";
BA_ "SignalType" SG_ 1408 PrkAsstFllFrZn2ChEvntSt "ENM";
BA_ "SignalLongName" SG_ 1408 PrkAsstFllFrZn2ChEvntSt "Park Assist Full Front Zone 2 Chime Event State";
BA_ "SignalType" SG_ 1408 PrkAsstFllFrZn1ChEvntSt "ENM";
BA_ "SignalLongName" SG_ 1408 PrkAsstFllFrZn1ChEvntSt "Park Assist Full Front Zone 1 Chime Event State";
BA_ "SignalType" SG_ 1408 PrkAsstFlChEvntSt "ENM";
BA_ "SignalLongName" SG_ 1408 PrkAsstFlChEvntSt "Park Assist Fail Chime Event State";
BA_ "SignalType" SG_ 1408 PAMutSts "ENM";
BA_ "SignalLongName" SG_ 1408 PAMutSts "Park Assist Mute Status";
BA_ "SignalType" SG_ 1408 PrkAsstFllFrZn6ChEvntSt "ENM";
BA_ "SignalLongName" SG_ 1408 PrkAsstFllFrZn6ChEvntSt "Park Assist Full Front Zone 6 Chime Event State";
BA_ "SignalType" SG_ 1408 PrkAsstFllFrZn5ChEvntSt "ENM";
BA_ "SignalLongName" SG_ 1408 PrkAsstFllFrZn5ChEvntSt "Park Assist Full Front Zone 5 Chime Event State";
BA_ "SignalType" SG_ 1408 PrkAsstFllFrZn4ChEvntSt "ENM";
BA_ "SignalLongName" SG_ 1408 PrkAsstFllFrZn4ChEvntSt "Park Assist Full Front Zone 4 Chime Event State";
BA_ "SignalType" SG_ 1408 PrkAsstFllFrZn3ChEvntSt "ENM";
BA_ "SignalLongName" SG_ 1408 PrkAsstFllFrZn3ChEvntSt "Park Assist Full Front Zone 3 Chime Event State";
BA_ "SignalType" SG_ 1409 PrkAsstFllRrZn4ChEvntSt "ENM";
BA_ "SignalLongName" SG_ 1409 PrkAsstFllRrZn4ChEvntSt "Park Assist Full Rear Zone 4 Chime Event State";
BA_ "SignalType" SG_ 1409 PrkAsstFllRrZn3ChEvntSt "ENM";
BA_ "SignalLongName" SG_ 1409 PrkAsstFllRrZn3ChEvntSt "Park Assist Full Rear Zone 3 Chime Event State";
BA_ "SignalType" SG_ 1409 PrkAsstFllRrZn2ChEvntSt "ENM";
BA_ "SignalLongName" SG_ 1409 PrkAsstFllRrZn2ChEvntSt "Park Assist Full Rear Zone 2 Chime Event State";
BA_ "SignalType" SG_ 1409 PrkAsstFllRrZn1ChEvntSt "ENM";
BA_ "SignalLongName" SG_ 1409 PrkAsstFllRrZn1ChEvntSt "Park Assist Full Rear Zone 1 Chime Event State";
BA_ "SignalType" SG_ 1409 PrkAsstFrLftSdZn1ChEvntSt "ENM";
BA_ "SignalLongName" SG_ 1409 PrkAsstFrLftSdZn1ChEvntSt "Park Assist Front Left Side Zone 1 Chime Event State";
BA_ "SignalType" SG_ 1409 PrkAsstFrFrstRprtChEvntSt "ENM";
BA_ "SignalLongName" SG_ 1409 PrkAsstFrFrstRprtChEvntSt "Park Assist Front First Report Chime Event State";
BA_ "SignalType" SG_ 1409 PrkAsstFllRrZn6ChEvntSt "ENM";
BA_ "SignalLongName" SG_ 1409 PrkAsstFllRrZn6ChEvntSt "Park Assist Full Rear Zone 6 Chime Event State";
BA_ "SignalType" SG_ 1409 PrkAsstFllRrZn5ChEvntSt "ENM";
BA_ "SignalLongName" SG_ 1409 PrkAsstFllRrZn5ChEvntSt "Park Assist Full Rear Zone 5 Chime Event State";
BA_ "SignalType" SG_ 1409 PrkAsstFrLftSdZn5ChEvntSt "ENM";
BA_ "SignalLongName" SG_ 1409 PrkAsstFrLftSdZn5ChEvntSt "Park Assist Front Left Side Zone 5 Chime Event State";
BA_ "SignalType" SG_ 1409 PrkAsstFrLftSdZn4ChEvntSt "ENM";
BA_ "SignalLongName" SG_ 1409 PrkAsstFrLftSdZn4ChEvntSt "Park Assist Front Left Side Zone 4 Chime Event State";
BA_ "SignalType" SG_ 1409 PrkAsstFrLftSdZn3ChEvntSt "ENM";
BA_ "SignalLongName" SG_ 1409 PrkAsstFrLftSdZn3ChEvntSt "Park Assist Front Left Side Zone 3 Chime Event State";
BA_ "SignalType" SG_ 1409 PrkAsstFrLftSdZn2ChEvntSt "ENM";
BA_ "SignalLongName" SG_ 1409 PrkAsstFrLftSdZn2ChEvntSt "Park Assist Front Left Side Zone 2 Chime Event State";
BA_ "SignalType" SG_ 1409 PrkAsstFrRghtSdZn3ChEvntSt "ENM";
BA_ "SignalLongName" SG_ 1409 PrkAsstFrRghtSdZn3ChEvntSt "Park Assist Front Right Side Zone 3 Chime Event State";
BA_ "SignalType" SG_ 1409 PrkAsstFrRghtSdZn2ChEvntSt "ENM";
BA_ "SignalLongName" SG_ 1409 PrkAsstFrRghtSdZn2ChEvntSt "Park Assist Front Right Side Zone 2 Chime Event State";
BA_ "SignalType" SG_ 1409 PrkAsstFrRghtSdZn1ChEvntSt "ENM";
BA_ "SignalLongName" SG_ 1409 PrkAsstFrRghtSdZn1ChEvntSt "Park Assist Front Right Side Zone 1 Chime Event State";
BA_ "SignalType" SG_ 1409 PrkAsstFrLftSdZn6ChEvntSt "ENM";
BA_ "SignalLongName" SG_ 1409 PrkAsstFrLftSdZn6ChEvntSt "Park Assist Front Left Side Zone 6 Chime Event State";
BA_ "SignalType" SG_ 1409 PrkAsstFrRgrChEvntSt "ENM";
BA_ "SignalLongName" SG_ 1409 PrkAsstFrRgrChEvntSt "Park Assist Front Roger Chime Event State";
BA_ "SignalType" SG_ 1409 PrkAsstFrRghtSdZn6ChEvntSt "ENM";
BA_ "SignalLongName" SG_ 1409 PrkAsstFrRghtSdZn6ChEvntSt "Park Assist Front Right Side Zone 6 Chime Event State";
BA_ "SignalType" SG_ 1409 PrkAsstFrRghtSdZn5ChEvntSt "ENM";
BA_ "SignalLongName" SG_ 1409 PrkAsstFrRghtSdZn5ChEvntSt "Park Assist Front Right SideZone 5 Chime Event State";
BA_ "SignalType" SG_ 1409 PrkAsstFrRghtSdZn4ChEvntSt "ENM";
BA_ "SignalLongName" SG_ 1409 PrkAsstFrRghtSdZn4ChEvntSt "Park Assist Front Right Side Zone 4 Chime Event State";
BA_ "SignalType" SG_ 1409 PrkAsstRrLftSdZn3ChEvntSt "ENM";
BA_ "SignalLongName" SG_ 1409 PrkAsstRrLftSdZn3ChEvntSt "Park Assist Rear Left Side Zone 3 Chime Event State";
BA_ "SignalType" SG_ 1409 PrkAsstRrLftSdZn2ChEvntSt "ENM";
BA_ "SignalLongName" SG_ 1409 PrkAsstRrLftSdZn2ChEvntSt "Park Assist Rear Left Side Zone 2 Chime Event State";
BA_ "SignalType" SG_ 1409 PrkAsstRrLftSdZn1ChEvntSt "ENM";
BA_ "SignalLongName" SG_ 1409 PrkAsstRrLftSdZn1ChEvntSt "Park Assist Rear Left Side Zone 1 Chime Event State";
BA_ "SignalType" SG_ 1409 PrkAsstRrFrstRprtChEvntSt "ENM";
BA_ "SignalLongName" SG_ 1409 PrkAsstRrFrstRprtChEvntSt "Park Assist Rear First Report Chime Event State";
BA_ "SignalType" SG_ 1409 PrkAsstRrRghtSdZn1ChEvntSt "ENM";
BA_ "SignalLongName" SG_ 1409 PrkAsstRrRghtSdZn1ChEvntSt "Park Assist Rear Right Side Zone 1 Chime Event State";
BA_ "SignalType" SG_ 1409 PrkAsstRrLftSdZn6ChEvntSt "ENM";
BA_ "SignalLongName" SG_ 1409 PrkAsstRrLftSdZn6ChEvntSt "Park Assist Rear Left Side Zone 6 Chime Event State";
BA_ "SignalType" SG_ 1409 PrkAsstRrLftSdZn5ChEvntSt "ENM";
BA_ "SignalLongName" SG_ 1409 PrkAsstRrLftSdZn5ChEvntSt "Park Assist Rear Left Side Zone 5 Chime Event State";
BA_ "SignalType" SG_ 1409 PrkAsstRrLftSdZn4ChEvntSt "ENM";
BA_ "SignalLongName" SG_ 1409 PrkAsstRrLftSdZn4ChEvntSt "Park Assist Rear Left Side Zone 4 Chime Event State";
BA_ "SignalType" SG_ 1409 PrkAsstRrRghtSdZn5ChEvntSt "ENM";
BA_ "SignalLongName" SG_ 1409 PrkAsstRrRghtSdZn5ChEvntSt "Park Assist Rear Right Side Zone 5 Chime Event State";
BA_ "SignalType" SG_ 1409 PrkAsstRrRghtSdZn4ChEvntSt "ENM";
BA_ "SignalLongName" SG_ 1409 PrkAsstRrRghtSdZn4ChEvntSt "Park Assist Rear Right Side Zone 4 Chime Event State";
BA_ "SignalType" SG_ 1409 PrkAsstRrRghtSdZn3ChEvntSt "ENM";
BA_ "SignalLongName" SG_ 1409 PrkAsstRrRghtSdZn3ChEvntSt "Park Assist Rear Right Side Zone 3 Chime Event State";
BA_ "SignalType" SG_ 1409 PrkAsstRrRghtSdZn2ChEvntSt "ENM";
BA_ "SignalLongName" SG_ 1409 PrkAsstRrRghtSdZn2ChEvntSt "Park Assist Rear Right Side Zone 2 Chime Event State";
BA_ "SignalType" SG_ 1410 PwrSdClsrLRObstclChmEvntStat "ENM";
BA_ "SignalLongName" SG_ 1410 PwrSdClsrLRObstclChmEvntStat "Power Side Closure Left Rear Obstacle Chime Event State";
BA_ "SignalType" SG_ 1410 PwrSdClsrLFObstclChmEvntStat "ENM";
BA_ "SignalLongName" SG_ 1410 PwrSdClsrLFObstclChmEvntStat "Power Side Closure Left Front Obstacle Chime Event State";
BA_ "SignalType" SG_ 1410 PrkAsstRrRgrChEvntSt "ENM";
BA_ "SignalLongName" SG_ 1410 PrkAsstRrRgrChEvntSt "Park Assist Rear Roger Chime Event State";
BA_ "SignalType" SG_ 1410 PrkAsstRrRghtSdZn6ChEvntSt "ENM";
BA_ "SignalLongName" SG_ 1410 PrkAsstRrRghtSdZn6ChEvntSt "Park Assist Rear Right Side Zone 6 Chime Event State";
BA_ "SignalType" SG_ 1410 PwrSdSldClsrLFRmtActChmEvntStat "ENM";
BA_ "SignalLongName" SG_ 1410 PwrSdSldClsrLFRmtActChmEvntStat "Power Side Sliding Closure Left Front Remote Activation Chime Event State";
BA_ "SignalType" SG_ 1410 PwrSdSldClsrLFLclActChmEvntStat "ENM";
BA_ "SignalLongName" SG_ 1410 PwrSdSldClsrLFLclActChmEvntStat "Power Side Sliding Closure Left Front Local Activation Chime Event State";
BA_ "SignalType" SG_ 1410 PwrSdClsrRRObstclChmEvntStat "ENM";
BA_ "SignalLongName" SG_ 1410 PwrSdClsrRRObstclChmEvntStat "Power Side Closure Right Rear Obstacle Chime Event State";
BA_ "SignalType" SG_ 1410 PwrSdClsrRFObstclChmEvntStat "ENM";
BA_ "SignalLongName" SG_ 1410 PwrSdClsrRFObstclChmEvntStat "Power Side Closure Right Front Obstacle Chime Event State";
BA_ "SignalType" SG_ 1410 PwrSdSldClsrRFRmtActChmEvntStat "ENM";
BA_ "SignalLongName" SG_ 1410 PwrSdSldClsrRFRmtActChmEvntStat "Power Side Sliding Closure Right Front Remote Activation Chime Event State";
BA_ "SignalType" SG_ 1410 PwrSdSldClsrRFLclActChmEvntStat "ENM";
BA_ "SignalLongName" SG_ 1410 PwrSdSldClsrRFLclActChmEvntStat "Power Side Sliding Closure Right Front Local Activation Chime Event State";
BA_ "SignalType" SG_ 1410 PwrSdSldClsrLRRmtActChmEvntStat "ENM";
BA_ "SignalLongName" SG_ 1410 PwrSdSldClsrLRRmtActChmEvntStat "Power Side Sliding Closure Left Rear Remote Activation Chime Event State";
BA_ "SignalType" SG_ 1410 PwrSdSldClsrLRLclActChmEvntStat "ENM";
BA_ "SignalLongName" SG_ 1410 PwrSdSldClsrLRLclActChmEvntStat "Power Side Sliding Closure Left Rear Local Activation Chime Event State";
BA_ "SignalType" SG_ 1410 PwrSdSwgClsrLFRmtActChmEvntStat "ENM";
BA_ "SignalLongName" SG_ 1410 PwrSdSwgClsrLFRmtActChmEvntStat "Power Side Swing Closure Left Front Remote Activation Chime Event State";
BA_ "SignalType" SG_ 1410 PwrSdSwgClsrLFLclActChmEvntStat "ENM";
BA_ "SignalLongName" SG_ 1410 PwrSdSwgClsrLFLclActChmEvntStat "Power Side Swing Closure Left Front Local Activation Chime Event State";
BA_ "SignalType" SG_ 1410 PwrSdSldClsrRRRmtActChmEvntStat "ENM";
BA_ "SignalLongName" SG_ 1410 PwrSdSldClsrRRRmtActChmEvntStat "Power Side Sliding Closure Right Rear Remote Activation Chime Event State";
BA_ "SignalType" SG_ 1410 PwrSdSldClsrRRLclActChmEvntStat "ENM";
BA_ "SignalLongName" SG_ 1410 PwrSdSldClsrRRLclActChmEvntStat "Power Side Sliding Closure Right Rear Local Activation Chime Event State";
BA_ "SignalType" SG_ 1410 PwrSdSwgClsrRFRmtActChmEvntStat "ENM";
BA_ "SignalLongName" SG_ 1410 PwrSdSwgClsrRFRmtActChmEvntStat "Power Side Swing Closure Right Front Remote Activation Chime Event State";
BA_ "SignalType" SG_ 1410 PwrSdSwgClsrRFLclActChmEvntStat "ENM";
BA_ "SignalLongName" SG_ 1410 PwrSdSwgClsrRFLclActChmEvntStat "Power Side Swing Closure Right Front Local Activation Chime Event State";
BA_ "SignalType" SG_ 1410 PwrSdSwgClsrLRRmtActChmEvntStat "ENM";
BA_ "SignalLongName" SG_ 1410 PwrSdSwgClsrLRRmtActChmEvntStat "Power Side Swing Closure Left Rear Remote Activation Chime Event State";
BA_ "SignalType" SG_ 1410 PwrSdSwgClsrLRLclActChmEvntStat "ENM";
BA_ "SignalLongName" SG_ 1410 PwrSdSwgClsrLRLclActChmEvntStat "Power Side Swing Closure Left Rear Local Activation Chime Event State";
BA_ "SignalType" SG_ 1410 RIMIntCllnChmEvStat "ENM";
BA_ "SignalLongName" SG_ 1410 RIMIntCllnChmEvStat "Rearward Impact Mitigation Initial Collision Chime Event State";
BA_ "SignalType" SG_ 1410 RIMBrkPlsChEvStat "ENM";
BA_ "SignalLongName" SG_ 1410 RIMBrkPlsChEvStat "Rearward Impact Mitigation Brake Pulse Chime Event State";
BA_ "SignalType" SG_ 1410 PwrSdSwgClsrRRRmtActChmEvntStat "ENM";
BA_ "SignalLongName" SG_ 1410 PwrSdSwgClsrRRRmtActChmEvntStat "Power Side Swing Closure Right Rear Remote Activation Chime Event State";
BA_ "SignalType" SG_ 1410 PwrSdSwgClsrRRLclActChmEvntStat "ENM";
BA_ "SignalLongName" SG_ 1410 PwrSdSwgClsrRRLclActChmEvntStat "Power Side Swing Closure Right Rear Local Activation Chime Event State";
BA_ "SignalType" SG_ 1410 WlkAwyLkInhbtChmEvSt "ENM";
BA_ "SignalLongName" SG_ 1410 WlkAwyLkInhbtChmEvSt "Walk Away Lock Inhibit Chime Request";
BA_ "SignalType" SG_ 1410 RrPCMChmEvntSt "ENM";
BA_ "SignalLongName" SG_ 1410 RrPCMChmEvntSt "Rear Pedestrian Collision Mitigation Chime Event State";
BA_ "SignalType" SG_ 1410 RlOvrDsblStsChgChmEvntStat "ENM";
BA_ "SignalLongName" SG_ 1410 RlOvrDsblStsChgChmEvntStat "Rollover Disable Status Change Chime Event State";
BA_ "SignalType" SG_ 1410 AutMemRclCstAvlFlg5 "ENM";
BA_ "SignalLongName" SG_ 1410 AutMemRclCstAvlFlg5 "AutoMemoryRecallCustomizationAvailabilityFlag5";
BA_ "SignalType" SG_ 1410 AutMemRclCstAvlFlg4 "ENM";
BA_ "SignalLongName" SG_ 1410 AutMemRclCstAvlFlg4 "AutoMemoryRecallCustomizationAvailabilityFlag4";
BA_ "SignalType" SG_ 1410 AutMemRclCstAvlFlg3 "ENM";
BA_ "SignalLongName" SG_ 1410 AutMemRclCstAvlFlg3 "AutoMemoryRecallCustomizationAvailabilityFlag3";
BA_ "SignalType" SG_ 1410 AutMemRclCstAvlFlg2 "ENM";
BA_ "SignalLongName" SG_ 1410 AutMemRclCstAvlFlg2 "AutoMemoryRecallCustomizationAvailabilityFlag2";
BA_ "SignalType" SG_ 1410 AutMemRclCstAvlFlg1 "ENM";
BA_ "SignalLongName" SG_ 1410 AutMemRclCstAvlFlg1 "AutoMemoryRecallCustomizationAvailabilityFlag1";
BA_ "SignalType" SG_ 1410 AdpLghtRspTypCstAvlFlg7 "ENM";
BA_ "SignalLongName" SG_ 1410 AdpLghtRspTypCstAvlFlg7 "Adaptive Lighting Response Type Customization Availability Flag7";
BA_ "SignalType" SG_ 1410 AdpLghtRspTypCstAvlFlg6 "ENM";
BA_ "SignalLongName" SG_ 1410 AdpLghtRspTypCstAvlFlg6 "Adaptive Lighting Response Type Customization Availability Flag6";
BA_ "SignalType" SG_ 1410 AdpLghtRspTypCstAvlFlg5 "ENM";
BA_ "SignalLongName" SG_ 1410 AdpLghtRspTypCstAvlFlg5 "Adaptive Lighting Response Type Customization Availability Flag5";
BA_ "SignalType" SG_ 1411 EsyExtCstAvlFlg5 "ENM";
BA_ "SignalLongName" SG_ 1411 EsyExtCstAvlFlg5 "EasyExitCustomizationAvailabilityFlag5";
BA_ "SignalType" SG_ 1411 EsyExtCstAvlFlg4 "ENM";
BA_ "SignalLongName" SG_ 1411 EsyExtCstAvlFlg4 "EasyExitCustomizationAvailabilityFlag4";
BA_ "SignalType" SG_ 1411 EsyExtCstAvlFlg3 "ENM";
BA_ "SignalLongName" SG_ 1411 EsyExtCstAvlFlg3 "EasyExitCustomizationAvailabilityFlag3";
BA_ "SignalType" SG_ 1411 EsyExtCstAvlFlg2 "ENM";
BA_ "SignalLongName" SG_ 1411 EsyExtCstAvlFlg2 "EasyExitCustomizationAvailabilityFlag2";
BA_ "SignalType" SG_ 1411 EsyExtCstAvlFlg1 "ENM";
BA_ "SignalLongName" SG_ 1411 EsyExtCstAvlFlg1 "EasyExitCustomizationAvailabilityFlag1";
BA_ "SignalType" SG_ 1411 EngIdlAtv "ENM";
BA_ "SignalLongName" SG_ 1411 EngIdlAtv "Engine Idle Active";
BA_ "SignalType" SG_ 1411 AutMemRclCstAvlFlg7 "ENM";
BA_ "SignalLongName" SG_ 1411 AutMemRclCstAvlFlg7 "AutoMemoryRecallCustomizationAvailabilityFlag7";
BA_ "SignalType" SG_ 1411 AutMemRclCstAvlFlg6 "ENM";
BA_ "SignalLongName" SG_ 1411 AutMemRclCstAvlFlg6 "AutoMemoryRecallCustomizationAvailabilityFlag6";
BA_ "SignalType" SG_ 1411 RrPCMRspTypCstAvlFlg2 "ENM";
BA_ "SignalLongName" SG_ 1411 RrPCMRspTypCstAvlFlg2 "Rear Pedestrian Collision Mitigation Response Type Customization Availability Flag 2";
BA_ "SignalType" SG_ 1411 RrPCMRspTypCstAvlFlg1 "ENM";
BA_ "SignalLongName" SG_ 1411 RrPCMRspTypCstAvlFlg1 "Rear Pedestrian Collision Mitigation Response Type Customization Availability Flag 1";
BA_ "SignalType" SG_ 1411 LowBmAct "ENM";
BA_ "SignalLongName" SG_ 1411 LowBmAct "Low Beams Active";
BA_ "SignalType" SG_ 1411 LDWCtrlAudAttnReqd "ENM";
BA_ "SignalLongName" SG_ 1411 LDWCtrlAudAttnReqd "Lane Detection Warning and Control Audio Attenuation Requested";
BA_ "SignalType" SG_ 1411 HighBmAct "ENM";
BA_ "SignalLongName" SG_ 1411 HighBmAct "High Beams Active";
BA_ "SignalType" SG_ 1411 FlToPsSwAtv "ENM";
BA_ "SignalLongName" SG_ 1411 FlToPsSwAtv "Flash To Pass Active";
BA_ "SignalType" SG_ 1411 EsyExtCstAvlFlg7 "ENM";
BA_ "SignalLongName" SG_ 1411 EsyExtCstAvlFlg7 "EasyExitCustomizationAvailabilityFlag7";
BA_ "SignalType" SG_ 1411 EsyExtCstAvlFlg6 "ENM";
BA_ "SignalLongName" SG_ 1411 EsyExtCstAvlFlg6 "EasyExitCustomizationAvailabilityFlag6";
BA_ "SignalType" SG_ 1411 TrlrConnStat "ENM";
BA_ "SignalLongName" SG_ 1411 TrlrConnStat "Trailer Connection Status";
BA_ "SignalType" SG_ 1411 StrgLckd "ENM";
BA_ "SignalLongName" SG_ 1411 StrgLckd "Storage Locked";
BA_ "SignalType" SG_ 1411 RrPCMRspTypCstStAvl "ENM";
BA_ "SignalLongName" SG_ 1411 RrPCMRspTypCstStAvl "Rear Pedestrian Collision Mitigation Response Type Customization Setting Available";
BA_ "SignalType" SG_ 1411 RrPCMRspTypCstAvlFlg7 "ENM";
BA_ "SignalLongName" SG_ 1411 RrPCMRspTypCstAvlFlg7 "Rear Pedestrian Collision Mitigation Response Type Customization Availability Flag 7";
BA_ "SignalType" SG_ 1411 RrPCMRspTypCstAvlFlg6 "ENM";
BA_ "SignalLongName" SG_ 1411 RrPCMRspTypCstAvlFlg6 "Rear Pedestrian Collision Mitigation Response Type Customization Availability Flag 6";
BA_ "SignalType" SG_ 1411 RrPCMRspTypCstAvlFlg5 "ENM";
BA_ "SignalLongName" SG_ 1411 RrPCMRspTypCstAvlFlg5 "Rear Pedestrian Collision Mitigation Response Type Customization Availability Flag 5";
BA_ "SignalType" SG_ 1411 RrPCMRspTypCstAvlFlg4 "ENM";
BA_ "SignalLongName" SG_ 1411 RrPCMRspTypCstAvlFlg4 "Rear Pedestrian Collision Mitigation Response Type Customization Availability Flag 4";
BA_ "SignalType" SG_ 1411 RrPCMRspTypCstAvlFlg3 "ENM";
BA_ "SignalLongName" SG_ 1411 RrPCMRspTypCstAvlFlg3 "Rear Pedestrian Collision Mitigation Response Type Customization Availability Flag 3";
BA_ "SignalLongName" SG_ 1411 IndBlwSetLvlFrtRt "Indication Blower Setting Level Front Right";
BA_ "SignalType" SG_ 1411 PwrRrClsrMtnSts "ENM";
BA_ "SignalLongName" SG_ 1411 PwrRrClsrMtnSts "Power Rear Closure Motion Status";
BA_ "SignalType" SG_ 1411 TrnLmpRtIO "ENM";
BA_ "SignalLongName" SG_ 1411 TrnLmpRtIO "Turn Lamp Right Indication On";
BA_ "SignalType" SG_ 1411 TrnLmpLftIO "ENM";
BA_ "SignalLongName" SG_ 1411 TrnLmpLftIO "Turn Lamp Left Indication On";
BA_ "SignalType" SG_ 1411 IndHtdArmrstLvlFrtLt "ENM";
BA_ "SignalLongName" SG_ 1411 IndHtdArmrstLvlFrtLt "Indication Heated Armrest Level Front Left";
BA_ "SignalLongName" SG_ 1411 IndBlwSetLvlRrRt "Indication Blower Setting Level Rear Right";
BA_ "SignalType" SG_ 1411 IndHtdArmrstLvlRrLt "ENM";
BA_ "SignalLongName" SG_ 1411 IndHtdArmrstLvlRrLt "Indication Heated Armrest Level Rear Left";
BA_ "SignalType" SG_ 1411 IndHtdArmrstLvlFrtRt "ENM";
BA_ "SignalLongName" SG_ 1411 IndHtdArmrstLvlFrtRt "Indication Heated Armrest Level Front Right";
BA_ "SignalLongName" SG_ 1480 SLVFSP_SpdLimVsnFsdSpdAuth "Speed Limit Vision Fused Speed Protected : Speed Limit Vision Fused Speed Authenticated";
BA_ "SignalType" SG_ 1480 SLVFSP_SpdLimVsnFsdSpdUntAuth "ENM";
BA_ "SignalLongName" SG_ 1480 SLVFSP_SpdLimVsnFsdSpdUntAuth "Speed Limit Vision Fused Speed Protected : Speed Limit Vision Fused Speed Unit Authenticated";
BA_ "SignalType" SG_ 1481 LFSCDS_CshLgAdjFdRr "ENM";
BA_ "SignalLongName" SG_ 1481 LFSCDS_CshLgAdjFdRr "Left Front Seat Control Display Status : Cushion Length Adjustment Forward/Rearward";
BA_ "SignalType" SG_ 1481 LFSCDS_CshBlstrInOut "ENM";
BA_ "SignalLongName" SG_ 1481 LFSCDS_CshBlstrInOut "Left Front Seat Control Display Status : Cushion Bolster In/Out";
BA_ "SignalType" SG_ 1481 LFSCDS_BkCshBlstInOt "ENM";
BA_ "SignalLongName" SG_ 1481 LFSCDS_BkCshBlstInOt "Left Front Seat Control Display Status : Back and Cushion Bolster In/Out";
BA_ "SignalType" SG_ 1481 LFSCDS_BkBlstrInOut "ENM";
BA_ "SignalLongName" SG_ 1481 LFSCDS_BkBlstrInOut "Left Front Seat Control Display Status : Back Bolster In/Out";
BA_ "SignalType" SG_ 1481 LFSCDS_HdrstTltFwdRr "ENM";
BA_ "SignalLongName" SG_ 1481 LFSCDS_HdrstTltFwdRr "Left Front Seat Control Display Status : Headrest Tilt Forward/Rearward";
BA_ "SignalType" SG_ 1481 LFSCDS_HdrstFwdRrwd "ENM";
BA_ "SignalLongName" SG_ 1481 LFSCDS_HdrstFwdRrwd "Left Front Seat Control Display Status : Headrest Forward/Rearward";
BA_ "SignalType" SG_ 1481 LFSCDS_HdrstFdRrUDn "ENM";
BA_ "SignalLongName" SG_ 1481 LFSCDS_HdrstFdRrUDn "Left Front Seat Control Display Status : Headrest Forward/Rearward and Up/Down";
BA_ "SignalType" SG_ 1481 LFSCDS_DispReq "ENM";
BA_ "SignalLongName" SG_ 1481 LFSCDS_DispReq "Left Front Seat Control Display Status : Display Request";
BA_ "SignalType" SG_ 1481 LFSCDS_LmbrUDnFdRr "ENM";
BA_ "SignalLongName" SG_ 1481 LFSCDS_LmbrUDnFdRr "Left Front Seat Control Display Status : Lumbar Up/Down and Forward/Rearward";
BA_ "SignalType" SG_ 1481 LFSCDS_LmbrFwdRr "ENM";
BA_ "SignalLongName" SG_ 1481 LFSCDS_LmbrFwdRr "Left Front Seat Control Display Status : Lumbar Forward/Rearward";
BA_ "SignalType" SG_ 1481 LFSCDS_HdrstWngInOt "ENM";
BA_ "SignalLongName" SG_ 1481 LFSCDS_HdrstWngInOt "Left Front Seat Control Display Status : Headrest Wings In/Out";
BA_ "SignalType" SG_ 1481 LFSCDS_HdrstUpDn "ENM";
BA_ "SignalLongName" SG_ 1481 LFSCDS_HdrstUpDn "Left Front Seat Control Display Status : Headrest Up/Down";
BA_ "SignalType" SG_ 1481 LFSCDS_MassgIntsty "ENM";
BA_ "SignalLongName" SG_ 1481 LFSCDS_MassgIntsty "Left Front Seat Control Display Status : Massage Intensity";
BA_ "SignalType" SG_ 1481 LFSCDS_Massg "ENM";
BA_ "SignalLongName" SG_ 1481 LFSCDS_Massg "Left Front Seat Control Display Status : Massage";
BA_ "SignalType" SG_ 1481 LFSCDS_LmbrUpDwn "ENM";
BA_ "SignalLongName" SG_ 1481 LFSCDS_LmbrUpDwn "Left Front Seat Control Display Status : Lumbar Up/Down";
BA_ "SignalType" SG_ 1481 APAWI_AutoStrgIconReq "ENM";
BA_ "SignalLongName" SG_ 1481 APAWI_AutoStrgIconReq "Advanced Park Assist Warning Indications : Advanced Park Assist Auto Steering Icon Request";
BA_ "SignalType" SG_ 1481 LFSCDS_UprShldrFdRr "ENM";
BA_ "SignalLongName" SG_ 1481 LFSCDS_UprShldrFdRr "Left Front Seat Control Display Status : Upper Shoulder Forward/Rearward";
BA_ "SignalType" SG_ 1481 LFSCDS_MassgTyp "ENM";
BA_ "SignalLongName" SG_ 1481 LFSCDS_MassgTyp "Left Front Seat Control Display Status : Massage Type";
BA_ "SignalLongName" SG_ 1481 APAWI_MnvrPrgs "Advanced Park Assist Warning Indications : Advanced Park Assist Maneuver Progress";
BA_ "SignalType" SG_ 1481 APAWI_FcsReq "ENM";
BA_ "SignalLongName" SG_ 1481 APAWI_FcsReq "Advanced Park Assist Warning Indications : Advanced Park Assist Focus Request";
BA_ "SignalType" SG_ 1481 AdpLghtRspTypCstStAvl "ENM";
BA_ "SignalLongName" SG_ 1481 AdpLghtRspTypCstStAvl "Adaptive Lighting Response Type Customization Setting Available";
BA_ "SignalType" SG_ 1481 APAWI_WrnIndReq "ENM";
BA_ "SignalLongName" SG_ 1481 APAWI_WrnIndReq "Advanced Park Assist Warning Indications : Advanced Park Assist Warning Indication Request";
BA_ "SignalType" SG_ 1465 LRSCDS_CshLgAdjFdRr "ENM";
BA_ "SignalLongName" SG_ 1465 LRSCDS_CshLgAdjFdRr "Left Rear Seat Control Display Status : Cushion Length Adjustment Forward/Rearward";
BA_ "SignalType" SG_ 1465 LRSCDS_CshBlstrInOut "ENM";
BA_ "SignalLongName" SG_ 1465 LRSCDS_CshBlstrInOut "Left Rear Seat Control Display Status : Cushion Bolster In/Out";
BA_ "SignalType" SG_ 1465 LRSCDS_BkCshBlstInOt "ENM";
BA_ "SignalLongName" SG_ 1465 LRSCDS_BkCshBlstInOt "Left Rear Seat Control Display Status : Back and Cushion Bolster In/Out";
BA_ "SignalType" SG_ 1465 LRSCDS_BkBlstrInOut "ENM";
BA_ "SignalLongName" SG_ 1465 LRSCDS_BkBlstrInOut "Left Rear Seat Control Display Status : Back Bolster In/Out";
BA_ "SignalType" SG_ 1465 LRSCDS_HdrstTltFwdRr "ENM";
BA_ "SignalLongName" SG_ 1465 LRSCDS_HdrstTltFwdRr "Left Rear Seat Control Display Status : Headrest Tilt Forward/Rearward";
BA_ "SignalType" SG_ 1465 LRSCDS_HdrstFwdRrwd "ENM";
BA_ "SignalLongName" SG_ 1465 LRSCDS_HdrstFwdRrwd "Left Rear Seat Control Display Status : Headrest Forward/Rearward";
BA_ "SignalType" SG_ 1465 LRSCDS_HdrstFdRrUDn "ENM";
BA_ "SignalLongName" SG_ 1465 LRSCDS_HdrstFdRrUDn "Left Rear Seat Control Display Status : Headrest Forward/Rearward and Up/Down";
BA_ "SignalType" SG_ 1465 LRSCDS_DispReq "ENM";
BA_ "SignalLongName" SG_ 1465 LRSCDS_DispReq "Left Rear Seat Control Display Status : Display Request";
BA_ "SignalType" SG_ 1465 LRSCDS_LmbrUDnFdRr "ENM";
BA_ "SignalLongName" SG_ 1465 LRSCDS_LmbrUDnFdRr "Left Rear Seat Control Display Status : Lumbar Up/Down and Forward/Rearward";
BA_ "SignalType" SG_ 1465 LRSCDS_LmbrFwdRr "ENM";
BA_ "SignalLongName" SG_ 1465 LRSCDS_LmbrFwdRr "Left Rear Seat Control Display Status : Lumbar Forward/Rearward";
BA_ "SignalType" SG_ 1465 LRSCDS_HdrstWngInOt "ENM";
BA_ "SignalLongName" SG_ 1465 LRSCDS_HdrstWngInOt "Left Rear Seat Control Display Status : Headrest Wings In/Out";
BA_ "SignalType" SG_ 1465 LRSCDS_HdrstUpDn "ENM";
BA_ "SignalLongName" SG_ 1465 LRSCDS_HdrstUpDn "Left Rear Seat Control Display Status : Headrest Up/Down";
BA_ "SignalType" SG_ 1465 LRSCDS_MassgIntsty "ENM";
BA_ "SignalLongName" SG_ 1465 LRSCDS_MassgIntsty "Left Rear Seat Control Display Status : Massage Intensity";
BA_ "SignalType" SG_ 1465 LRSCDS_Massg "ENM";
BA_ "SignalLongName" SG_ 1465 LRSCDS_Massg "Left Rear Seat Control Display Status : Massage";
BA_ "SignalType" SG_ 1465 LRSCDS_LmbrUpDwn "ENM";
BA_ "SignalLongName" SG_ 1465 LRSCDS_LmbrUpDwn "Left Rear Seat Control Display Status : Lumbar Up/Down";
BA_ "SignalType" SG_ 1465 SDGPARS_CntrLtSd "ENM";
BA_ "SignalLongName" SG_ 1465 SDGPARS_CntrLtSd "Side Distance Guard Park Assist Region Status : Center Left Side Region";
BA_ "SignalType" SG_ 1465 LRSCDS_UprShldrFdRr "ENM";
BA_ "SignalLongName" SG_ 1465 LRSCDS_UprShldrFdRr "Left Rear Seat Control Display Status : Upper Shoulder Forward/Rearward";
BA_ "SignalType" SG_ 1465 LRSCDS_MassgTyp "ENM";
BA_ "SignalLongName" SG_ 1465 LRSCDS_MassgTyp "Left Rear Seat Control Display Status : Massage Type";
BA_ "SignalType" SG_ 1465 SDGPARS_FrtLtSd "ENM";
BA_ "SignalLongName" SG_ 1465 SDGPARS_FrtLtSd "Side Distance Guard Park Assist Region Status : Front Left Side Region";
BA_ "SignalType" SG_ 1465 SDGPARS_CntrRtSd "ENM";
BA_ "SignalLongName" SG_ 1465 SDGPARS_CntrRtSd "Side Distance Guard Park Assist Region Status : Center Right Side Region";
BA_ "SignalType" SG_ 1465 SDGPARS_RrLtSd "ENM";
BA_ "SignalLongName" SG_ 1465 SDGPARS_RrLtSd "Side Distance Guard Park Assist Region Status : Rear Left Side Region";
BA_ "SignalType" SG_ 1465 SDGPARS_FrtRtSd "ENM";
BA_ "SignalLongName" SG_ 1465 SDGPARS_FrtRtSd "Side Distance Guard Park Assist Region Status : Front Right Side Region";
BA_ "SignalType" SG_ 1465 AirbgStIndOn "ENM";
BA_ "SignalLongName" SG_ 1465 AirbgStIndOn "Airbag Status Indication On";
BA_ "SignalType" SG_ 1465 SDGPARS_RrRtSd "ENM";
BA_ "SignalLongName" SG_ 1465 SDGPARS_RrRtSd "Side Distance Guard Park Assist Region Status : Rear Right Side Region";
BA_ "SignalType" SG_ 1483 RFSCDS_CshLgAdjFdRr "ENM";
BA_ "SignalLongName" SG_ 1483 RFSCDS_CshLgAdjFdRr "Right Front Seat Control Display Status : Cushion Length Adjustment Forward/Rearward";
BA_ "SignalType" SG_ 1483 RFSCDS_CshBlstrInOut "ENM";
BA_ "SignalLongName" SG_ 1483 RFSCDS_CshBlstrInOut "Right Front Seat Control Display Status : Cushion Bolster In/Out";
BA_ "SignalType" SG_ 1483 RFSCDS_BkCshBlstInOt "ENM";
BA_ "SignalLongName" SG_ 1483 RFSCDS_BkCshBlstInOt "Right Front Seat Control Display Status : Back and Cushion Bolster In/Out";
BA_ "SignalType" SG_ 1483 RFSCDS_BkBlstrInOut "ENM";
BA_ "SignalLongName" SG_ 1483 RFSCDS_BkBlstrInOut "Right Front Seat Control Display Status : Back Bolster In/Out";
BA_ "SignalType" SG_ 1483 RFSCDS_HdrstTltFwdRr "ENM";
BA_ "SignalLongName" SG_ 1483 RFSCDS_HdrstTltFwdRr "Right Front Seat Control Display Status : Headrest Tilt Forward/Rearward";
BA_ "SignalType" SG_ 1483 RFSCDS_HdrstFwdRrwd "ENM";
BA_ "SignalLongName" SG_ 1483 RFSCDS_HdrstFwdRrwd "Right Front Seat Control Display Status : Headrest Forward/Rearward";
BA_ "SignalType" SG_ 1483 RFSCDS_HdrstFdRrUDn "ENM";
BA_ "SignalLongName" SG_ 1483 RFSCDS_HdrstFdRrUDn "Right Front Seat Control Display Status : Headrest Forward/Rearward and Up/Down";
BA_ "SignalType" SG_ 1483 RFSCDS_DispReq "ENM";
BA_ "SignalLongName" SG_ 1483 RFSCDS_DispReq "Right Front Seat Control Display Status : Display Request";
BA_ "SignalType" SG_ 1483 RFSCDS_LmbrUDnFdRr "ENM";
BA_ "SignalLongName" SG_ 1483 RFSCDS_LmbrUDnFdRr "Right Front Seat Control Display Status : Lumbar Up/Down and Forward/Rearward";
BA_ "SignalType" SG_ 1483 RFSCDS_LmbrFwdRr "ENM";
BA_ "SignalLongName" SG_ 1483 RFSCDS_LmbrFwdRr "Right Front Seat Control Display Status : Lumbar Forward/Rearward";
BA_ "SignalType" SG_ 1483 RFSCDS_HdrstWngInOt "ENM";
BA_ "SignalLongName" SG_ 1483 RFSCDS_HdrstWngInOt "Right Front Seat Control Display Status : Headrest Wings In/Out";
BA_ "SignalType" SG_ 1483 RFSCDS_HdrstUpDn "ENM";
BA_ "SignalLongName" SG_ 1483 RFSCDS_HdrstUpDn "Right Front Seat Control Display Status : Headrest Up/Down";
BA_ "SignalType" SG_ 1483 RFSCDS_MassgIntsty "ENM";
BA_ "SignalLongName" SG_ 1483 RFSCDS_MassgIntsty "Right Front Seat Control Display Status : Massage Intensity";
BA_ "SignalType" SG_ 1483 RFSCDS_Massg "ENM";
BA_ "SignalLongName" SG_ 1483 RFSCDS_Massg "Right Front Seat Control Display Status : Massage";
BA_ "SignalType" SG_ 1483 RFSCDS_LmbrUpDwn "ENM";
BA_ "SignalLongName" SG_ 1483 RFSCDS_LmbrUpDwn "Right Front Seat Control Display Status : Lumbar Up/Down";
BA_ "SignalType" SG_ 1483 RideHghtSeltn1Pndg "ENM";
BA_ "SignalLongName" SG_ 1483 RideHghtSeltn1Pndg "Ride Height Selection Information : Ride Height Selection 1 Pending";
BA_ "SignalType" SG_ 1483 RFSCDS_UprShldrFdRr "ENM";
BA_ "SignalLongName" SG_ 1483 RFSCDS_UprShldrFdRr "Right Front Seat Control Display Status : Upper Shoulder Forward/Rearward";
BA_ "SignalType" SG_ 1483 RFSCDS_MassgTyp "ENM";
BA_ "SignalLongName" SG_ 1483 RFSCDS_MassgTyp "Right Front Seat Control Display Status : Massage Type";
BA_ "SignalType" SG_ 1483 RideHghtSeltn5Pndg "ENM";
BA_ "SignalLongName" SG_ 1483 RideHghtSeltn5Pndg "Ride Height Selection Information : Ride Height Selection 5 Pending";
BA_ "SignalType" SG_ 1483 RideHghtSeltn4Unv "ENM";
BA_ "SignalLongName" SG_ 1483 RideHghtSeltn4Unv "Ride Height Selection Information : Ride Height Selection 4 Unavailable";
BA_ "SignalType" SG_ 1483 RideHghtSeltn4Pndg "ENM";
BA_ "SignalLongName" SG_ 1483 RideHghtSeltn4Pndg "Ride Height Selection Information : Ride Height Selection 4 Pending";
BA_ "SignalType" SG_ 1483 RideHghtSeltn3Unv "ENM";
BA_ "SignalLongName" SG_ 1483 RideHghtSeltn3Unv "Ride Height Selection Information : Ride Height Selection 3 Unavailable";
BA_ "SignalType" SG_ 1483 RideHghtSeltn3Pndg "ENM";
BA_ "SignalLongName" SG_ 1483 RideHghtSeltn3Pndg "Ride Height Selection Information : Ride Height Selection 3 Pending";
BA_ "SignalType" SG_ 1483 RideHghtSeltn2Unv "ENM";
BA_ "SignalLongName" SG_ 1483 RideHghtSeltn2Unv "Ride Height Selection Information : Ride Height Selection 2 Unavailable";
BA_ "SignalType" SG_ 1483 RideHghtSeltn2Pndg "ENM";
BA_ "SignalLongName" SG_ 1483 RideHghtSeltn2Pndg "Ride Height Selection Information : Ride Height Selection 2 Pending";
BA_ "SignalType" SG_ 1483 RideHghtSeltn1Unv "ENM";
BA_ "SignalLongName" SG_ 1483 RideHghtSeltn1Unv "Ride Height Selection Information : Ride Height Selection 1 Unavailable";
BA_ "SignalType" SG_ 1483 OATP_OtsAirTmpCrValAuth_Inv "ENM";
BA_ "SignalLongName" SG_ 1483 OATP_OtsAirTmpCrValAuth_Inv "Serial Data 25 Protected : Outside Air Temperature Corrected Value Authenticated Invalid";
BA_ "SignalType" SG_ 1483 RideHghtSeltn8Unv "ENM";
BA_ "SignalLongName" SG_ 1483 RideHghtSeltn8Unv "Ride Height Selection Information : Ride Height Selection 8 Unavailable";
BA_ "SignalType" SG_ 1483 RideHghtSeltn8Pndg "ENM";
BA_ "SignalLongName" SG_ 1483 RideHghtSeltn8Pndg "Ride Height Selection Information : Ride Height Selection 8 Pending";
BA_ "SignalType" SG_ 1483 RideHghtSeltn7Unv "ENM";
BA_ "SignalLongName" SG_ 1483 RideHghtSeltn7Unv "Ride Height Selection Information : Ride Height Selection 7 Unavailable";
BA_ "SignalType" SG_ 1483 RideHghtSeltn7Pndg "ENM";
BA_ "SignalLongName" SG_ 1483 RideHghtSeltn7Pndg "Ride Height Selection Information : Ride Height Selection 7 Pending";
BA_ "SignalType" SG_ 1483 RideHghtSeltn6Unv "ENM";
BA_ "SignalLongName" SG_ 1483 RideHghtSeltn6Unv "Ride Height Selection Information : Ride Height Selection 6 Unavailable";
BA_ "SignalType" SG_ 1483 RideHghtSeltn6Pndg "ENM";
BA_ "SignalLongName" SG_ 1483 RideHghtSeltn6Pndg "Ride Height Selection Information : Ride Height Selection 6 Pending";
BA_ "SignalType" SG_ 1483 RideHghtSeltn5Unv "ENM";
BA_ "SignalLongName" SG_ 1483 RideHghtSeltn5Unv "Ride Height Selection Information : Ride Height Selection 5 Unavailable";
BA_ "SignalLongName" SG_ 1483 OATP_OtsAirTmpCrValAuth "Serial Data 25 Protected : Outside Air Temperature Corrected Value Authenticated";
BA_ "SignalType" SG_ 1484 RRSCDS_CshLgAdjFdRr "ENM";
BA_ "SignalLongName" SG_ 1484 RRSCDS_CshLgAdjFdRr "Right Rear Seat Control Display Status : Cushion Length Adjustment Forward/Rearward";
BA_ "SignalType" SG_ 1484 RRSCDS_CshBlstrInOut "ENM";
BA_ "SignalLongName" SG_ 1484 RRSCDS_CshBlstrInOut "Right Rear Seat Control Display Status : Cushion Bolster In/Out";
BA_ "SignalType" SG_ 1484 RRSCDS_BkCshBlstInOt "ENM";
BA_ "SignalLongName" SG_ 1484 RRSCDS_BkCshBlstInOt "Right Rear Seat Control Display Status : Back and Cushion Bolster In/Out";
BA_ "SignalType" SG_ 1484 RRSCDS_BkBlstrInOut "ENM";
BA_ "SignalLongName" SG_ 1484 RRSCDS_BkBlstrInOut "Right Rear Seat Control Display Status : Back Bolster In/Out";
BA_ "SignalType" SG_ 1484 RRSCDS_HdrstTltFwdRr "ENM";
BA_ "SignalLongName" SG_ 1484 RRSCDS_HdrstTltFwdRr "Right Rear Seat Control Display Status : Headrest Tilt Forward/Rearward";
BA_ "SignalType" SG_ 1484 RRSCDS_HdrstFwdRrwd "ENM";
BA_ "SignalLongName" SG_ 1484 RRSCDS_HdrstFwdRrwd "Right Rear Seat Control Display Status : Headrest Forward/Rearward";
BA_ "SignalType" SG_ 1484 RRSCDS_HdrstFdRrUDn "ENM";
BA_ "SignalLongName" SG_ 1484 RRSCDS_HdrstFdRrUDn "Right Rear Seat Control Display Status : Headrest Forward/Rearward and Up/Down";
BA_ "SignalType" SG_ 1484 RRSCDS_DispReq "ENM";
BA_ "SignalLongName" SG_ 1484 RRSCDS_DispReq "Right Rear Seat Control Display Status : Display Request";
BA_ "SignalType" SG_ 1484 RRSCDS_LmbrUDnFdRr "ENM";
BA_ "SignalLongName" SG_ 1484 RRSCDS_LmbrUDnFdRr "Right Rear Seat Control Display Status : Lumbar Up/Down and Forward/Rearward";
BA_ "SignalType" SG_ 1484 RRSCDS_LmbrFwdRr "ENM";
BA_ "SignalLongName" SG_ 1484 RRSCDS_LmbrFwdRr "Right Rear Seat Control Display Status : Lumbar Forward/Rearward";
BA_ "SignalType" SG_ 1484 RRSCDS_HdrstWngInOt "ENM";
BA_ "SignalLongName" SG_ 1484 RRSCDS_HdrstWngInOt "Right Rear Seat Control Display Status : Headrest Wings In/Out";
BA_ "SignalType" SG_ 1484 RRSCDS_HdrstUpDn "ENM";
BA_ "SignalLongName" SG_ 1484 RRSCDS_HdrstUpDn "Right Rear Seat Control Display Status : Headrest Up/Down";
BA_ "SignalType" SG_ 1484 RRSCDS_MassgIntsty "ENM";
BA_ "SignalLongName" SG_ 1484 RRSCDS_MassgIntsty "Right Rear Seat Control Display Status : Massage Intensity";
BA_ "SignalType" SG_ 1484 RRSCDS_Massg "ENM";
BA_ "SignalLongName" SG_ 1484 RRSCDS_Massg "Right Rear Seat Control Display Status : Massage";
BA_ "SignalType" SG_ 1484 RRSCDS_LmbrUpDwn "ENM";
BA_ "SignalLongName" SG_ 1484 RRSCDS_LmbrUpDwn "Right Rear Seat Control Display Status : Lumbar Up/Down";
BA_ "SignalType" SG_ 1484 RPARS_Lt "ENM";
BA_ "SignalLongName" SG_ 1484 RPARS_Lt "Rear Park Assist Region Status : Left Region";
BA_ "SignalType" SG_ 1484 RRSCDS_UprShldrFdRr "ENM";
BA_ "SignalLongName" SG_ 1484 RRSCDS_UprShldrFdRr "Right Rear Seat Control Display Status : Upper Shoulder Forward/Rearward";
BA_ "SignalType" SG_ 1484 RRSCDS_MassgTyp "ENM";
BA_ "SignalLongName" SG_ 1484 RRSCDS_MassgTyp "Right Rear Seat Control Display Status : Massage Type";
BA_ "SignalType" SG_ 1484 RPARS_Rt "ENM";
BA_ "SignalLongName" SG_ 1484 RPARS_Rt "Rear Park Assist Region Status : Right Region";
BA_ "SignalType" SG_ 1484 RPARS_LtCntr "ENM";
BA_ "SignalLongName" SG_ 1484 RPARS_LtCntr "Rear Park Assist Region Status : Left Center Region";
BA_ "SignalType" SG_ 1484 eLSDActrTrqPctg_Inv "ENM";
BA_ "SignalLongName" SG_ 1484 eLSDActrTrqPctg_Inv "Electronic Limited Slip Differential Actuator Torque Percentage Invalid";
BA_ "SignalType" SG_ 1484 RPARS_RtCntr "ENM";
BA_ "SignalLongName" SG_ 1484 RPARS_RtCntr "Rear Park Assist Region Status : Right Center Region";
BA_ "SignalLongName" SG_ 1484 eLSDActrTrqPctg "Electronic Limited Slip Differential Actuator Torque Percentage";
VAL_ 1940 StCushFrtVertRRVirtCtlAval 0 "Not Available" 1 "Available" ;
VAL_ 1940 StBkSdBolsRRVirtCtlAval 0 "Not Available" 1 "Available" ;
VAL_ 1940 StBkLumbVertRRVirtCtlAval 0 "Not Available" 1 "Available" ;
VAL_ 1940 StBkLumbHrztlRRVirtCtlAval 0 "Not Available" 1 "Available" ;
VAL_ 1940 StBkHrztlRRVirtCtlAval 0 "Not Available" 1 "Available" ;
VAL_ 1940 StMasgTyp11RRVirtCtlAval 0 "Not Available" 1 "Available" ;
VAL_ 1940 StMasgTyp10RRVirtCtlAval 0 "Not Available" 1 "Available" ;
VAL_ 1940 StHdrstVertRRVirtCtlAval 0 "Not Available" 1 "Available" ;
VAL_ 1940 StHdrstHrztlRRVirtCtlAval 0 "Not Available" 1 "Available" ;
VAL_ 1940 StCushSdBolsRRVirtCtlAval 0 "Not Available" 1 "Available" ;
VAL_ 1940 StCushRrVertRRVirtCtlAval 0 "Not Available" 1 "Available" ;
VAL_ 1940 StCushLgthHrztlRRVirtCtlAval 0 "Not Available" 1 "Available" ;
VAL_ 1940 StCushHrztlRRVirtCtlAval 0 "Not Available" 1 "Available" ;
VAL_ 1940 StMasgTyp4RRVirtCtlAval 0 "Not Available" 1 "Available" ;
VAL_ 1940 StMasgTyp3RRVirtCtlAval 0 "Not Available" 1 "Available" ;
VAL_ 1940 StMasgTyp2RRVirtCtlAval 0 "Not Available" 1 "Available" ;
VAL_ 1940 StMasgTyp1RRVirtCtlAval 0 "Not Available" 1 "Available" ;
VAL_ 1940 StMasgTyp15RRVirtCtlAval 0 "Not Available" 1 "Available" ;
VAL_ 1940 StMasgTyp14RRVirtCtlAval 0 "Not Available" 1 "Available" ;
VAL_ 1940 StMasgTyp13RRVirtCtlAval 0 "Not Available" 1 "Available" ;
VAL_ 1940 StMasgTyp12RRVirtCtlAval 0 "Not Available" 1 "Available" ;
VAL_ 1940 StBkLumbHrztlRRVirtCtlAllwd 0 "Not Allowed" 1 "Allowed" ;
VAL_ 1940 StBkHrztlRRVirtCtlAllwd 0 "Not Allowed" 1 "Allowed" ;
VAL_ 1940 StUpprShldrHrztlRRVirtCtlAval 0 "Not Available" 1 "Available" ;
VAL_ 1940 StMasgTyp9RRVirtCtlAval 0 "Not Available" 1 "Available" ;
VAL_ 1940 StMasgTyp8RRVirtCtlAval 0 "Not Available" 1 "Available" ;
VAL_ 1940 StMasgTyp7RRVirtCtlAval 0 "Not Available" 1 "Available" ;
VAL_ 1940 StMasgTyp6RRVirtCtlAval 0 "Not Available" 1 "Available" ;
VAL_ 1940 StMasgTyp5RRVirtCtlAval 0 "Not Available" 1 "Available" ;
VAL_ 1940 StHdrstHrztlRRVirtCtlAllwd 0 "Not Allowed" 1 "Allowed" ;
VAL_ 1940 StCushSdBolsRRVirtCtlAllwd 0 "Not Allowed" 1 "Allowed" ;
VAL_ 1940 StCushRrVertRRVirtCtlAllwd 0 "Not Allowed" 1 "Allowed" ;
VAL_ 1940 StCushLgthHrztlRRVirtCtlAllwd 0 "Not Allowed" 1 "Allowed" ;
VAL_ 1940 StCushHrztlRRVirtCtlAllwd 0 "Not Allowed" 1 "Allowed" ;
VAL_ 1940 StCushFrtVertRRVirtCtlAllwd 0 "Not Allowed" 1 "Allowed" ;
VAL_ 1940 StBkSdBolsRRVirtCtlAllwd 0 "Not Allowed" 1 "Allowed" ;
VAL_ 1940 StBkLumbVertRRVirtCtlAllwd 0 "Not Allowed" 1 "Allowed" ;
VAL_ 1940 StMasgIntstyRRLstKnwnSet 0 "Massage Off" 1 "Intensity 1" 2 "Intensity 2" 3 "Intensity 3" 4 "Intensity 4" 5 "Intensity 5" 6 "Intensity 6" 7 "Intensity 7" ;
VAL_ 1940 StMasgTypRRLstKnwnSet 0 "Massage Off" 1 "Type 1" 2 "Type 2" 3 "Type 3" 4 "Type 4" 5 "Type 5" 6 "Type 6" 7 "Type 7" 8 "Type 8" 9 "Type 9" 10 "Type 10" 11 "Type 11" 12 "Type 12" 13 "Type 13" 14 "Type 14" 15 "Type 15" ;
VAL_ 1940 StUpprShldrHrztlRRVirtCtlAllwd 0 "Not Allowed" 1 "Allowed" ;
VAL_ 1940 StMasgRRVirtCtlAllwd 0 "Not Allowed" 1 "Allowed" ;
VAL_ 1940 StHdrstVertRRVirtCtlAllwd 0 "Not Allowed" 1 "Allowed" ;
VAL_ 1940 StMemRRVirtCtlNumofMemPstnsAval 0 "Not Available" 1 "One Positions" 2 "Two Positions" 3 "Three Positions" 4 "Four Positions" 5 "Five Positions" 6 "Six Positions" 7 "Seven Positions" 8 "Eight Positions" ;
VAL_ 1940 StMemRRVirtCtlNumofExtPstnsAval 0 "Not Available" 1 "One Positions" 2 "Two Positions" 3 "Three Positions" 4 "Four Positions" 5 "Five Positions" 6 "Six Positions" 7 "Seven Positions" 8 "Eight Positions" ;
VAL_ 1964 StCushFrtVertLRVirtCtlAval 0 "Not Available" 1 "Available" ;
VAL_ 1964 StBkSdBolsLRVirtCtlAval 0 "Not Available" 1 "Available" ;
VAL_ 1964 StBkLumbVertLRVirtCtlAval 0 "Not Available" 1 "Available" ;
VAL_ 1964 StBkLumbHrztlLRVirtCtlAval 0 "Not Available" 1 "Available" ;
VAL_ 1964 StBkHrztlLRVirtCtlAval 0 "Not Available" 1 "Available" ;
VAL_ 1964 StMasgTyp11LRVirtCtlAval 0 "Not Available" 1 "Available" ;
VAL_ 1964 StMasgTyp10LRVirtCtlAval 0 "Not Available" 1 "Available" ;
VAL_ 1964 StHdrstVertLRVirtCtlAval 0 "Not Available" 1 "Available" ;
VAL_ 1964 StHdrstHrztlLRVirtCtlAval 0 "Not Available" 1 "Available" ;
VAL_ 1964 StCushSdBolsLRVirtCtlAval 0 "Not Available" 1 "Available" ;
VAL_ 1964 StCushRrVertLRVirtCtlAval 0 "Not Available" 1 "Available" ;
VAL_ 1964 StCushLgthHrztlLRVirtCtlAval 0 "Not Available" 1 "Available" ;
VAL_ 1964 StCushHrztlLRVirtCtlAval 0 "Not Available" 1 "Available" ;
VAL_ 1964 StMasgTyp4LRVirtCtlAval 0 "Not Available" 1 "Available" ;
VAL_ 1964 StMasgTyp3LRVirtCtlAval 0 "Not Available" 1 "Available" ;
VAL_ 1964 StMasgTyp2LRVirtCtlAval 0 "Not Available" 1 "Available" ;
VAL_ 1964 StMasgTyp1LRVirtCtlAval 0 "Not Available" 1 "Available" ;
VAL_ 1964 StMasgTyp15LRVirtCtlAval 0 "Not Available" 1 "Available" ;
VAL_ 1964 StMasgTyp14LRVirtCtlAval 0 "Not Available" 1 "Available" ;
VAL_ 1964 StMasgTyp13LRVirtCtlAval 0 "Not Available" 1 "Available" ;
VAL_ 1964 StMasgTyp12LRVirtCtlAval 0 "Not Available" 1 "Available" ;
VAL_ 1964 StMemLRVirtCtlNumofExtPstnsAval 0 "Not Available" 1 "One Positions" 2 "Two Positions" 3 "Three Positions" 4 "Four Positions" 5 "Five Positions" 6 "Six Positions" 7 "Seven Positions" 8 "Eight Positions" ;
VAL_ 1964 StUpprShldrHrztlLRVirtCtlAval 0 "Not Available" 1 "Available" ;
VAL_ 1964 StMasgTyp9LRVirtCtlAval 0 "Not Available" 1 "Available" ;
VAL_ 1964 StMasgTyp8LRVirtCtlAval 0 "Not Available" 1 "Available" ;
VAL_ 1964 StMasgTyp7LRVirtCtlAval 0 "Not Available" 1 "Available" ;
VAL_ 1964 StMasgTyp6LRVirtCtlAval 0 "Not Available" 1 "Available" ;
VAL_ 1964 StMasgTyp5LRVirtCtlAval 0 "Not Available" 1 "Available" ;
VAL_ 1964 RrDrOpnCmfRclCstAvlFlg2 0 "FALSE" 1 "TRUE" ;
VAL_ 1964 RrDrOpnCmfRclCstAvlFlg1 0 "FALSE" 1 "TRUE" ;
VAL_ 1964 StMemLRVirtCtlNumofMemPstnsAval 0 "Not Available" 1 "One Positions" 2 "Two Positions" 3 "Three Positions" 4 "Four Positions" 5 "Five Positions" 6 "Six Positions" 7 "Seven Positions" 8 "Eight Positions" ;
VAL_ 1964 RrDrOpnCmfRclCstSetAval 0 "FALSE" 1 "TRUE" ;
VAL_ 1964 RrDrOpnCmfRclCstAvlFlg7 0 "FALSE" 1 "TRUE" ;
VAL_ 1964 RrDrOpnCmfRclCstAvlFlg6 0 "FALSE" 1 "TRUE" ;
VAL_ 1964 RrDrOpnCmfRclCstAvlFlg5 0 "FALSE" 1 "TRUE" ;
VAL_ 1964 RrDrOpnCmfRclCstAvlFlg4 0 "FALSE" 1 "TRUE" ;
VAL_ 1964 RrDrOpnCmfRclCstAvlFlg3 0 "FALSE" 1 "TRUE" ;
VAL_ 1295 SCAOOAByVirtKeyRFCstCurrSetVal 0 "Setting Unknown" 1 "Off" 2 "On" ;
VAL_ 1295 SCAOOAByKeyFobRFCstCurrSetVal 0 "Setting Unknown" 1 "Off" 2 "On" ;
VAL_ 1058 PwrSdClsrRRBlckdIndOn 0 "FALSE" 1 "TRUE" ;
VAL_ 1058 PwrSdClsrRRServIndOn 0 "FALSE" 1 "TRUE" ;
VAL_ 1406 ASS_DSPMd6Prsnt 0 "FALSE" 1 "TRUE" ;
VAL_ 1406 ASS_DSPMd5Prsnt 0 "FALSE" 1 "TRUE" ;
VAL_ 1406 ASS_DSPMd4Prsnt 0 "FALSE" 1 "TRUE" ;
VAL_ 1406 ASS_DSPMd3Prsnt 0 "FALSE" 1 "TRUE" ;
VAL_ 1406 ASS_DSPMd2Prsnt 0 "FALSE" 1 "TRUE" ;
VAL_ 1406 ASS_DSPMd1Prsnt 0 "FALSE" 1 "TRUE" ;
VAL_ 1406 ASS_DSPMd0Prsnt 0 "FALSE" 1 "TRUE" ;
VAL_ 1406 ASS_DSPAvail 0 "FALSE" 1 "TRUE" ;
VAL_ 1406 ASS_VehNoisCmpnAvail 0 "FALSE" 1 "TRUE" ;
VAL_ 1406 ASS_SurndAvail 0 "FALSE" 1 "TRUE" ;
VAL_ 1406 ASS_PhLckdLpLckd 0 "FALSE" 1 "TRUE" ;
VAL_ 1406 ASS_MtxSnkMutStat 0 "FALSE" 1 "TRUE" ;
VAL_ 1406 ASS_DSPMd7Prsnt 0 "FALSE" 1 "TRUE" ;
VAL_ 1406 FrtPsngrMtxSnkMutSts 0 "FALSE" 1 "TRUE" ;
VAL_ 1406 CCSI_CrtclChmPrdcrSOH 0 "Unknown" 1 "Healthy" 2 "Faulted" ;
VAL_ 1406 AmpCallAudPlybkSOH 0 "Unknown" 1 "Healthy" 2 "Faulted" ;
VAL_ 1406 RRMtxSnkMutSts 0 "FALSE" 1 "TRUE" ;
VAL_ 1406 LRMtxSnkMutSts 0 "FALSE" 1 "TRUE" ;
VAL_ 1406 AmpSOHALAutoLdnsCmpnAtv 0 "FALSE" 1 "TRUE" ;
VAL_ 1406 AmpSOHALMutCaus 0 "Unknown" 1 "CAN Requested" 2 "DSP Mode Changed" 3 "Other Internal" ;
VAL_ 1525 PhnZnAudSOH 0 "Unknown" 1 "Healthy" 2 "Faulted" ;
VAL_ 1525 QdZnAudVolCtlAval 0 "FALSE" 1 "TRUE" ;
VAL_ 1525 FrtZnAudVolCtlAval 0 "FALSE" 1 "TRUE" ;
VAL_ 1525 DirAudPrmtRndrngActv 0 "FALSE" 1 "TRUE" ;
VAL_ 1525 HMIInCarVcCommSts 0 "ICC_Off" 1 "ICC_Idle" 2 "Front_High_Rear_High" 3 "Front_High_Rear_Normal" 4 "Front_High_Rear_Off" 5 "Front_Normal_Rear_High" 6 "Front_Normal_Rear_Normal" 7 "Front_Normal_Rear_Off" ;
VAL_ 1525 PhnZnAval 0 "FALSE" 1 "TRUE" ;
VAL_ 75 YawRateAuth_Inv 0 "FALSE" 1 "TRUE" ;
VAL_ 75 YawRateAuth_DuD 0 "FALSE" 1 "TRUE" ;
VAL_ 75 BGI3P_BrkPedPstnAuth_Inv 0 "FALSE" 1 "TRUE" ;
VAL_ 76 LatAccelAuth_Inv 0 "FALSE" 1 "TRUE" ;
VAL_ 76 LongAccelAuth_Inv 0 "FALSE" 1 "TRUE" ;
VAL_ 76 BGI3P_BrkPedModrTrvlAchAuth 0 "FALSE" 1 "TRUE" ;
VAL_ 76 BGI3P_BrkPedModrTrvlAchAuth_Inv 0 "FALSE" 1 "TRUE" ;
VAL_ 76 BGI3P_BrkPedInitTrvlAchAuth 0 "FALSE" 1 "TRUE" ;
VAL_ 76 BGI3P_BrkPedInitTrvlAchAuth_Inv 0 "FALSE" 1 "TRUE" ;
VAL_ 41 VCBA_FrtJnctnActv 0 "FALSE" 1 "TRUE" ;
VAL_ 41 VCBA_DynGdlnsActv 0 "FALSE" 1 "TRUE" ;
VAL_ 41 VCBA_CurbVwGdlnsActv 0 "FALSE" 1 "TRUE" ;
VAL_ 41 VCBA_CurbOvrhdActv 0 "FALSE" 1 "TRUE" ;
VAL_ 41 VCBA_CurbActv 0 "FALSE" 1 "TRUE" ;
VAL_ 41 VCBA_CrgBedActv 0 "FALSE" 1 "TRUE" ;
VAL_ 41 VCBA_BowlActv 0 "FALSE" 1 "TRUE" ;
VAL_ 41 VCBA_BedHtchActv 0 "FALSE" 1 "TRUE" ;
VAL_ 41 VCBA_RrOvrhdActv 0 "FALSE" 1 "TRUE" ;
VAL_ 41 VCBA_RrJnctnActv 0 "FALSE" 1 "TRUE" ;
VAL_ 41 VCBA_RrHtchActv 0 "FALSE" 1 "TRUE" ;
VAL_ 41 VCBA_LRTrlrTowMirActv 0 "FALSE" 1 "TRUE" ;
VAL_ 41 VCBA_JPActv 0 "FALSE" 1 "TRUE" ;
VAL_ 41 VCBA_InvsblTrlrActv 0 "FALSE" 1 "TRUE" ;
VAL_ 41 VCBA_FrtPrspctvActv 0 "FALSE" 1 "TRUE" ;
VAL_ 41 VCBA_FrtOvrhdActv 0 "FALSE" 1 "TRUE" ;
VAL_ 41 VCBA_TrlrTowMirActv 0 "FALSE" 1 "TRUE" ;
VAL_ 41 VCBA_TrlrGdlnsActv 0 "FALSE" 1 "TRUE" ;
VAL_ 41 VCBA_TrlrAux2Actv 0 "FALSE" 1 "TRUE" ;
VAL_ 41 VCBA_TrlrAux1CmbdActv 0 "FALSE" 1 "TRUE" ;
VAL_ 41 VCBA_TrlrAux1Actv 0 "FALSE" 1 "TRUE" ;
VAL_ 41 VCBA_SdRrwdActv 0 "FALSE" 1 "TRUE" ;
VAL_ 41 VCBA_SdFrwdActv 0 "FALSE" 1 "TRUE" ;
VAL_ 41 VCBA_RrPrspctvActv 0 "FALSE" 1 "TRUE" ;
VAL_ 41 VCBA_ZmdBowlActv 0 "FALSE" 1 "TRUE" ;
VAL_ 41 VCBA_TrnspHdActv 0 "FALSE" 1 "TRUE" ;
VAL_ 41 SrrndVsnRcrdrDelFileReqSts 0 "Unknown" 1 "File_1 Deleted" 2 "File_2 Deleted" 3 "File_3 Deleted" 4 "File_4 Deleted" 5 "File_5 Deleted" 6 "No Selection" 7 "Delete Failed" ;
VAL_ 41 SrrndVsnRcrdrVwprtSts 0 "Unknown" 1 "Playback Mosaic" 2 "Playback Zoom1" 3 "Playback Zoom2" 4 "Playback Zoom3" 5 "Playback Zoom4" 6 "List Recent" 7 "List Saved" ;
VAL_ 41 SrrndVsnRcrdrVwprtReq 0 "Unknown" 1 "Playback Mosaic" 2 "Playback Zoom1" 3 "Playback Zoom2" 4 "Playback Zoom3" 5 "Playback Zoom4" 6 "List Recent" 7 "List Saved" ;
VAL_ 41 SrrndVsnRcrdrPlybkSts 0 "Unknown" 1 "Play" 2 "Pause" 3 "Rewind" 4 "Fast Forward" 5 "No Selection" ;
VAL_ 41 SrrndVsnRcrdrRcrdSts 0 "Unknown" 1 "Enabled" 2 "Disabled" ;
VAL_ 41 SrrndVsnRcrdrListPgSts 0 "Unknown" 1 "Page Up" 2 "Page Down" 3 "No Selection" ;
VAL_ 41 VGVS_TrlrActv 0 "FALSE" 1 "TRUE" ;
VAL_ 41 VGVS_DynActv 0 "FALSE" 1 "TRUE" ;
VAL_ 41 VGVS_CurbVwActv 0 "FALSE" 1 "TRUE" ;
VAL_ 41 SrrndVsnRcrdrRcrdgActv 0 "FALSE" 1 "TRUE" ;
VAL_ 41 ClsnEvntDatRcrdgTrgrd 0 "FALSE" 1 "TRUE" ;
VAL_ 41 SVRCBA_PgUpActv 0 "FALSE" 1 "TRUE" ;
VAL_ 41 SVRCBA_PgDnActv 0 "FALSE" 1 "TRUE" ;
VAL_ 52 AATP_ActAxlTrqAuth_Inv 0 "FALSE" 1 "TRUE" ;
VAL_ 52 PrplSysMtrASpdAuth_Inv 0 "FALSE" 1 "TRUE" ;
VAL_ 52 TGI2P_TrnsOutShftAngVelAuth_Inv 0 "FALSE" 1 "TRUE" ;
VAL_ 52 EGIP_EngActlStdyStatTrqAuth_Inv 0 "FALSE" 1 "TRUE" ;
VAL_ 99 HstVehFrtRdWhlAng_Inv 0 "FALSE" 1 "TRUE" ;
VAL_ 99 ESP_EngSpdStAuth 0 "Normal_Operation" 1 "Degraded_Operation" 2 "Invalid" ;
VAL_ 43 DslGlwPlgIO 0 "FALSE" 1 "TRUE" ;
VAL_ 43 TSP_TmpDrvrShfCtlActvAuth 0 "FALSE" 1 "TRUE" ;
VAL_ 43 TSP_ElecRngSeltnInDrvActvAuth 0 "FALSE" 1 "TRUE" ;
VAL_ 705 VMI1P_AccelActlPstnAuth_Inv 0 "FALSE" 1 "TRUE" ;
VAL_ 705 LIB1StatOfChrg_Inv 0 "FALSE" 1 "TRUE" ;
VAL_ 705 VMI1P_VehTopSpdLimModeActvAuth 0 "FALSE" 1 "TRUE" ;
VAL_ 705 VMI1P_AccelPedOvrrdActvAuth 0 "FALSE" 1 "TRUE" ;
VAL_ 705 LIB1CellVltgFlt 0 "No Fault" 1 "Low Severity" 2 "Medium Severity" 3 "High Severity" ;
VAL_ 705 LIB1CellVltgFlt_Inv 0 "FALSE" 1 "TRUE" ;
VAL_ 1176 ClsnImntBrkgAxlTrqRqActvAuth 0 "FALSE" 1 "TRUE" ;
VAL_ 1176 ACCBRP_ReqActvAuth 0 "FALSE" 1 "TRUE" ;
VAL_ 1176 ACCBRP_ACCActvAuth 0 "FALSE" 1 "TRUE" ;
VAL_ 1176 ACCATRIP_TrqActvAuth 0 "FALSE" 1 "TRUE" ;
VAL_ 1176 DMSIP_DrvrAttnStatAuth_Inv 0 "FALSE" 1 "TRUE" ;
VAL_ 1176 PrkAsstCustSeltn 0 "Off" 1 "On" 2 "Failed" ;
VAL_ 1176 DMSIP_DrvrAttnStatAuth 0 "Unknown" 1 "Attention is On Road" 2 "Attention is Off Road" 3 "Attention is Driver's Lap" 4 "Attention is Center Console / Radio" 5 "Driver\???s Eyes Fully Closed" 6 "Driver Window / Mirror" 7 "Passenger Window / Mirror" 8 "Rear View Mirror" 9 "Overhead Console" 10 "No Driver" 11 "Front IPC" ;
VAL_ 1176 LCCPIP_LnCntrCtlAclPedLimRqAuth 0 "FALSE" 1 "TRUE" ;
VAL_ 701 AAASSRP_StrgReqStsAuth 0 "Unknown" 1 "Active" 2 "Inactive" ;
VAL_ 701 BGI1P_DrvrDrOpnStsAuth_Inv 0 "FALSE" 1 "TRUE" ;
VAL_ 701 BGI1P_DrvrDrOpnStsAuth_DuD 0 "FALSE" 1 "TRUE" ;
VAL_ 701 BGI1P_DrvrDrOpnStsAuth 0 "FALSE" 1 "TRUE" ;
VAL_ 701 EngCyldrDctvRqd 0 "FALSE" 1 "TRUE" ;
VAL_ 701 EngCylDctvMd 0 "All Cylinders Active" 1 "Deactivation In Progress" 2 "Half of Total Cylinders Active" 3 "Reactivation In Progress" ;
VAL_ 701 BGI1P_OutsdAmbtLgtLvlStsAuth 0 "Unknown" 1 "Day" 2 "Night" ;
VAL_ 115 SWIP_StrgWhlAngAuth_DuD 0 "FALSE" 1 "TRUE" ;
VAL_ 115 SWIP_StrgWhlAngCalStsAuth 0 "Unknown" 1 "Estimated" 2 "Calibrated" ;
VAL_ 115 SWIP_StrgWhlAngAuth_Inv 0 "FALSE" 1 "TRUE" ;
VAL_ 115 ElecPSTrqOvrlySts 0 "Unknown" 1 "Temporarily Inhibited" 2 "Inactive" 3 "Active" 4 "Temporarily Limited" 5 "Failed" ;
VAL_ 928 ADASAutoRsmChmEvntStat 0 "No Action" 1 "Active" 2 "Cancel Chime" ;
VAL_ 928 StBltRmndrChmTyp2EvntStat 0 "No_Action" 1 "Active" 2 "Cancel_Chime" ;
VAL_ 928 StBltRmndrChmEvntStat 0 "NO_ACTION" 1 "ACTIVE" 2 "CANCEL_CHIME" ;
VAL_ 928 BCMGI2_DrvrShtlModeCmnd 0 "FALSE" 1 "TRUE" ;
VAL_ 703 BVSCRP_CPSAxlTrqCmdReqStsAuth 0 "No Request" 1 "Request Honored" 2 "Lost Arbitration" 3 "Serial Data Failure Temporary" 4 "Serial Data Failure Permanent" 5 "Control System Failure Temporary" 6 "Control System Failure Permanent" ;
VAL_ 703 BVSCRP_CPSAxlTrqCmdLimStsAuth 0 "Request Not Limited" 1 "Request Value Limited to Minimum" 2 "Request Value Limited to Maximum" 3 "Request Rate Limited" ;
VAL_ 703 BVSCRP_ACCAxlTrqCmdReqStsAuth 0 "No Request" 1 "Request Honored" 2 "Lost Arbitration" 3 "Request Denied" 4 "Request Suspended Till Driver Input" ;
VAL_ 703 BVSCRP_ACCAxlTrqCmdLimStsAuth 0 "Request Not Limited" 1 "Request Value Limited Minimum" 2 "Request Value Limited Maximum" 3 "Request Rate Limited" ;
VAL_ 703 CruzCtlActvAuth 0 "FALSE" 1 "TRUE" ;
VAL_ 703 CnvntlCruzCtlIndReqAuth 0 "No Action" 1 "Cruise Control Telltale Off" 2 "Cruise Control Unavailable Telltale On" 3 "Cruise Control White Telltale On" 4 "Cruise Control Green Telltale On" 5 "Cruise Control Blue Telltale On" ;
VAL_ 703 BVSCRP_CruzCtlEnbldAuth 0 "FALSE" 1 "TRUE" ;
VAL_ 703 BVSCRP_CltchPdlActPosAuth_Inv 0 "FALSE" 1 "TRUE" ;
VAL_ 703 DrSeltdSpdLmtrSetSpdLimRchdAuth 0 "No Limit Reached" 1 "High Limit Reached" 2 "Low Limit Reached" 3 "Reserved" ;
VAL_ 703 DrSeltdSpdLmtrAutoMdSpLmStsAuth 0 "No Set Speed Change" 1 "Proposed Speed Limit Change" 2 "Accepted Speed Limit Change" 3 "Declined Speed Limit Change" ;
VAL_ 703 SpdLmtrSpdLimSgnUntAuth 0 "km/h" 1 "mph" ;
VAL_ 703 PABRP_VehTopSpdLimArbdStatAuth 0 "Torque" 1 "Torque & Friction Brake" 2 "Inactive" ;
VAL_ 703 EGI2P_PwrtrnCrnkActvAuth 0 "FALSE" 1 "TRUE" ;
VAL_ 703 DrSeltdSpdLmtrSetTypActvAuth 0 "Off" 1 "Manual" 2 "Auto" 3 "Reserved" ;
VAL_ 703 BrkPdlDrvAppPrsDetcdAuth 0 "FALSE" 1 "TRUE" ;
VAL_ 703 BrkPdlDrvAppPrsDetcdAuth_Inv 0 "FALSE" 1 "TRUE" ;
VAL_ 703 Bat12VCfg 0 "PbA Only" 1 "Li Only" 2 "Dual PbA" 3 "Dual Li" 4 "Dual Mix- PbA Primary" 5 "Dual Mix- Li Primary" 6 "Reserved" 7 "Unknown Batt Type" ;
VAL_ 703 ETRPP_ElcTransRngPriAuth 0 "NO_REQUEST" 1 "PARK" 2 "REVERSE" 3 "NEUTRAL" 4 "DRIVE" 5 "LOW_RANGE" 6 "MANUAL_RANGE" ;
VAL_ 703 BSIS2P_ABSFldAuth 0 "FALSE" 1 "TRUE" ;
VAL_ 703 BSIS2P_ABSAtvAuth 0 "FALSE" 1 "TRUE" ;
VAL_ 704 BSIS2P_BrkPdlDrvApplPresAuth_Inv 0 "FALSE" 1 "TRUE" ;
VAL_ 932 BdyCtlTopSpdLimSrcAuth 0 "None" 1 "Teen" 2 "Valet" 3 "HoodOpen" 4 "Reserved" 5 "Reserved" 6 "Reserved" 7 "Reserved" ;
VAL_ 932 BdyCtlTopSpdLimIndOnAuth 0 "FALSE" 1 "TRUE" ;
VAL_ 932 BdyCtlAccelLimIndOnAuth 0 "FALSE" 1 "TRUE" ;
VAL_ 932 CnvtTopModSpdLimIndOnAuth 0 "FALSE" 1 "TRUE" ;
VAL_ 932 DrvShftCntrlTrgtGr 0 "Unknown" 1 "First Gear" 2 "Second Gear" 3 "Third Gear" 4 "Fourth Gear" 5 "Fifth Gear" 6 "Sixth Gear" 7 "Seventh Gear" 8 "Eighth Gear" 9 "Ninth Gear" 10 "Tenth Gear" ;
VAL_ 932 DrvShftCntrlReqDndIO 0 "FALSE" 1 "TRUE" ;
VAL_ 932 TEGP_TrnsShftLvrPstnAuth_Inv 0 "FALSE" 1 "TRUE" ;
VAL_ 932 TEGP_TrnsEstGrAuth 0 "Not Supported" 1 "First Gear" 2 "Second Gear" 3 "Third Gear" 4 "Fourth Gear" 5 "Fifth Gear" 6 "Sixth Gear" 7 "Seventh Gear" 8 "Eighth Gear" 9 "Ninth Gear" 10 "Tenth Gear" 11 "Unused and Reserved" 12 "CVT Forward Gear" 13 "Neutral Gear" 14 "Reverse Gear" 15 "Park Gear" ;
VAL_ 932 TEGP_TrnsEstGrAuth_Inv 0 "FALSE" 1 "TRUE" ;
VAL_ 932 TrnsTUTDMdSt 0 "No Activation" 1 "Driver Shift Control Active" 2 "Electronic Range Select Active" ;
VAL_ 932 TEGP_TransCmndGrAuth 0 "Not Supported" 1 "First Gear" 2 "Second Gear" 3 "Third Gear" 4 "Fourth Gear" 5 "Fifth Gear" 6 "Sixth Gear" 7 "Seventh Gear" 8 "Eighth Gear" 9 "Ninth Gear" 10 "Tenth Gear" 11 "Unused and Reserved" 12 "CVT Forward Gear" 13 "Neutral Gear" 14 "Reverse Gear" 15 "Park Gear" ;
VAL_ 932 TEGP_TrnsShftLvrPstnAuth 0 "Between Ranges" 1 "Park Range" 2 "Reverse Range" 3 "Neutral Range" 4 "Forward Range A" 5 "Forward Range B" 6 "Forward Range C" 7 "Forward Range D" 8 "Forward Range E" 9 "Forward Range F" 10 "Forward Range G" 11 "Forward Range H" 12 "Forward Range I" 13 "Forward Range J" 14 "Lever Position Unknown" ;
VAL_ 933 TrnsRngInhbtSt 0 "No Range Inhibit Active" 1 "Transmission Inhibit Active" 2 "Transmission Range Re-Selection Req" 3 "Driveline Not Engaged" 4 "Diagnostic Inhibit Active" ;
VAL_ 933 TEGP_TrnsEngdStAuth 0 "Transmission Not Engaged" 1 "Transmission Engaged in Forward" 2 "Transmission Engaged in Reverse" 3 "Operating State Not Reached" ;
VAL_ 933 TEGP_TrnsEngdStAuth_Inv 0 "FALSE" 1 "TRUE" ;
VAL_ 933 HiVltgBatOutOfEngyIndReq 0 "No Action" 1 "Charge Soon" 2 "Charge Now" 3 "Out of Energy" 4 "Start Engine" ;
VAL_ 933 DrvrElecVehModeCmnd 0 "FALSE" 1 "TRUE" ;
VAL_ 933 EASSI_StrtStpSt 0 "Engine Off" 1 "Engine Running" 2 "Engine Starting" 3 "Engine Stopping" ;
VAL_ 934 BSISP_TCSDrvrIntntAuth 0 "Disabled" 1 "Enabled" ;
VAL_ 934 BSISP_TCSActvAuth 0 "FALSE" 1 "TRUE" ;
VAL_ 934 BSISP_ETRSHydrlcBrkgStsAuth 0 "Not Active" 1 "Active" 2 "Failed" ;
VAL_ 934 BSISP_ESCSysStsAuth 0 "Normal Operation" 1 "Failed" 2 "Initializing" 3 "Enhanced Operation" 4 "Driver Disable" ;
VAL_ 934 BSISP_ESCActvAuth 0 "FALSE" 1 "TRUE" ;
VAL_ 934 HstVehTrlrDtd 0 "Unknown" 1 "Trailer Not Detected" 2 "Trailer Detected" 3 "Unsupported Trailer Detected" ;
VAL_ 934 BrkgSysVehTopSpdLimIndOnAuth 0 "FALSE" 1 "TRUE" ;
VAL_ 934 BSISP_TCSFaildAuth 0 "FALSE" 1 "TRUE" ;
VAL_ 718 HVBSOC_BatSOC_Inv 0 "FALSE" 1 "TRUE" ;
VAL_ 718 HVBI_BatPackPrcdVltg_DuD 0 "FALSE" 1 "TRUE" ;
VAL_ 718 HVBI_BatPackPrcdVltg_Inv 0 "FALSE" 1 "TRUE" ;
VAL_ 718 VAP_ActlVehAccelAuth_Inv 0 "FALSE" 1 "TRUE" ;
VAL_ 718 PrplDispEngTrq_Inv 0 "FALSE" 1 "TRUE" ;
VAL_ 718 PrplDispEngTrq_DuD 0 "FALSE" 1 "TRUE" ;
VAL_ 718 MemIdfrMemStorIndReq 0 "No Action" 1 "Driver 1" 2 "Driver 2" 3 "Driver 3" 4 "Driver 4" 5 "Driver 5" 6 "Driver 6" 7 "Driver 7" 8 "Driver 8" ;
VAL_ 681 EngBstPrsInd_Inv 0 "FALSE" 1 "TRUE" ;
VAL_ 681 ThrPstn_Inv 0 "FALSE" 1 "TRUE" ;
VAL_ 681 EngPrplDispTrqLvlPct_DuD 0 "FALSE" 1 "TRUE" ;
VAL_ 681 TrnsTrqCnvCltCmdMd 0 "Unlocked" 1 "Transitioning" 2 "Controlled Slip" 3 "Locked" 4 "Not Supported" ;
VAL_ 681 PrkLmpsAct 0 "FALSE" 1 "TRUE" ;
VAL_ 681 WRDSP_LRAuth 0 "Unknown" 1 "Not Supported" 2 "Invalid" 3 "Forward" 4 "Reverse" ;
VAL_ 681 WRDSP_LFAuth 0 "Unknown" 1 "Not Supported" 2 "Invalid" 3 "Forward" 4 "Reverse" ;
VAL_ 719 WRDSP_RRAuth 0 "Unknown" 1 "Not Supported" 2 "Invalid" 3 "Forward" 4 "Reverse" ;
VAL_ 719 WRDSP_RFAuth 0 "Unknown" 1 "Not Supported" 2 "Invalid" 3 "Forward" 4 "Reverse" ;
VAL_ 719 VSANDP_VehSpdAvgNDrvnAuth_Inv 0 "FALSE" 1 "TRUE" ;
VAL_ 719 DRCDNDP_DRCAvgDrvnSrcAuth 0 "Transmission Output Speed" 1 "Wheel Speed" ;
VAL_ 719 DRCDNDP_DRCAvgDrvnRstOccAuth 0 "FALSE" 1 "TRUE" ;
VAL_ 719 DRCDNDP_DRCAvgDrvnAuth_Inv 0 "FALSE" 1 "TRUE" ;
VAL_ 719 SSID1P_LatAccelAuth_Inv 0 "FALSE" 1 "TRUE" ;
VAL_ 719 DRCDNDP_DRCAvgNonDrvnRstOccAuth 0 "FALSE" 1 "TRUE" ;
VAL_ 719 DRCDNDP_DRCAvgNonDrvnAuth_Inv 0 "FALSE" 1 "TRUE" ;
VAL_ 936 RdWhlAng_Inv 0 "FALSE" 1 "TRUE" ;
VAL_ 936 VehPtchAng_Inv 0 "FALSE" 1 "TRUE" ;
VAL_ 936 VehRollAng_Inv 0 "FALSE" 1 "TRUE" ;
VAL_ 937 AFLHiBmsOtgIndOn 0 "FALSE" 1 "TRUE" ;
VAL_ 937 AFLCkLoBmsIndOn 0 "FALSE" 1 "TRUE" ;
VAL_ 938 EngOilPrs_Inv 0 "FALSE" 1 "TRUE" ;
VAL_ 1407 APACR_SptFndChmEvntStat 0 "NO_ACTION" 1 "ACTIVE" 2 "CANCEL_CHIME" ;
VAL_ 1407 APACR_FaildChmEvntStat 0 "NO_ACTION" 1 "ACTIVE" 2 "CANCEL_CHIME" ;
VAL_ 1407 APACR_CncldChmEvntStat 0 "NO_ACTION" 1 "ACTIVE" 2 "CANCEL_CHIME" ;
VAL_ 1407 APACR_CmpltChmEvntStat 0 "NO_ACTION" 1 "ACTIVE" 2 "CANCEL_CHIME" ;
VAL_ 1407 APACR_StopChmEvntStat 0 "NO_ACTION" 1 "ACTIVE" 2 "CANCEL_CHIME" ;
VAL_ 1407 ELWWIP_WprFrtFtrReqAuth 0 "Wiper Front Stop" 1 "Wiper Front Crank Suspend" 2 "Wiper Front Depressed Park" 3 "Wiper Front Park" 4 "Wiper Front Winter Park" 5 "Wiper Front Service Park" 6 "Wiper Front Intermittent 5" 7 "Wiper Front Intermittent 4" 8 "Wiper Front Intermittent 3" 9 "Wiper Front Intermittent 2" 10 "Wiper Front Intermittent 1" 11 "Wiper Front Low Wipe" 12 "Wiper Front High Wipe" ;
VAL_ 1407 LnCntrWrnIndRqst 0 "No Indication" 1 "Can not See Lanes" 2 "Tight Curve" 3 "Freeway Ends" 4 "Construction" 5 "Excessive Speed" 6 "Vehicles Too Close" 7 "Canceled Take Steering" 8 "Can not See Eyes" 9 "Due to Weather" 10 "Take Steering" 11 "Take Vehicle Control" 12 "Service Driver Assist System" 13 "Lane Following Locked Out" 14 "TJA Max Speed Reached" 15 "TJA Available" 16 "TJA Active" ;
VAL_ 1407 ELWWIP_BrkLmpLtCmdAuth 0 "No_Action" 1 "Off" 2 "On" 3 "Emergency_Brake_Flashing" 4 "Police_Flashing" ;
VAL_ 1407 LKALnMrkgIndLt 0 "Off" 1 "White" 2 "Green" 3 "Amber" 4 "Amber Flashing" ;
VAL_ 1407 FrntPsSeatbeltStat 0 "Unknown" 1 "Unfastened" 2 "Fastened" ;
VAL_ 1407 FrntPsSeatbeltStat_Inv 0 "FALSE" 1 "TRUE" ;
VAL_ 1407 ELWWIP_BrkLmpRtCmdAuth 0 "No_Action" 1 "Off" 2 "On" 3 "Emergency_Brake_Flashing" 4 "Police_Flashing" ;
VAL_ 1407 ORIP_DrvrStBltSts1Auth_Inv 0 "FALSE" 1 "TRUE" ;
VAL_ 1407 LnDtWrnCntrlVsAlrtCmdGnc 0 "OFF" 1 "NOT READY TO ASSIST" 2 "READY TO ASSIST" 3 "ALERT" 4 "INTERVENTION" ;
VAL_ 1407 LKALnMrkgIndRt 0 "Off" 1 "White" 2 "Green" 3 "Amber" 4 "Amber Flashing" ;
VAL_ 1407 AdpLghtRspTypCstAvlFlg4 0 "FALSE" 1 "TRUE" ;
VAL_ 1407 MltpPsStBtRmndrChmEvntStat 0 "No Action" 1 "Active" 2 "Cancel Chime" ;
VAL_ 1407 RrPCMRspTypCstCrStVal 0 "SETTING_UNKNOWN" 1 "OFF" 2 "ALERT" 3 "ALERT_AND_BRAKE" 4 "RESERVED_4 RESERVED_5" 5 "RESERVED_6" 6 "RESERVED_7" ;
VAL_ 1407 ORIP_DrvrStBltSts1Auth 0 "Unknown" 1 "UnFastened" 2 "Fastened" ;
VAL_ 1408 ElecPrkBrkCtnChiEveStat 0 "NO_ACTION" 1 "ACTIVE" 2 "CANCEL_CHIME" ;
VAL_ 1408 ELWWIP_TrlrRvrsLmpsCmdAuth 0 "Off" 1 "On" 2 "Flashing" ;
VAL_ 1408 ELWWIP_RvrsLmpCmdAuth 0 "Off" 1 "On" 2 "Flashing" ;
VAL_ 1408 ELWWIP_CHMSLCmdAuth 0 "No_Action" 1 "Off" 2 "On" 3 "Emergency_Brake_Flashing" ;
VAL_ 1408 LDWCtrlHndOff1ChmEvntStat 0 "NO_ACTION" 1 "ACTIVE" 2 "CANCEL_CHIME" ;
VAL_ 1408 FrwdCllsnAlrtImAlrtDrIntAlrtChmE 0 "NO_ACTION" 1 "ACTIVE" 2 "CANCEL_CHIME" ;
VAL_ 1408 FrntPCMChmEvntStat 0 "NO_ACTION" 1 "ACTIVE" 2 "CANCEL_CHIME" ;
VAL_ 1408 ElecPrkBrkFixDurChiEveStat 0 "NO_ACTION" 1 "ACTIVE" 2 "CANCEL_CHIME" ;
VAL_ 1408 LDWCtrlRtHndSdChmEvntStat 0 "NO_ACTION" 1 "ACTIVE" 2 "CANCEL_CHIME" ;
VAL_ 1408 LDWCtrlLtHndSdChmEvntStat 0 "NO_ACTION" 1 "ACTIVE" 2 "CANCEL_CHIME" ;
VAL_ 1408 LDWCtrlHndOff3ChmEvntStat 0 "NO_ACTION" 1 "ACTIVE" 2 "CANCEL_CHIME" ;
VAL_ 1408 LDWCtrlHndOff2ChmEvntStat 0 "NO_ACTION" 1 "ACTIVE" 2 "CANCEL_CHIME" ;
VAL_ 1408 MemStrDblBeepChmEvStRR 0 "No Action" 1 "Active" 2 "Cancel Chime" ;
VAL_ 1408 MemStrDblBeepChmEvStLR 0 "No Action" 1 "Active" 2 "Cancel Chime" ;
VAL_ 1408 MemStrDblBeepChmEvStDrv 0 "No Action" 1 "Active" 2 "Cancel Chime" ;
VAL_ 1408 MemStrDblBeepChmEvStCoDrv 0 "No Action" 1 "Active" 2 "Cancel Chime" ;
VAL_ 1408 MemStrSnglBeepChmEvStRR 0 "No Action" 1 "Active" 2 "Cancel Chime" ;
VAL_ 1408 MemStrSnglBeepChmEvStLR 0 "No Action" 1 "Active" 2 "Cancel Chime" ;
VAL_ 1408 MemStrSnglBeepChmEvStDrv 0 "No Action" 1 "Active" 2 "Cancel Chime" ;
VAL_ 1408 MemStrSnglBeepChmEvStCoDrv 0 "No Action" 1 "Active" 2 "Cancel Chime" ;
VAL_ 1408 MemStrTrplBeepChmEvStRR 0 "No Action" 1 "Active" 2 "Cancel Chime" ;
VAL_ 1408 MemStrTrplBeepChmEvStLR 0 "No Action" 1 "Active" 2 "Cancel Chime" ;
VAL_ 1408 MemStrTrplBeepChmEvStDrv 0 "No Action" 1 "Active" 2 "Cancel Chime" ;
VAL_ 1408 MemStrTrplBeepChmEvStCoDrv 0 "No Action" 1 "Active" 2 "Cancel Chime" ;
VAL_ 1408 PrkAsstFllFrZn2ChEvntSt 0 "NO_ACTION" 1 "ACTIVE" 2 "CANCEL_CHIME" ;
VAL_ 1408 PrkAsstFllFrZn1ChEvntSt 0 "NO_ACTION" 1 "ACTIVE" 2 "CANCEL_CHIME" ;
VAL_ 1408 PrkAsstFlChEvntSt 0 "NO_ACTION" 1 "ACTIVE" 2 "CANCEL_CHIME" ;
VAL_ 1408 PAMutSts 0 "No Action" 1 "Show Mute" 2 "Show Unmute" ;
VAL_ 1408 PrkAsstFllFrZn6ChEvntSt 0 "NO_ACTION" 1 "ACTIVE" 2 "CANCEL_CHIME" ;
VAL_ 1408 PrkAsstFllFrZn5ChEvntSt 0 "NO_ACTION" 1 "ACTIVE" 2 "CANCEL_CHIME" ;
VAL_ 1408 PrkAsstFllFrZn4ChEvntSt 0 "NO_ACTION" 1 "ACTIVE" 2 "CANCEL_CHIME" ;
VAL_ 1408 PrkAsstFllFrZn3ChEvntSt 0 "NO_ACTION" 1 "ACTIVE" 2 "CANCEL_CHIME" ;
VAL_ 1409 PrkAsstFllRrZn4ChEvntSt 0 "NO_ACTION" 1 "ACTIVE" 2 "CANCEL_CHIME" ;
VAL_ 1409 PrkAsstFllRrZn3ChEvntSt 0 "NO_ACTION" 1 "ACTIVE" 2 "CANCEL_CHIME" ;
VAL_ 1409 PrkAsstFllRrZn2ChEvntSt 0 "NO_ACTION" 1 "ACTIVE" 2 "CANCEL_CHIME" ;
VAL_ 1409 PrkAsstFllRrZn1ChEvntSt 0 "NO_ACTION" 1 "ACTIVE" 2 "CANCEL_CHIME" ;
VAL_ 1409 PrkAsstFrLftSdZn1ChEvntSt 0 "NO_ACTION" 1 "ACTIVE" 2 "CANCEL_CHIME" ;
VAL_ 1409 PrkAsstFrFrstRprtChEvntSt 0 "NO_ACTION" 1 "ACTIVE" 2 "CANCEL_CHIME" ;
VAL_ 1409 PrkAsstFllRrZn6ChEvntSt 0 "NO_ACTION" 1 "ACTIVE" 2 "CANCEL_CHIME" ;
VAL_ 1409 PrkAsstFllRrZn5ChEvntSt 0 "NO_ACTION" 1 "ACTIVE" 2 "CANCEL_CHIME" ;
VAL_ 1409 PrkAsstFrLftSdZn5ChEvntSt 0 "NO_ACTION" 1 "ACTIVE" 2 "CANCEL_CHIME" ;
VAL_ 1409 PrkAsstFrLftSdZn4ChEvntSt 0 "NO_ACTION" 1 "ACTIVE" 2 "CANCEL_CHIME" ;
VAL_ 1409 PrkAsstFrLftSdZn3ChEvntSt 0 "NO_ACTION" 1 "ACTIVE" 2 "CANCEL_CHIME" ;
VAL_ 1409 PrkAsstFrLftSdZn2ChEvntSt 0 "NO_ACTION" 1 "ACTIVE" 2 "CANCEL_CHIME" ;
VAL_ 1409 PrkAsstFrRghtSdZn3ChEvntSt 0 "NO_ACTION" 1 "ACTIVE" 2 "CANCEL_CHIME" ;
VAL_ 1409 PrkAsstFrRghtSdZn2ChEvntSt 0 "NO_ACTION" 1 "ACTIVE" 2 "CANCEL_CHIME" ;
VAL_ 1409 PrkAsstFrRghtSdZn1ChEvntSt 0 "NO_ACTION" 1 "ACTIVE" 2 "CANCEL_CHIME" ;
VAL_ 1409 PrkAsstFrLftSdZn6ChEvntSt 0 "NO_ACTION" 1 "ACTIVE" 2 "CANCEL_CHIME" ;
VAL_ 1409 PrkAsstFrRgrChEvntSt 0 "NO_ACTION" 1 "ACTIVE" 2 "CANCEL_CHIME" ;
VAL_ 1409 PrkAsstFrRghtSdZn6ChEvntSt 0 "NO_ACTION" 1 "ACTIVE" 2 "CANCEL_CHIME" ;
VAL_ 1409 PrkAsstFrRghtSdZn5ChEvntSt 0 "NO_ACTION" 1 "ACTIVE" 2 "CANCEL_CHIME" ;
VAL_ 1409 PrkAsstFrRghtSdZn4ChEvntSt 0 "NO_ACTION" 1 "ACTIVE" 2 "CANCEL_CHIME" ;
VAL_ 1409 PrkAsstRrLftSdZn3ChEvntSt 0 "NO_ACTION" 1 "ACTIVE" 2 "CANCEL_CHIME" ;
VAL_ 1409 PrkAsstRrLftSdZn2ChEvntSt 0 "NO_ACTION" 1 "ACTIVE" 2 "CANCEL_CHIME" ;
VAL_ 1409 PrkAsstRrLftSdZn1ChEvntSt 0 "NO_ACTION" 1 "ACTIVE" 2 "CANCEL_CHIME" ;
VAL_ 1409 PrkAsstRrFrstRprtChEvntSt 0 "NO_ACTION" 1 "ACTIVE" 2 "CANCEL_CHIME" ;
VAL_ 1409 PrkAsstRrRghtSdZn1ChEvntSt 0 "NO_ACTION" 1 "ACTIVE" 2 "CANCEL_CHIME" ;
VAL_ 1409 PrkAsstRrLftSdZn6ChEvntSt 0 "NO_ACTION" 1 "ACTIVE" 2 "CANCEL_CHIME" ;
VAL_ 1409 PrkAsstRrLftSdZn5ChEvntSt 0 "NO_ACTION" 1 "ACTIVE" 2 "CANCEL_CHIME" ;
VAL_ 1409 PrkAsstRrLftSdZn4ChEvntSt 0 "NO_ACTION" 1 "ACTIVE" 2 "CANCEL_CHIME" ;
VAL_ 1409 PrkAsstRrRghtSdZn5ChEvntSt 0 "NO_ACTION" 1 "ACTIVE" 2 "CANCEL_CHIME" ;
VAL_ 1409 PrkAsstRrRghtSdZn4ChEvntSt 0 "NO_ACTION" 1 "ACTIVE" 2 "CANCEL_CHIME" ;
VAL_ 1409 PrkAsstRrRghtSdZn3ChEvntSt 0 "NO_ACTION" 1 "ACTIVE" 2 "CANCEL_CHIME" ;
VAL_ 1409 PrkAsstRrRghtSdZn2ChEvntSt 0 "NO_ACTION" 1 "ACTIVE" 2 "CANCEL_CHIME" ;
VAL_ 1410 PwrSdClsrLRObstclChmEvntStat 0 "No_Action" 1 "Active" 2 "Cancel_Chime" ;
VAL_ 1410 PwrSdClsrLFObstclChmEvntStat 0 "No_Action" 1 "Active" 2 "Cancel_Chime" ;
VAL_ 1410 PrkAsstRrRgrChEvntSt 0 "NO_ACTION" 1 "ACTIVE" 2 "CANCEL_CHIME" ;
VAL_ 1410 PrkAsstRrRghtSdZn6ChEvntSt 0 "NO_ACTION" 1 "ACTIVE" 2 "CANCEL_CHIME" ;
VAL_ 1410 PwrSdSldClsrLFRmtActChmEvntStat 0 "No_Action" 1 "Active" 2 "Cancel_Chime" ;
VAL_ 1410 PwrSdSldClsrLFLclActChmEvntStat 0 "No_Action" 1 "Active" 2 "Cancel_Chime" ;
VAL_ 1410 PwrSdClsrRRObstclChmEvntStat 0 "No_Action" 1 "Active" 2 "Cancel_Chime" ;
VAL_ 1410 PwrSdClsrRFObstclChmEvntStat 0 "No_Action" 1 "Active" 2 "Cancel_Chime" ;
VAL_ 1410 PwrSdSldClsrRFRmtActChmEvntStat 0 "No_Action" 1 "Active" 2 "Cancel_Chime" ;
VAL_ 1410 PwrSdSldClsrRFLclActChmEvntStat 0 "No_Action" 1 "Active" 2 "Cancel_Chime" ;
VAL_ 1410 PwrSdSldClsrLRRmtActChmEvntStat 0 "No_Action" 1 "Active" 2 "Cancel_Chime" ;
VAL_ 1410 PwrSdSldClsrLRLclActChmEvntStat 0 "No_Action" 1 "Active" 2 "Cancel_Chime" ;
VAL_ 1410 PwrSdSwgClsrLFRmtActChmEvntStat 0 "No_Action" 1 "Active" 2 "Cancel_Chime" ;
VAL_ 1410 PwrSdSwgClsrLFLclActChmEvntStat 0 "No_Action" 1 "Active" 2 "Cancel_Chime" ;
VAL_ 1410 PwrSdSldClsrRRRmtActChmEvntStat 0 "No_Action" 1 "Active" 2 "Cancel_Chime" ;
VAL_ 1410 PwrSdSldClsrRRLclActChmEvntStat 0 "No_Action" 1 "Active" 2 "Cancel_Chime" ;
VAL_ 1410 PwrSdSwgClsrRFRmtActChmEvntStat 0 "No_Action" 1 "Active" 2 "Cancel_Chime" ;
VAL_ 1410 PwrSdSwgClsrRFLclActChmEvntStat 0 "No_Action" 1 "Active" 2 "Cancel_Chime" ;
VAL_ 1410 PwrSdSwgClsrLRRmtActChmEvntStat 0 "No_Action" 1 "Active" 2 "Cancel_Chime" ;
VAL_ 1410 PwrSdSwgClsrLRLclActChmEvntStat 0 "No_Action" 1 "Active" 2 "Cancel_Chime" ;
VAL_ 1410 RIMIntCllnChmEvStat 0 "NO_ACTION" 1 "ACTIVE" 2 "CANCEL_CHIM" ;
VAL_ 1410 RIMBrkPlsChEvStat 0 "NO_ACTION" 1 "ACTIVE" 2 "CANCEL_CHIM" ;
VAL_ 1410 PwrSdSwgClsrRRRmtActChmEvntStat 0 "No_Action" 1 "Active" 2 "Cancel_Chime" ;
VAL_ 1410 PwrSdSwgClsrRRLclActChmEvntStat 0 "No_Action" 1 "Active" 2 "Cancel_Chime" ;
VAL_ 1410 WlkAwyLkInhbtChmEvSt 0 "NO_ACTION" 1 "ACTIVE" 2 "CANCEL_CHIME" ;
VAL_ 1410 RrPCMChmEvntSt 0 "NO_ACTION" 1 "ACTIVE" 2 "CANCEL_CHIME" ;
VAL_ 1410 RlOvrDsblStsChgChmEvntStat 0 "No_Action" 1 "Active" 2 "Cancel_Chime" ;
VAL_ 1410 AutMemRclCstAvlFlg5 0 "FALSE" 1 "TRUE" ;
VAL_ 1410 AutMemRclCstAvlFlg4 0 "FALSE" 1 "TRUE" ;
VAL_ 1410 AutMemRclCstAvlFlg3 0 "FALSE" 1 "TRUE" ;
VAL_ 1410 AutMemRclCstAvlFlg2 0 "FALSE" 1 "TRUE" ;
VAL_ 1410 AutMemRclCstAvlFlg1 0 "FALSE" 1 "TRUE" ;
VAL_ 1410 AdpLghtRspTypCstAvlFlg7 0 "FALSE" 1 "TRUE" ;
VAL_ 1410 AdpLghtRspTypCstAvlFlg6 0 "FALSE" 1 "TRUE" ;
VAL_ 1410 AdpLghtRspTypCstAvlFlg5 0 "FALSE" 1 "TRUE" ;
VAL_ 1411 EsyExtCstAvlFlg5 0 "FALSE" 1 "TRUE" ;
VAL_ 1411 EsyExtCstAvlFlg4 0 "FALSE" 1 "TRUE" ;
VAL_ 1411 EsyExtCstAvlFlg3 0 "FALSE" 1 "TRUE" ;
VAL_ 1411 EsyExtCstAvlFlg2 0 "FALSE" 1 "TRUE" ;
VAL_ 1411 EsyExtCstAvlFlg1 0 "FALSE" 1 "TRUE" ;
VAL_ 1411 EngIdlAtv 0 "FALSE" 1 "TRUE" ;
VAL_ 1411 AutMemRclCstAvlFlg7 0 "FALSE" 1 "TRUE" ;
VAL_ 1411 AutMemRclCstAvlFlg6 0 "FALSE" 1 "TRUE" ;
VAL_ 1411 RrPCMRspTypCstAvlFlg2 0 "FALSE" 1 "TRUE" ;
VAL_ 1411 RrPCMRspTypCstAvlFlg1 0 "FALSE" 1 "TRUE" ;
VAL_ 1411 LowBmAct 0 "FALSE" 1 "TRUE" ;
VAL_ 1411 LDWCtrlAudAttnReqd 0 "FALSE" 1 "TRUE" ;
VAL_ 1411 HighBmAct 0 "FALSE" 1 "TRUE" ;
VAL_ 1411 FlToPsSwAtv 0 "FALSE" 1 "TRUE" ;
VAL_ 1411 EsyExtCstAvlFlg7 0 "FALSE" 1 "TRUE" ;
VAL_ 1411 EsyExtCstAvlFlg6 0 "FALSE" 1 "TRUE" ;
VAL_ 1411 TrlrConnStat 0 "Not Connected" 1 "Connected" ;
VAL_ 1411 StrgLckd 0 "FALSE" 1 "TRUE" ;
VAL_ 1411 RrPCMRspTypCstStAvl 0 "FALSE" 1 "TRUE" ;
VAL_ 1411 RrPCMRspTypCstAvlFlg7 0 "FALSE" 1 "TRUE" ;
VAL_ 1411 RrPCMRspTypCstAvlFlg6 0 "FALSE" 1 "TRUE" ;
VAL_ 1411 RrPCMRspTypCstAvlFlg5 0 "FALSE" 1 "TRUE" ;
VAL_ 1411 RrPCMRspTypCstAvlFlg4 0 "FALSE" 1 "TRUE" ;
VAL_ 1411 RrPCMRspTypCstAvlFlg3 0 "FALSE" 1 "TRUE" ;
VAL_ 1411 PwrRrClsrMtnSts 0 "Unknown" 1 "Closed" 2 "Opening" 3 "Closing" 4 "Stopped - Normal" 5 "Stopped - Obstacle" 6 "Closing - Hold System Fault" 7 "Fully Opened" 8 "Opening due to Obstacle" 9 "Closing due to Obstacle" ;
VAL_ 1411 TrnLmpRtIO 0 "FALSE" 1 "TRUE" ;
VAL_ 1411 TrnLmpLftIO 0 "FALSE" 1 "TRUE" ;
VAL_ 1411 IndHtdArmrstLvlFrtLt 0 "Off" 1 "1" 2 "2" 3 "3" 4 "Linked" ;
VAL_ 1411 IndHtdArmrstLvlRrLt 0 "Off" 1 "1" 2 "2" 3 "3" 4 "Linked" ;
VAL_ 1411 IndHtdArmrstLvlFrtRt 0 "Off" 1 "1" 2 "2" 3 "3" 4 "Linked" ;
VAL_ 1480 SLVFSP_SpdLimVsnFsdSpdUntAuth 0 "km/h" 1 "mph" ;
VAL_ 1481 LFSCDS_CshLgAdjFdRr 0 "Not Selected" 1 "Selected-No Movement" 2 "Forward" 3 "Rearward" ;
VAL_ 1481 LFSCDS_CshBlstrInOut 0 "Not Selected" 1 "Selected-No Movement" 2 "In" 3 "Out" ;
VAL_ 1481 LFSCDS_BkCshBlstInOt 0 "Not Selected" 1 "Selected-No Movement" 2 "Back Bolster In" 3 "Back Bolster Out" 4 "Cushion Bolster In" 5 "Cushion Bolster Out" ;
VAL_ 1481 LFSCDS_BkBlstrInOut 0 "Not Selected" 1 "Selected-No Movement" 2 "In" 3 "Out" ;
VAL_ 1481 LFSCDS_HdrstTltFwdRr 0 "Not Selected" 1 "Selected-No Movement" 2 "Forward" 3 "Rearward" ;
VAL_ 1481 LFSCDS_HdrstFwdRrwd 0 "Not Selected" 1 "Selected-No Movement" 2 "Forward" 3 "Rearward" ;
VAL_ 1481 LFSCDS_HdrstFdRrUDn 0 "Not Selected" 1 "Selected-No Movement" 2 "Up" 3 "Down" 4 "Forward" 5 "Rearward" ;
VAL_ 1481 LFSCDS_DispReq 0 "FALSE" 1 "TRUE" ;
VAL_ 1481 LFSCDS_LmbrUDnFdRr 0 "Not Selected" 1 "Selected-No Movement" 2 "Up" 3 "Down" 4 "Forward" 5 "Rearward" ;
VAL_ 1481 LFSCDS_LmbrFwdRr 0 "Not Selected" 1 "Selected-No Movement" 2 "Forward" 3 "Rearward" ;
VAL_ 1481 LFSCDS_HdrstWngInOt 0 "Not Selected" 1 "Selected-No Movement" 2 "In" 3 "Out" ;
VAL_ 1481 LFSCDS_HdrstUpDn 0 "Not Selected" 1 "Selected-No Movement" 2 "Up" 3 "Down" ;
VAL_ 1481 LFSCDS_MassgIntsty 0 "Massage Off" 1 "Massage Intensity 1" 2 "Massage Intensity 2" 3 "Massage Intensity 3" 4 "Massage Intensity 4" 5 "Massage Intensity 5" 6 "Massage Intensity 6" 7 "Massage Intensity 7" ;
VAL_ 1481 LFSCDS_Massg 0 "Not Selected" 1 "Selected Massage Off" 2 "Selected Massage On" ;
VAL_ 1481 LFSCDS_LmbrUpDwn 0 "Not Selected" 1 "Selected-No Movement" 2 "Up" 3 "Down" ;
VAL_ 1481 APAWI_AutoStrgIconReq 0 "NO_ICON" 1 "ACTIVE" 2 "DEACTIVATED" ;
VAL_ 1481 LFSCDS_UprShldrFdRr 0 "Not Selected" 1 "Selected-No Movement" 2 "Forward" 3 "Rearward" ;
VAL_ 1481 LFSCDS_MassgTyp 0 "Massage Off" 1 "Massage Type 1" 2 "Massage Type 2" 3 "Massage Type 3" 4 "Massage Type 4" 5 "Massage Type 5" 6 "Massage Type 6" 7 "Massage Type 7" 8 "Massage Type 8" 9 "Massage Type 9" 10 "Massage Type 10" 11 "Massage Type 11" 12 "Massage Type 12" 13 "Massage Type 13" 14 "Massage Type 14" 15 "Massage Type 15" ;
VAL_ 1481 APAWI_FcsReq 0 "NO_REQUEST" 1 "FOCUS_REQUEST_IPC" 2 "FOCUS_REQUEST_CSM" ;
VAL_ 1481 AdpLghtRspTypCstStAvl 0 "FALSE" 1 "TRUE" ;
VAL_ 1481 APAWI_WrnIndReq 0 "OFF" 1 "SEARCHING_PARALLEL_RIGHT" 2 "SEARCHING_PARALLEL_LEFT" 3 "SEARCHING_CROSS_RIGHT" 4 "SEARCHING_CROSS_LEFT" 5 "SPOT_FOUND" 6 "SPOT_FOUND_PARALLEL_LEFT" 7 "SPOT_FOUND_CROSS_LEFT" 8 "SPOT_FOUND_PARALLEL_RIGHT" 9 "SPOT_FOUND_CROSS_RIGHT" 10 "MOVE_AHEAD" 11 "MOVE_AHEAD_PARALLEL_LEFT" 12 "MOVE_AHEAD_CROSS_LEFT" 13 "MOVE_AHEAD_PARALLEL_RIGHT" 14 "MOVE_AHEAD_CROSS_RIGHT" 15 "STOP_AND_R_PARALLEL_LEFT" 16 "STOP_AND_R_CROSS_BACK_LEFT" 17 "STOP_AND_R_CROSS_FRONT_LEFT" 18 "STOP_AND_R_PARALLEL_RIGHT" 19 "STOP_AND_R_CROSS_BACK_RIGHT" 20 "STOP_AND_R_CROSS_FRONT_RIGHT" 21 "SEARCH_SPEED_WARNING" 22 "SEARCH_DEACTIVATED" 23 "EXIT_PARK_TO_LEFT" 24 "EXIT_PARK_TO_RIGHT" 25 "SELECT_DRIVE_GEAR" 26 "AUTO_STEERING_ACTIVE" 27 "AUTO_PARKING_ACTIVE" 28 "DRIVE_BACKWARD" 29 "BACKWARD_MOVE" 30 "DRIVE_FORWARD" 31 "FORWARD_MOVE" 32 "STOP" 33 "SHIFTING" 34 "POSITION_REACHED" 35 "TAKE_CONTROL" 36 "PARKING_COMPLETE" 37 "EXIT_PARK_COMPLETE" 38 "DEACTIVATED" 39 "CANCELED_GENERAL" 40 "CANCELED_MOVES" 41 "CANCELED_SPEED" 42 "CANCELED_INTERFERENCE" 43 "CANCELED_EXIT_PARK" 44 "STOPPING" 45 "AUTO_PARKING_COMPLETE" 46 "RELEASE_BRAKE" 47 "IN_VEHICLE_OR_REMOTE" 48 "REMOTE_STAY_ALERT" 49 "REMOTE_CONNECTING" 50 "REMOTE_CANNOT_CONNECT" 51 "REMOTE_NO_DEVICE" 52 "REMOTE_SHIFT_TO_PARK" 53 "REMOTE_RETRY" 54 "REMOTE_CANCELED_RANGE" 55 "REMOTE_CANCELED_SUPERVISION" 56 "REMOTE_CANCELED_CONNECTION" 57 "REMOTE_PAUSED_RANGE" 58 "REMOTE_PAUSED_SUPERVISION" 59 "REMOTE_PAUSED_CONNECTION" ;
VAL_ 1465 LRSCDS_CshLgAdjFdRr 0 "Not Selected" 1 "Selected-No Movement" 2 "Forward" 3 "Rearward" ;
VAL_ 1465 LRSCDS_CshBlstrInOut 0 "Not Selected" 1 "Selected-No Movement" 2 "In" 3 "Out" ;
VAL_ 1465 LRSCDS_BkCshBlstInOt 0 "Not Selected" 1 "Selected-No Movement" 2 "Back Bolster In" 3 "Back Bolster Out" 4 "Cushion Bolster In" 5 "Cushion Bolster Out" ;
VAL_ 1465 LRSCDS_BkBlstrInOut 0 "Not Selected" 1 "Selected-No Movement" 2 "In" 3 "Out" ;
VAL_ 1465 LRSCDS_HdrstTltFwdRr 0 "Not Selected" 1 "Selected-No Movement" 2 "Forward" 3 "Rearward" ;
VAL_ 1465 LRSCDS_HdrstFwdRrwd 0 "Not Selected" 1 "Selected-No Movement" 2 "Forward" 3 "Rearward" ;
VAL_ 1465 LRSCDS_HdrstFdRrUDn 0 "Not Selected" 1 "Selected-No Movement" 2 "Up" 3 "Down" 4 "Forward" 5 "Rearward" ;
VAL_ 1465 LRSCDS_DispReq 0 "FALSE" 1 "TRUE" ;
VAL_ 1465 LRSCDS_LmbrUDnFdRr 0 "Not Selected" 1 "Selected-No Movement" 2 "Up" 3 "Down" 4 "Forward" 5 "Rearward" ;
VAL_ 1465 LRSCDS_LmbrFwdRr 0 "Not Selected" 1 "Selected-No Movement" 2 "Forward" 3 "Rearward" ;
VAL_ 1465 LRSCDS_HdrstWngInOt 0 "Not Selected" 1 "Selected-No Movement" 2 "In" 3 "Out" ;
VAL_ 1465 LRSCDS_HdrstUpDn 0 "Not Selected" 1 "Selected-No Movement" 2 "Up" 3 "Down" ;
VAL_ 1465 LRSCDS_MassgIntsty 0 "Massage Off" 1 "Massage Intensity 1" 2 "Massage Intensity 2" 3 "Massage Intensity 3" 4 "Massage Intensity 4" 5 "Massage Intensity 5" 6 "Massage Intensity 6" 7 "Massage Intensity 7" ;
VAL_ 1465 LRSCDS_Massg 0 "Not Selected" 1 "Selected Massage Off" 2 "Selected Massage On" ;
VAL_ 1465 LRSCDS_LmbrUpDwn 0 "Not Selected" 1 "Selected-No Movement" 2 "Up" 3 "Down" ;
VAL_ 1465 SDGPARS_CntrLtSd 0 "OFF" 1 "FAILED" 2 "BLOCKED" 3 "ATTACHED_OBJECT" 4 "NO_OBJECT" 5 "ZONE_1" 6 "ZONE_2" 7 "ZONE_3" 8 "ZONE_4" 9 "ZONE_5" 10 "ZONE_6" 11 "OFF_NO_FAULT" 12 "RESERVED_1" 13 "RESERVED_2" 14 "RESERVED_3" ;
VAL_ 1465 LRSCDS_UprShldrFdRr 0 "Not Selected" 1 "Selected-No Movement" 2 "Forward" 3 "Rearward" ;
VAL_ 1465 LRSCDS_MassgTyp 0 "Massage Off" 1 "Massage Type 1" 2 "Massage Type 2" 3 "Massage Type 3" 4 "Massage Type 4" 5 "Massage Type 5" 6 "Massage Type 6" 7 "Massage Type 7" 8 "Massage Type 8" 9 "Massage Type 9" 10 "Massage Type 10" 11 "Massage Type 11" 12 "Massage Type 12" 13 "Massage Type 13" 14 "Massage Type 14" 15 "Massage Type 15" ;
VAL_ 1465 SDGPARS_FrtLtSd 0 "OFF" 1 "FAILED" 2 "BLOCKED" 3 "ATTACHED_OBJECT" 4 "NO_OBJECT" 5 "ZONE_1" 6 "ZONE_2" 7 "ZONE_3" 8 "ZONE_4" 9 "ZONE_5" 10 "ZONE_6" 11 "OFF_NO_FAULT" 12 "RESERVED_1" 13 "RESERVED_2" 14 "RESERVED_3" ;
VAL_ 1465 SDGPARS_CntrRtSd 0 "OFF" 1 "FAILED" 2 "BLOCKED" 3 "ATTACHED_OBJECT" 4 "NO_OBJECT" 5 "ZONE_1" 6 "ZONE_2" 7 "ZONE_3" 8 "ZONE_4" 9 "ZONE_5" 10 "ZONE_6" 11 "OFF_NO_FAULT" 12 "RESERVED_1" 13 "RESERVED_2" 14 "RESERVED_3" ;
VAL_ 1465 SDGPARS_RrLtSd 0 "OFF" 1 "FAILED" 2 "BLOCKED" 3 "ATTACHED_OBJECT" 4 "NO_OBJECT" 5 "ZONE_1" 6 "ZONE_2" 7 "ZONE_3" 8 "ZONE_4" 9 "ZONE_5" 10 "ZONE_6" 11 "OFF_NO_FAULT" 12 "RESERVED_1" 13 "RESERVED_2" 14 "RESERVED_3" ;
VAL_ 1465 SDGPARS_FrtRtSd 0 "OFF" 1 "FAILED" 2 "BLOCKED" 3 "ATTACHED_OBJECT" 4 "NO_OBJECT" 5 "ZONE_1" 6 "ZONE_2" 7 "ZONE_3" 8 "ZONE_4" 9 "ZONE_5" 10 "ZONE_6" 11 "OFF_NO_FAULT" 12 "RESERVED_1" 13 "RESERVED_2" 14 "RESERVED_3" ;
VAL_ 1465 AirbgStIndOn 0 "FALSE" 1 "TRUE" ;
VAL_ 1465 SDGPARS_RrRtSd 0 "OFF" 1 "FAILED" 2 "BLOCKED" 3 "ATTACHED_OBJECT" 4 "NO_OBJECT" 5 "ZONE_1" 6 "ZONE_2" 7 "ZONE_3" 8 "ZONE_4" 9 "ZONE_5" 10 "ZONE_6" 11 "OFF_NO_FAULT" 12 "RESERVED_1" 13 "RESERVED_2" 14 "RESERVED_3" ;
VAL_ 1483 RFSCDS_CshLgAdjFdRr 0 "Not Selected" 1 "Selected-No Movement" 2 "Forward" 3 "Rearward" ;
VAL_ 1483 RFSCDS_CshBlstrInOut 0 "Not Selected" 1 "Selected-No Movement" 2 "In" 3 "Out" ;
VAL_ 1483 RFSCDS_BkCshBlstInOt 0 "Not Selected" 1 "Selected-No Movement" 2 "Back Bolster In" 3 "Back Bolster Out" 4 "Cushion Bolster In" 5 "Cushion Bolster Out" ;
VAL_ 1483 RFSCDS_BkBlstrInOut 0 "Not Selected" 1 "Selected-No Movement" 2 "In" 3 "Out" ;
VAL_ 1483 RFSCDS_HdrstTltFwdRr 0 "Not Selected" 1 "Selected-No Movement" 2 "Forward" 3 "Rearward" ;
VAL_ 1483 RFSCDS_HdrstFwdRrwd 0 "Not Selected" 1 "Selected-No Movement" 2 "Forward" 3 "Rearward" ;
VAL_ 1483 RFSCDS_HdrstFdRrUDn 0 "Not Selected" 1 "Selected-No Movement" 2 "Up" 3 "Down" 4 "Forward" 5 "Rearward" ;
VAL_ 1483 RFSCDS_DispReq 0 "FALSE" 1 "TRUE" ;
VAL_ 1483 RFSCDS_LmbrUDnFdRr 0 "Not Selected" 1 "Selected-No Movement" 2 "Up" 3 "Down" 4 "Forward" 5 "Rearward" ;
VAL_ 1483 RFSCDS_LmbrFwdRr 0 "Not Selected" 1 "Selected-No Movement" 2 "Forward" 3 "Rearward" ;
VAL_ 1483 RFSCDS_HdrstWngInOt 0 "Not Selected" 1 "Selected-No Movement" 2 "In" 3 "Out" ;
VAL_ 1483 RFSCDS_HdrstUpDn 0 "Not Selected" 1 "Selected-No Movement" 2 "Up" 3 "Down" ;
VAL_ 1483 RFSCDS_MassgIntsty 0 "Massage Off" 1 "Massage Intensity 1" 2 "Massage Intensity 2" 3 "Massage Intensity 3" 4 "Massage Intensity 4" 5 "Massage Intensity 5" 6 "Massage Intensity 6" 7 "Massage Intensity 7" ;
VAL_ 1483 RFSCDS_Massg 0 "Not Selected" 1 "Selected Massage Off" 2 "Selected Massage On" ;
VAL_ 1483 RFSCDS_LmbrUpDwn 0 "Not Selected" 1 "Selected-No Movement" 2 "Up" 3 "Down" ;
VAL_ 1483 RideHghtSeltn1Pndg 0 "FALSE" 1 "TRUE" ;
VAL_ 1483 RFSCDS_UprShldrFdRr 0 "Not Selected" 1 "Selected-No Movement" 2 "Forward" 3 "Rearward" ;
VAL_ 1483 RFSCDS_MassgTyp 0 "Massage Off" 1 "Massage Type 1" 2 "Massage Type 2" 3 "Massage Type 3" 4 "Massage Type 4" 5 "Massage Type 5" 6 "Massage Type 6" 7 "Massage Type 7" 8 "Massage Type 8" 9 "Massage Type 9" 10 "Massage Type 10" 11 "Massage Type 11" 12 "Massage Type 12" 13 "Massage Type 13" 14 "Massage Type 14" 15 "Massage Type 15" ;
VAL_ 1483 RideHghtSeltn5Pndg 0 "FALSE" 1 "TRUE" ;
VAL_ 1483 RideHghtSeltn4Unv 0 "FALSE" 1 "TRUE" ;
VAL_ 1483 RideHghtSeltn4Pndg 0 "FALSE" 1 "TRUE" ;
VAL_ 1483 RideHghtSeltn3Unv 0 "FALSE" 1 "TRUE" ;
VAL_ 1483 RideHghtSeltn3Pndg 0 "FALSE" 1 "TRUE" ;
VAL_ 1483 RideHghtSeltn2Unv 0 "FALSE" 1 "TRUE" ;
VAL_ 1483 RideHghtSeltn2Pndg 0 "FALSE" 1 "TRUE" ;
VAL_ 1483 RideHghtSeltn1Unv 0 "FALSE" 1 "TRUE" ;
VAL_ 1483 OATP_OtsAirTmpCrValAuth_Inv 0 "FALSE" 1 "TRUE" ;
VAL_ 1483 RideHghtSeltn8Unv 0 "FALSE" 1 "TRUE" ;
VAL_ 1483 RideHghtSeltn8Pndg 0 "FALSE" 1 "TRUE" ;
VAL_ 1483 RideHghtSeltn7Unv 0 "FALSE" 1 "TRUE" ;
VAL_ 1483 RideHghtSeltn7Pndg 0 "FALSE" 1 "TRUE" ;
VAL_ 1483 RideHghtSeltn6Unv 0 "FALSE" 1 "TRUE" ;
VAL_ 1483 RideHghtSeltn6Pndg 0 "FALSE" 1 "TRUE" ;
VAL_ 1483 RideHghtSeltn5Unv 0 "FALSE" 1 "TRUE" ;
VAL_ 1484 RRSCDS_CshLgAdjFdRr 0 "Not Selected" 1 "Selected-No Movement" 2 "Forward" 3 "Rearward" ;
VAL_ 1484 RRSCDS_CshBlstrInOut 0 "Not Selected" 1 "Selected-No Movement" 2 "In" 3 "Out" ;
VAL_ 1484 RRSCDS_BkCshBlstInOt 0 "Not Selected" 1 "Selected-No Movement" 2 "Back Bolster In" 3 "Back Bolster Out" 4 "Cushion Bolster In" 5 "Cushion Bolster Out" ;
VAL_ 1484 RRSCDS_BkBlstrInOut 0 "Not Selected" 1 "Selected-No Movement" 2 "In" 3 "Out" ;
VAL_ 1484 RRSCDS_HdrstTltFwdRr 0 "Not Selected" 1 "Selected-No Movement" 2 "Forward" 3 "Rearward" ;
VAL_ 1484 RRSCDS_HdrstFwdRrwd 0 "Not Selected" 1 "Selected-No Movement" 2 "Forward" 3 "Rearward" ;
VAL_ 1484 RRSCDS_HdrstFdRrUDn 0 "Not Selected" 1 "Selected-No Movement" 2 "Up" 3 "Down" 4 "Forward" 5 "Rearward" ;
VAL_ 1484 RRSCDS_DispReq 0 "FALSE" 1 "TRUE" ;
VAL_ 1484 RRSCDS_LmbrUDnFdRr 0 "Not Selected" 1 "Selected-No Movement" 2 "Up" 3 "Down" 4 "Forward" 5 "Rearward" ;
VAL_ 1484 RRSCDS_LmbrFwdRr 0 "Not Selected" 1 "Selected-No Movement" 2 "Forward" 3 "Rearward" ;
VAL_ 1484 RRSCDS_HdrstWngInOt 0 "Not Selected" 1 "Selected-No Movement" 2 "In" 3 "Out" ;
VAL_ 1484 RRSCDS_HdrstUpDn 0 "Not Selected" 1 "Selected-No Movement" 2 "Up" 3 "Down" ;
VAL_ 1484 RRSCDS_MassgIntsty 0 "Massage Off" 1 "Massage Intensity 1" 2 "Massage Intensity 2" 3 "Massage Intensity 3" 4 "Massage Intensity 4" 5 "Massage Intensity 5" 6 "Massage Intensity 6" 7 "Massage Intensity 7" ;
VAL_ 1484 RRSCDS_Massg 0 "Not Selected" 1 "Selected Massage Off" 2 "Selected Massage On" ;
VAL_ 1484 RRSCDS_LmbrUpDwn 0 "Not Selected" 1 "Selected-No Movement" 2 "Up" 3 "Down" ;
VAL_ 1484 RPARS_Lt 0 "OFF" 1 "FAILED" 2 "BLOCKED" 3 "ATTACHED_OBJECT" 4 "NO_OBJECT" 5 "ZONE_1" 6 "ZONE_2" 7 "ZONE_3" 8 "ZONE_4" 9 "ZONE_5" 10 "ZONE_6" 11 "OFF_NO_FAULT" 12 "RESERVED_1" 13 "RESERVED_2" 14 "RESERVED_3" ;
VAL_ 1484 RRSCDS_UprShldrFdRr 0 "Not Selected" 1 "Selected-No Movement" 2 "Forward" 3 "Rearward" ;
VAL_ 1484 RRSCDS_MassgTyp 0 "Massage Off" 1 "Massage Type 1" 2 "Massage Type 2" 3 "Massage Type 3" 4 "Massage Type 4" 5 "Massage Type 5" 6 "Massage Type 6" 7 "Massage Type 7" 8 "Massage Type 8" 9 "Massage Type 9" 10 "Massage Type 10" 11 "Massage Type 11" 12 "Massage Type 12" 13 "Massage Type 13" 14 "Massage Type 14" 15 "Massage Type 15" ;
VAL_ 1484 RPARS_Rt 0 "OFF" 1 "FAILED" 2 "BLOCKED" 3 "ATTACHED_OBJECT" 4 "NO_OBJECT" 5 "ZONE_1" 6 "ZONE_2" 7 "ZONE_3" 8 "ZONE_4" 9 "ZONE_5" 10 "ZONE_6" 11 "OFF_NO_FAULT" 12 "RESERVED_1" 13 "RESERVED_2" 14 "RESERVED_3" ;
VAL_ 1484 RPARS_LtCntr 0 "OFF" 1 "FAILED" 2 "BLOCKED" 3 "ATTACHED_OBJECT" 4 "NO_OBJECT" 5 "ZONE_1" 6 "ZONE_2" 7 "ZONE_3" 8 "ZONE_4" 9 "ZONE_5" 10 "ZONE_6" 11 "OFF_NO_FAULT" 12 "RESERVED_1" 13 "RESERVED_2" 14 "RESERVED_3" ;
VAL_ 1484 eLSDActrTrqPctg_Inv 0 "FALSE" 1 "TRUE" ;
VAL_ 1484 RPARS_RtCntr 0 "OFF" 1 "FAILED" 2 "BLOCKED" 3 "ATTACHED_OBJECT" 4 "NO_OBJECT" 5 "ZONE_1" 6 "ZONE_2" 7 "ZONE_3" 8 "ZONE_4" 9 "ZONE_5" 10 "ZONE_6" 11 "OFF_NO_FAULT" 12 "RESERVED_1" 13 "RESERVED_2" 14 "RESERVED_3" ;
